VERSION ""

NS_ :

BS_:

BU_: VMCU TECU OBDScanT2 IC3 HPCU EMS ECUspare2 ECUspare1 DACU CIOM BBM

BO_ 826 VMCU_BB2_20P: 8 VMCU
 SG_ StartupProhibitStatus_ISig_4 : 8|2@1+ (1,0) [0|0] ""  BBM,IC3
 SG_ RampLevelStatus_ISig_4 : 32|4@1+ (1,0) [0|0] ""  IC3,CIOM
 SG_ KneelingInformation_ISig_4 : 42|4@1+ (1,0) [0|0] ""  BBM,IC3,CIOM
 SG_ FrontAxleInBumperRange_ISig_4 : 40|2@1+ (1,0) [0|0] ""  TECU
 SG_ FerryFunctionStatus_ISig_4 : 2|3@1+ (1,0) [0|0] ""  IC3,CIOM
 SG_ EngPtoConsumesTorque : 10|2@1+ (1,0) [0|0] ""  TECU
 SG_ LiftingControlModeRearAxle_ISig_ : 36|2@1+ (1,0) [0|0] ""  BBM
 SG_ KneelingStatusHMI_ISig_4 : 53|2@1+ (1,0) [0|0] ""  BBM,CIOM
 SG_ SWEngineStop_rqst_ISig_4 : 12|3@1+ (1,0) [0|0] ""  BBM
 SG_ FrontEndPositionStatus_ISig_4 : 18|3@1+ (1,0) [0|0] ""  CIOM
 SG_ LiftingControlModeFrontAxle_ISig : 30|2@1+ (1,0) [0|0] ""  BBM
 SG_ FrontAxleInBumperRange_UB_ISig_4 : 46|1@1+ (1,0) [0|0] ""  TECU,IC3
 SG_ UnevenLoadWarning_ISig_4 : 16|2@1+ (1,0) [0|0] ""  IC3
 SG_ RampHeightOutsideTargetRange_ISi : 27|3@1+ (1,0) [0|0] ""  IC3,CIOM
 SG_ DriveLevelPosUserInteraction_ISi : 48|3@1+ (1,0) [0|0] ""  IC3
 SG_ RearEndPositionStatus_ISig_4 : 24|3@1+ (1,0) [0|0] ""  TECU,CIOM
 SG_ ProhibitControlStatus_ISig_4 : 6|2@1+ (1,0) [0|0] ""  IC3,BBM
 SG_ ChangeKneelACK_ISig_4 : 51|2@1+ (1,0) [0|0] ""  CIOM
 SG_ ParkBrakeApplicationMode2 : 60|4@1+ (1,0) [0|0] ""  IC3
 SG_ RollEndPositionStatus_ISig_4 : 21|3@1+ (1,0) [0|0] ""  CIOM
 SG_ RearAxleInBumperRange_UB_ISig_4 : 47|1@1+ (1,0) [0|0] ""  TECU,IC3
 SG_ ParkBrakeReleaseMode2_ISig_4 : 56|4@1+ (1,0) [0|0] ""  IC3
 SG_ ECSStandbyAllowed_ISig_4 : 0|2@1+ (1,0) [0|0] ""  CIOM
 SG_ RearAxleInBumperRange_ISig_4 : 38|2@1+ (1,0) [0|0] ""  TECU

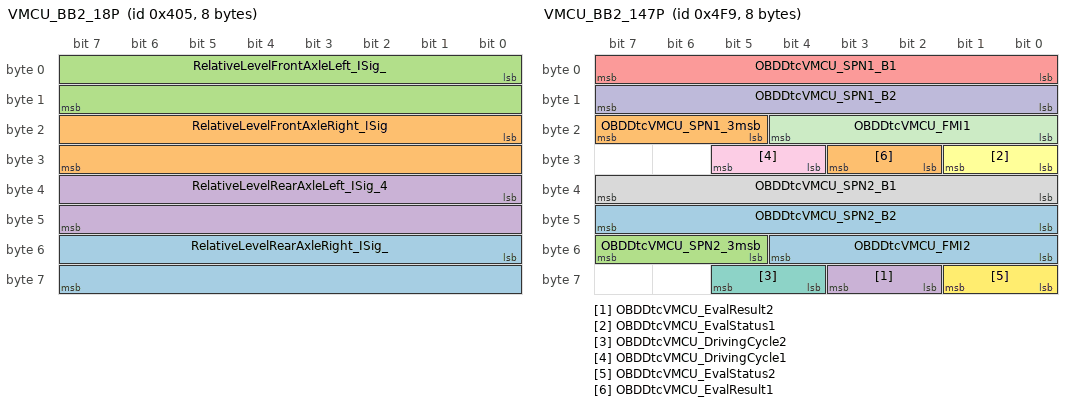
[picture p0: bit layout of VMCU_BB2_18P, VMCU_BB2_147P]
BO_ 1029 VMCU_BB2_18P: 8 VMCU
 SG_ RelativeLevelRearAxleRight_ISig_ : 48|16@1+ (0.1,-3200) [-3200|3353.5] "mm"  BBM
 SG_ RelativeLevelFrontAxleRight_ISig : 16|16@1+ (0.1,-3200) [-3200|3353.5] "mm"  BBM
 SG_ RelativeLevelFrontAxleLeft_ISig_ : 0|16@1+ (0.1,-3200) [-3200|3353.5] "mm"  BBM
 SG_ RelativeLevelRearAxleLeft_ISig_4 : 32|16@1+ (0.1,-3200) [-3200|3353.5] "mm"  BBM

BO_ 1207 VMCU_BB2_148P: 8 VMCU
 SG_ RelativeLevelFrontAxleLeftRaw_IS : 0|16@1+ (0.1,-3200) [-3200|3353.5] "mm"  DACU
 SG_ RelativeLevelFrontAxleRightRaw_I : 16|16@1+ (0.1,-3200) [-3200|3353.5] "mm"  DACU

BO_ 1273 VMCU_BB2_147P: 8 VMCU
 SG_ OBDDtcVMCU_SPN2_B2 : 40|8@1+ (1,0) [0|0] ""  EMS
 SG_ OBDDtcVMCU_SPN1_3msb : 21|3@1+ (1,0) [0|0] ""  EMS
 SG_ OBDDtcVMCU_SPN2_3msb : 53|3@1+ (1,0) [0|0] ""  EMS
 SG_ OBDDtcVMCU_EvalResult2 : 58|2@1+ (1,0) [0|0] ""  EMS
 SG_ OBDDtcVMCU_SPN1_B1 : 0|8@1+ (1,0) [0|0] ""  EMS
 SG_ OBDDtcVMCU_EvalStatus1 : 24|2@1+ (1,0) [0|0] ""  EMS
 SG_ OBDDtcVMCU_DrivingCycle2 : 60|2@1+ (1,0) [0|0] ""  EMS
 SG_ OBDDtcVMCU_SPN2_B1 : 32|8@1+ (1,0) [0|0] ""  EMS
 SG_ OBDDtcVMCU_DrivingCycle1 : 28|2@1+ (1,0) [0|0] ""  EMS
 SG_ OBDDtcVMCU_SPN1_B2 : 8|8@1+ (1,0) [0|0] ""  EMS
 SG_ OBDDtcVMCU_FMI1 : 16|5@1+ (1,0) [0|31] ""  EMS
 SG_ OBDDtcVMCU_EvalStatus2 : 56|2@1+ (1,0) [0|0] ""  EMS
 SG_ OBDDtcVMCU_FMI2 : 48|5@1+ (1,0) [0|31] ""  EMS
 SG_ OBDDtcVMCU_EvalResult1 : 26|2@1+ (1,0) [0|0] ""  EMS

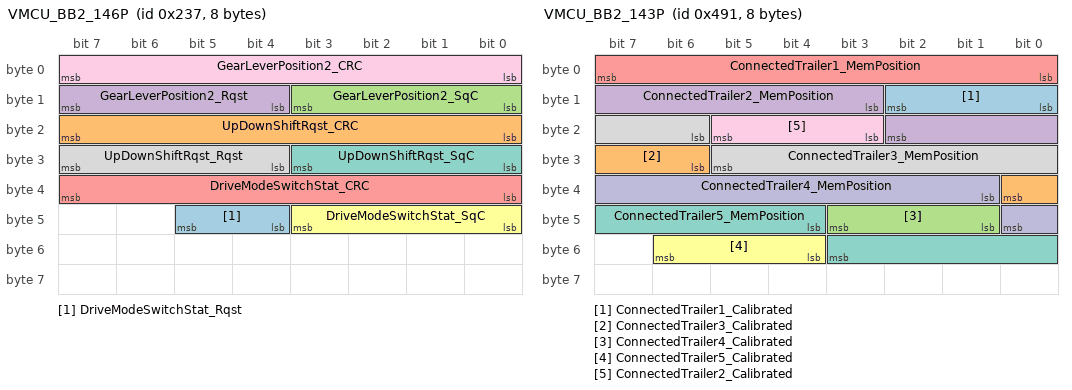
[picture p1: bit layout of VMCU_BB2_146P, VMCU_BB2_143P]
BO_ 567 VMCU_BB2_146P: 8 VMCU
 SG_ DriveModeSwitchStat_Rqst : 44|2@1+ (1,0) [0|0] ""  TECU
 SG_ UpDownShiftRqst_CRC : 16|8@1+ (1,0) [0|255] ""  TECU
 SG_ GearLeverPosition2_SqC : 8|4@1+ (1,0) [0|0] ""  TECU,IC3
 SG_ GearLeverPosition2_Rqst : 12|4@1+ (1,0) [0|0] ""  IC3,TECU
 SG_ DriveModeSwitchStat_CRC : 32|8@1+ (1,0) [0|255] ""  TECU
 SG_ DriveModeSwitchStat_SqC : 40|4@1+ (1,0) [0|0] ""  TECU
 SG_ UpDownShiftRqst_SqC : 24|4@1+ (1,0) [0|0] ""  TECU
 SG_ UpDownShiftRqst_Rqst : 28|4@1+ (1,0) [0|0] ""  TECU
 SG_ GearLeverPosition2_CRC : 0|8@1+ (1,0) [0|255] ""  TECU,IC3

BO_ 1483 VMCU_BB2_145S_FCM: 8 IC3
 SG_ VMCU_BB2_145S_FCS : 0|64@1+ (1,0) [0|0] ""  VMCU

BO_ 1482 VMCU_BB2_145S: 10 VMCU
 SG_ CalDataLoadTrlAxSumP2_YearUTC : 48|8@1+ (1,1985) [1985|2240] "Years"  IC3
 SG_ CalDataLoadTrlAxSumP2_ScaleLoad : 0|16@1+ (2,0) [0|131070] "kg"  IC3
 SG_ CalDataLoadTrlAxSumP2_DayUTC : 64|8@1+ (0.25,0) [0|63.75] "Days"  IC3
 SG_ CalDataLoadTrlAxSumP2_VehicleID : 72|3@1+ (1,0) [0|0] ""  IC3
 SG_ CalDataLoadTrlAxSumP2_QF : 32|16@1+ (1,0) [0|0] ""  IC3
 SG_ CalDataLoadTrlAxSumP2_MonthUTC : 56|8@1+ (1,0) [0|255] "Months"  IC3
 SG_ CalDataLoadTrlAxSumP2_UncalLoad : 16|16@1+ (2,0) [0|131070] "kg"  IC3

BO_ 1407 VMCU_BB2_144S_FCM: 8 IC3
 SG_ VMCU_BB2_144S_FCS : 0|64@1+ (1,0) [0|0] ""  VMCU

BO_ 1406 VMCU_BB2_144S: 10 VMCU
 SG_ CalDataLoadTrlAxSumP1_DayUTC : 64|8@1+ (0.25,0) [0|63.75] "Days"  IC3
 SG_ CalDataLoadTrlAxSumP1_YearUTC : 48|8@1+ (1,1985) [1985|2240] "Years"  IC3
 SG_ CalDataLoadTrlAxSumP1_VehicleID : 72|3@1+ (1,0) [0|0] ""  IC3
 SG_ CalDataLoadTrlAxSumP1_ScaleLoad : 0|16@1+ (2,0) [0|131070] "kg"  IC3
 SG_ CalDataLoadTrlAxSumP1_MonthUTC : 56|8@1+ (1,0) [0|255] "Months"  IC3
 SG_ CalDataLoadTrlAxSumP1_UncalLoad : 16|16@1+ (2,0) [0|131070] "kg"  IC3
 SG_ CalDataLoadTrlAxSumP1_QF : 32|16@1+ (1,0) [0|0] ""  IC3

BO_ 1169 VMCU_BB2_143P: 8 VMCU
 SG_ ConnectedTrailer1_Calibrated : 8|3@1+ (1,0) [0|0] ""  IC3
 SG_ ConnectedTrailer3_Calibrated : 30|3@1+ (1,0) [0|0] ""  IC3
 SG_ ConnectedTrailer4_Calibrated : 41|3@1+ (1,0) [0|0] ""  IC3
 SG_ ConnectedTrailer2_MemPosition : 11|8@1+ (1,0) [0|255] "NotApplicable"  IC3
 SG_ ConnectedTrailer1_MemPosition : 0|8@1+ (1,0) [0|255] "NotApplicable"  IC3
 SG_ ConnectedTrailer5_Calibrated : 52|3@1+ (1,0) [0|0] ""  IC3
 SG_ ConnectedTrailer5_MemPosition : 44|8@1+ (1,0) [0|255] "NotApplicable"  IC3
 SG_ ConnectedTrailer3_MemPosition : 22|8@1+ (1,0) [0|255] "NotApplicable"  IC3
 SG_ ConnectedTrailer2_Calibrated : 19|3@1+ (1,0) [0|0] ""  IC3
 SG_ ConnectedTrailer4_MemPosition : 33|8@1+ (1,0) [0|255] "NotApplicable"  IC3

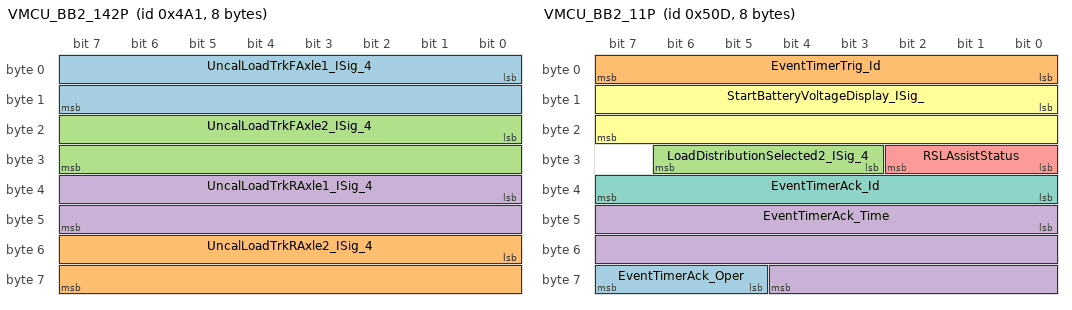
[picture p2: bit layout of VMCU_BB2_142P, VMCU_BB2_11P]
BO_ 1185 VMCU_BB2_142P: 8 VMCU
 SG_ UncalLoadTrkFAxle1_ISig_4 : 0|16@1+ (0.5,0) [0|32767.5] "kg"  IC3
 SG_ UncalLoadTrkRAxle2_ISig_4 : 48|16@1+ (0.5,0) [0|32767.5] "kg"  IC3
 SG_ UncalLoadTrkFAxle2_ISig_4 : 16|16@1+ (0.5,0) [0|32767.5] "kg"  IC3
 SG_ UncalLoadTrkRAxle1_ISig_4 : 32|16@1+ (0.5,0) [0|32767.5] "kg"  IC3

BO_ 1333 VMCU_BB2_141P: 8 VMCU
 SG_ SuspensionGCVW_ISig_4 : 32|16@1+ (10,0) [0|655350] "kg"  IC3
 SG_ SelectedLocalTimeOffset_stat_ISi : 0|32@1+ (1,-86400) [-86400|4294880895] "s"  IC3

BO_ 1597 VMCU_BB2_140P_FCM: 8 IC3
 SG_ VMCU_BB2_140P_FCS : 0|64@1+ (1,0) [0|0] ""  VMCU

BO_ 1596 VMCU_BB2_140P: 21 VMCU
 SG_ SavedUnit20_TrailerName : 0|160@1+ (1,0) [0|0] ""  IC3
 SG_ SavedUnit20_TrailerPosition : 160|3@1+ (1,0) [0|0] ""  IC3

BO_ 1595 VMCU_BB2_139P_FCM: 8 IC3
 SG_ VMCU_BB2_139P_FCS : 0|64@1+ (1,0) [0|0] ""  VMCU

BO_ 1594 VMCU_BB2_139P: 21 VMCU
 SG_ SavedUnit19_TrailerName : 0|160@1+ (1,0) [0|0] ""  IC3
 SG_ SavedUnit19_TrailerPosition : 160|3@1+ (1,0) [0|0] ""  IC3

BO_ 1593 VMCU_BB2_138P_FCM: 8 IC3
 SG_ VMCU_BB2_138P_FCS : 0|64@1+ (1,0) [0|0] ""  VMCU

BO_ 1592 VMCU_BB2_138P: 21 VMCU
 SG_ SavedUnit18_TrailerPosition : 160|3@1+ (1,0) [0|0] ""  IC3
 SG_ SavedUnit18_TrailerName : 0|160@1+ (1,0) [0|0] ""  IC3

BO_ 1591 VMCU_BB2_137P_FCM: 8 IC3
 SG_ VMCU_BB2_137P_FCS : 0|64@1+ (1,0) [0|0] ""  VMCU

BO_ 1590 VMCU_BB2_137P: 21 VMCU
 SG_ SavedUnit17_TrailerPosition : 160|3@1+ (1,0) [0|0] ""  IC3
 SG_ SavedUnit17_TrailerName : 0|160@1+ (1,0) [0|0] ""  IC3

BO_ 1589 VMCU_BB2_136P_FCM: 8 IC3
 SG_ VMCU_BB2_136P_FCS : 0|64@1+ (1,0) [0|0] ""  VMCU

BO_ 1588 VMCU_BB2_136P: 21 VMCU
 SG_ SavedUnit16_TrailerName : 0|160@1+ (1,0) [0|0] ""  IC3
 SG_ SavedUnit16_TrailerPosition : 160|3@1+ (1,0) [0|0] ""  IC3

BO_ 1587 VMCU_BB2_135P_FCM: 8 IC3
 SG_ VMCU_BB2_135P_FCS : 0|64@1+ (1,0) [0|0] ""  VMCU

BO_ 1586 VMCU_BB2_135P: 21 VMCU
 SG_ SavedUnit15_TrailerName : 0|160@1+ (1,0) [0|0] ""  IC3
 SG_ SavedUnit15_TrailerPosition : 160|3@1+ (1,0) [0|0] ""  IC3

BO_ 1585 VMCU_BB2_134P_FCM: 8 IC3
 SG_ VMCU_BB2_134P_FCS : 0|64@1+ (1,0) [0|0] ""  VMCU

BO_ 1584 VMCU_BB2_134P: 21 VMCU
 SG_ SavedUnit14_TrailerPosition : 160|3@1+ (1,0) [0|0] ""  IC3
 SG_ SavedUnit14_TrailerName : 0|160@1+ (1,0) [0|0] ""  IC3

BO_ 1577 VMCU_BB2_133P_FCM: 8 IC3
 SG_ VMCU_BB2_133P_FCS : 0|64@1+ (1,0) [0|0] ""  VMCU

BO_ 1576 VMCU_BB2_133P: 21 VMCU
 SG_ SavedUnit13_TrailerPosition : 160|3@1+ (1,0) [0|0] ""  IC3
 SG_ SavedUnit13_TrailerName : 0|160@1+ (1,0) [0|0] ""  IC3

BO_ 1575 VMCU_BB2_132P_FCM: 8 IC3
 SG_ VMCU_BB2_132P_FCS : 0|64@1+ (1,0) [0|0] ""  VMCU

BO_ 1574 VMCU_BB2_132P: 21 VMCU
 SG_ SavedUnit12_TrailerName : 0|160@1+ (1,0) [0|0] ""  IC3
 SG_ SavedUnit12_TrailerPosition : 160|3@1+ (1,0) [0|0] ""  IC3

BO_ 1573 VMCU_BB2_131P_FCM: 8 IC3
 SG_ VMCU_BB2_131P_FCS : 0|64@1+ (1,0) [0|0] ""  VMCU

BO_ 1572 VMCU_BB2_131P: 21 VMCU
 SG_ SavedUnit11_TrailerPosition : 160|3@1+ (1,0) [0|0] ""  IC3
 SG_ SavedUnit11_TrailerName : 0|160@1+ (1,0) [0|0] ""  IC3

BO_ 1571 VMCU_BB2_130P_FCM: 8 IC3
 SG_ VMCU_BB2_130P_FCS : 0|64@1+ (1,0) [0|0] ""  VMCU

BO_ 1570 VMCU_BB2_130P: 21 VMCU
 SG_ SavedUnit10_TrailerName : 0|160@1+ (1,0) [0|0] ""  IC3
 SG_ SavedUnit10_TrailerPosition : 160|3@1+ (1,0) [0|0] ""  IC3

BO_ 1569 VMCU_BB2_129P_FCM: 8 IC3
 SG_ VMCU_BB2_129P_FCS : 0|64@1+ (1,0) [0|0] ""  VMCU

BO_ 1568 VMCU_BB2_129P: 21 VMCU
 SG_ SavedUnit9_TrailerName : 0|160@1+ (1,0) [0|0] ""  IC3
 SG_ SavedUnit9_TrailerPosition : 160|3@1+ (1,0) [0|0] ""  IC3

BO_ 1567 VMCU_BB2_128P_FCM: 8 IC3
 SG_ VMCU_BB2_128P_FCS : 0|64@1+ (1,0) [0|0] ""  VMCU

BO_ 1566 VMCU_BB2_128P: 21 VMCU
 SG_ SavedUnit8_TrailerName : 0|160@1+ (1,0) [0|0] ""  IC3
 SG_ SavedUnit8_TrailerPosition : 160|3@1+ (1,0) [0|0] ""  IC3

BO_ 1565 VMCU_BB2_127P_FCM: 8 IC3
 SG_ VMCU_BB2_127P_FCS : 0|64@1+ (1,0) [0|0] ""  VMCU

BO_ 1564 VMCU_BB2_127P: 21 VMCU
 SG_ SavedUnit7_TrailerPosition : 160|3@1+ (1,0) [0|0] ""  IC3
 SG_ SavedUnit7_TrailerName : 0|160@1+ (1,0) [0|0] ""  IC3

BO_ 1563 VMCU_BB2_126P_FCM: 8 IC3
 SG_ VMCU_BB2_126P_FCS : 0|64@1+ (1,0) [0|0] ""  VMCU

BO_ 1562 VMCU_BB2_126P: 21 VMCU
 SG_ SavedUnit6_TrailerPosition : 160|3@1+ (1,0) [0|0] ""  IC3
 SG_ SavedUnit6_TrailerName : 0|160@1+ (1,0) [0|0] ""  IC3

BO_ 1561 VMCU_BB2_125P_FCM: 8 IC3
 SG_ VMCU_BB2_125P_FCS : 0|64@1+ (1,0) [0|0] ""  VMCU

BO_ 1560 VMCU_BB2_125P: 21 VMCU
 SG_ SavedUnit5_TrailerName : 0|160@1+ (1,0) [0|0] ""  IC3
 SG_ SavedUnit5_TrailerPosition : 160|3@1+ (1,0) [0|0] ""  IC3

BO_ 1559 VMCU_BB2_124P_FCM: 8 IC3
 SG_ VMCU_BB2_124P_FCS : 0|64@1+ (1,0) [0|0] ""  VMCU

BO_ 1558 VMCU_BB2_124P: 21 VMCU
 SG_ SavedUnit4_TrailerPosition : 160|3@1+ (1,0) [0|0] ""  IC3
 SG_ SavedUnit4_TrailerName : 0|160@1+ (1,0) [0|0] ""  IC3

BO_ 1557 VMCU_BB2_123P_FCM: 8 IC3
 SG_ VMCU_BB2_123P_FCS : 0|64@1+ (1,0) [0|0] ""  VMCU

BO_ 1556 VMCU_BB2_123P: 21 VMCU
 SG_ SavedUnit3_TrailerPosition : 160|3@1+ (1,0) [0|0] ""  IC3
 SG_ SavedUnit3_TrailerName : 0|160@1+ (1,0) [0|0] ""  IC3

BO_ 1555 VMCU_BB2_122P_FCM: 8 IC3
 SG_ VMCU_BB2_122P_FCS : 0|64@1+ (1,0) [0|0] ""  VMCU

BO_ 1554 VMCU_BB2_122P: 21 VMCU
 SG_ SavedUnit2_TrailerName : 0|160@1+ (1,0) [0|0] ""  IC3
 SG_ SavedUnit2_TrailerPosition : 160|3@1+ (1,0) [0|0] ""  IC3

BO_ 1553 VMCU_BB2_121P_FCM: 8 IC3
 SG_ VMCU_BB2_121P_FCS : 0|64@1+ (1,0) [0|0] ""  VMCU

BO_ 1552 VMCU_BB2_121P: 21 VMCU
 SG_ SavedUnit1_TrailerPosition : 160|3@1+ (1,0) [0|0] ""  IC3
 SG_ SavedUnit1_TrailerName : 0|160@1+ (1,0) [0|0] ""  IC3

BO_ 1293 VMCU_BB2_11P: 8 VMCU
 SG_ EventTimerAck_Oper : 61|3@1+ (1,0) [0|0] ""  IC3
 SG_ EventTimerTrig_Id : 0|8@1+ (1,0) [0|0] ""  IC3
 SG_ LoadDistributionSelected2_ISig_4 : 27|4@1+ (1,0) [0|0] ""  IC3
 SG_ EventTimerAck_Time : 40|21@1+ (1,0) [0|2097151] "s"  IC3
 SG_ RSLAssistStatus : 24|3@1+ (1,0) [0|0] ""  TECU
 SG_ StartBatteryVoltageDisplay_ISig_ : 8|16@1+ (0.05,0) [0|3276.75] "V"  IC3
 SG_ EventTimerAck_Id : 32|8@1+ (1,0) [0|0] ""  IC3

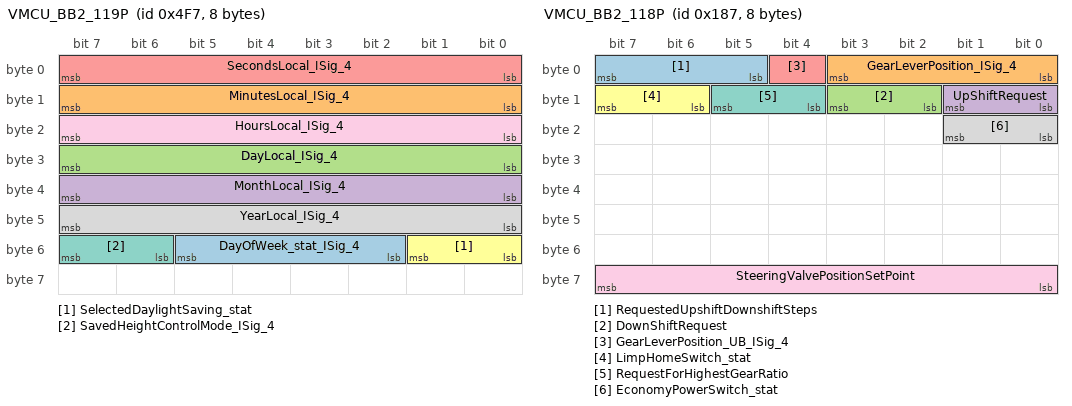
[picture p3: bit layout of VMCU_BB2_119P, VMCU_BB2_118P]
BO_ 1271 VMCU_BB2_119P: 8 VMCU
 SG_ DayOfWeek_stat_ISig_4 : 50|4@1+ (1,0) [0|0] ""  IC3,CIOM
 SG_ MinutesLocal_ISig_4 : 8|8@1+ (1,0) [0|255] "min"  IC3,CIOM
 SG_ DayLocal_ISig_4 : 24|8@1+ (0.25,0) [0|63.75] "Days"  IC3,CIOM
 SG_ MonthLocal_ISig_4 : 32|8@1+ (1,0) [0|255] "Months"  IC3,CIOM
 SG_ SecondsLocal_ISig_4 : 0|8@1+ (0.25,0) [0|63.75] "s"  IC3,CIOM
 SG_ SelectedDaylightSaving_stat : 48|2@1+ (1,0) [0|0] ""  IC3
 SG_ SavedHeightControlMode_ISig_4 : 54|2@1+ (1,0) [0|0] ""  TECU
 SG_ YearLocal_ISig_4 : 40|8@1+ (1,1985) [1985|2240] "Years"  CIOM,IC3
 SG_ HoursLocal_ISig_4 : 16|8@1+ (1,0) [0|255] "h"  IC3,CIOM

BO_ 391 VMCU_BB2_118P: 8 VMCU
 SG_ RequestedUpshiftDownshiftSteps : 5|3@1+ (1,0) [0|0] ""  TECU
 SG_ GearLeverPosition_ISig_4 : 0|4@1+ (1,0) [0|0] ""  TECU,BBM,DACU,IC3
 SG_ DownShiftRequest : 10|2@1+ (1,0) [0|0] ""  TECU
 SG_ UpShiftRequest : 8|2@1+ (1,0) [0|0] ""  TECU
 SG_ GearLeverPosition_UB_ISig_4 : 4|1@1+ (1,0) [0|0] ""  BBM,DACU,IC3,TECU
 SG_ LimpHomeSwitch_stat : 14|2@1+ (1,0) [0|0] ""  TECU
 SG_ RequestForHighestGearRatio : 12|2@1+ (1,0) [0|0] ""  TECU
 SG_ EconomyPowerSwitch_stat : 16|2@1+ (1,0) [0|0] ""  TECU
 SG_ SteeringValvePositionSetPoint : 56|8@1+ (1,0) [0|255] "Percent"  EMS

BO_ 1326 VMCU_BB2_116S_FCM: 8 IC3
 SG_ VMCU_BB2_116S_FCS : 0|64@1+ (1,0) [0|0] ""  VMCU

BO_ 1321 VMCU_BB2_116S: 12 VMCU
 SG_ CalDataLoadP5_ScaleLoad_ISig_4 : 63|16@1+ (0.5,0) [0|32767.5] "kg"  IC3
 SG_ CalDataLoadP5_UncalLoad_ISig_4 : 47|16@1+ (0.5,0) [0|32767.5] "kg"  IC3
 SG_ CalDataLoadP5_sg_UB_ISig_4 : 95|1@1+ (1,0) [0|0] ""  IC3
 SG_ CalDataLoadP5_YearUTC_ISig_4 : 23|8@1+ (1,1985) [1985|2240] "Years"  IC3
 SG_ CalDataLoadP5_VehicleID_ISig_4 : 4|3@1+ (1,0) [0|0] ""  IC3
 SG_ CalDataLoadP5_AxleID_ISig_4 : 0|4@1+ (1,0) [0|0] ""  IC3
 SG_ CalDataLoadP5_DayUTC_ISig_4 : 15|8@1+ (0.25,0) [0|63.75] "Days"  IC3
 SG_ CalDataLoadP5_HoursUTC_ISig_4 : 31|8@1+ (1,0) [0|255] "h"  IC3
 SG_ CalDataLoadP5_MinutesUTC_ISig_4 : 39|8@1+ (1,0) [0|255] "min"  IC3
 SG_ CalDataLoadP5_QF_ISig_4 : 79|16@1+ (1,0) [0|0] ""  IC3
 SG_ CalDataLoadP5_MonthUTC_ISig_4 : 7|8@1+ (1,0) [0|255] "Months"  IC3

BO_ 1325 VMCU_BB2_115S_FCM: 8 IC3
 SG_ VMCU_BB2_115S_FCS : 0|64@1+ (1,0) [0|0] ""  VMCU

BO_ 1320 VMCU_BB2_115S: 12 VMCU
 SG_ CalDataLoadP4_DayUTC_ISig_4 : 7|8@1+ (0.25,0) [0|63.75] "Days"  IC3
 SG_ CalDataLoadP4_ScaleLoad_ISig_4 : 47|16@1+ (0.5,0) [0|32767.5] "kg"  IC3
 SG_ CalDataLoadP4_sg_UB_ISig_4 : 95|1@1+ (1,0) [0|0] ""  IC3
 SG_ CalDataLoadP4_YearUTC_ISig_4 : 23|8@1+ (1,1985) [1985|2240] "Years"  IC3
 SG_ CalDataLoadP4_AxleID_ISig_4 : 0|4@1+ (1,0) [0|0] ""  IC3
 SG_ CalDataLoadP4_UncalLoad_ISig_4 : 63|16@1+ (0.5,0) [0|32767.5] "kg"  IC3
 SG_ CalDataLoadP4_VehicleID_ISig_4 : 4|3@1+ (1,0) [0|0] ""  IC3
 SG_ CalDataLoadP4_MinutesUTC_ISig_4 : 39|8@1+ (1,0) [0|255] "min"  IC3
 SG_ CalDataLoadP4_HoursUTC_ISig_4 : 15|8@1+ (1,0) [0|255] "h"  IC3
 SG_ CalDataLoadP4_MonthUTC_ISig_4 : 31|8@1+ (1,0) [0|255] "Months"  IC3
 SG_ CalDataLoadP4_QF_ISig_4 : 79|16@1+ (1,0) [0|0] ""  IC3

BO_ 1324 VMCU_BB2_114S_FCM: 8 IC3
 SG_ VMCU_BB2_114S_FCS : 0|64@1+ (1,0) [0|0] ""  VMCU

BO_ 1319 VMCU_BB2_114S: 12 VMCU
 SG_ CalDataLoadP3_HoursUTC_ISig_4 : 15|8@1+ (1,0) [0|255] "h"  IC3
 SG_ CalDataLoadP3_YearUTC_ISig_4 : 7|8@1+ (1,1985) [1985|2240] "Years"  IC3
 SG_ CalDataLoadP3_MonthUTC_ISig_4 : 39|8@1+ (1,0) [0|255] "Months"  IC3
 SG_ CalDataLoadP3_DayUTC_ISig_4 : 23|8@1+ (0.25,0) [0|63.75] "Days"  IC3
 SG_ CalDataLoadP3_sg_UB_ISig_4 : 95|1@1+ (1,0) [0|0] ""  IC3
 SG_ CalDataLoadP3_MinutesUTC_ISig_4 : 31|8@1+ (1,0) [0|255] "min"  IC3
 SG_ CalDataLoadP3_QF_ISig_4 : 79|16@1+ (1,0) [0|0] ""  IC3
 SG_ CalDataLoadP3_VehicleID_ISig_4 : 4|3@1+ (1,0) [0|0] ""  IC3
 SG_ CalDataLoadP3_UncalLoad_ISig_4 : 63|16@1+ (0.5,0) [0|32767.5] "kg"  IC3
 SG_ CalDataLoadP3_AxleID_ISig_4 : 0|4@1+ (1,0) [0|0] ""  IC3
 SG_ CalDataLoadP3_ScaleLoad_ISig_4 : 47|16@1+ (0.5,0) [0|32767.5] "kg"  IC3

BO_ 1323 VMCU_BB2_113S_FCM: 8 IC3
 SG_ VMCU_BB2_113S_FCS : 0|64@1+ (1,0) [0|0] ""  VMCU

BO_ 1318 VMCU_BB2_113S: 12 VMCU
 SG_ CalDataLoadP2_MinutesUTC_ISig_4 : 39|8@1+ (1,0) [0|255] "min"  IC3
 SG_ CalDataLoadP2_AxleID_ISig_4 : 0|4@1+ (1,0) [0|0] ""  IC3
 SG_ CalDataLoadP2_YearUTC_ISig_4 : 15|8@1+ (1,1985) [1985|2240] "Years"  IC3
 SG_ CalDataLoadP2_UncalLoad_ISig_4 : 63|16@1+ (0.5,0) [0|32767.5] "kg"  IC3
 SG_ CalDataLoadP2_DayUTC_ISig_4 : 23|8@1+ (0.25,0) [0|63.75] "Days"  IC3
 SG_ CalDataLoadP2_MonthUTC_ISig_4 : 7|8@1+ (1,0) [0|255] "Months"  IC3
 SG_ CalDataLoadP2_VehicleID_ISig_4 : 4|3@1+ (1,0) [0|0] ""  IC3
 SG_ CalDataLoadP2_QF_ISig_4 : 79|16@1+ (1,0) [0|0] ""  IC3
 SG_ CalDataLoadP2_HoursUTC_ISig_4 : 31|8@1+ (1,0) [0|255] "h"  IC3
 SG_ CalDataLoadP2_sg_UB_ISig_4 : 95|1@1+ (1,0) [0|0] ""  IC3
 SG_ CalDataLoadP2_ScaleLoad_ISig_4 : 47|16@1+ (0.5,0) [0|32767.5] "kg"  IC3

BO_ 1322 VMCU_BB2_112S_FCM: 8 IC3
 SG_ VMCU_BB2_112S_FCS : 0|64@1+ (1,0) [0|0] ""  VMCU

BO_ 1317 VMCU_BB2_112S: 12 VMCU
 SG_ CalDataLoadP1_ScaleLoad_ISig_4 : 47|16@1+ (0.5,0) [0|32767.5] "kg"  IC3
 SG_ CalDataLoadP1_YearUTC_ISig_4 : 31|8@1+ (1,1985) [1985|2240] "Years"  IC3
 SG_ CalDataLoadP1_AxleID_ISig_4 : 0|4@1+ (1,0) [0|0] ""  IC3
 SG_ CalDataLoadP1_MonthUTC_ISig_4 : 39|8@1+ (1,0) [0|255] "Months"  IC3
 SG_ CalDataLoadP1_HoursUTC_ISig_4 : 7|8@1+ (1,0) [0|255] "h"  IC3
 SG_ CalDataLoadP1_VehicleID_ISig_4 : 4|3@1+ (1,0) [0|0] ""  IC3
 SG_ CalDataLoadP1_UncalLoad_ISig_4 : 63|16@1+ (0.5,0) [0|32767.5] "kg"  IC3
 SG_ CalDataLoadP1_QF_ISig_4 : 79|16@1+ (1,0) [0|0] ""  IC3
 SG_ CalDataLoadP1_DayUTC_ISig_4 : 23|8@1+ (0.25,0) [0|63.75] "Days"  IC3
 SG_ CalDataLoadP1_sg_UB_ISig_4 : 95|1@1+ (1,0) [0|0] ""  IC3
 SG_ CalDataLoadP1_MinutesUTC_ISig_4 : 15|8@1+ (1,0) [0|255] "min"  IC3

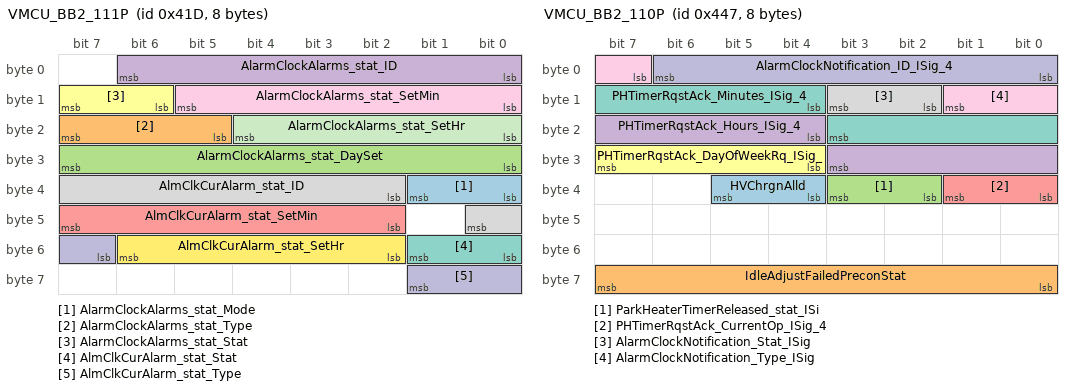
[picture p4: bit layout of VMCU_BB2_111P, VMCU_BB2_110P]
BO_ 1053 VMCU_BB2_111P: 8 VMCU
 SG_ AlarmClockAlarms_stat_Mode : 32|2@1+ (1,0) [0|0] ""  IC3
 SG_ AlarmClockAlarms_stat_Type : 21|3@1+ (1,0) [0|0] ""  IC3
 SG_ AlarmClockAlarms_stat_DaySet : 24|8@1+ (1,0) [0|255] ""  IC3
 SG_ AlarmClockAlarms_stat_ID : 0|7@1+ (1,0) [0|0] ""  IC3
 SG_ AlmClkCurAlarm_stat_SetMin : 42|6@1+ (1,0) [0|63] "min"  IC3,CIOM
 SG_ AlarmClockAlarms_stat_Stat : 14|2@1+ (1,0) [0|0] ""  IC3
 SG_ AlmClkCurAlarm_stat_Stat : 48|2@1+ (1,0) [0|0] ""  CIOM,IC3
 SG_ AlmClkCurAlarm_stat_ID : 34|7@1+ (1,0) [0|0] ""  IC3,CIOM
 SG_ AlarmClockAlarms_stat_SetMin : 8|6@1+ (1,0) [0|63] "min"  IC3
 SG_ AlmClkCurAlarm_stat_Type : 55|3@1+ (1,0) [0|0] ""  IC3,CIOM
 SG_ AlarmClockAlarms_stat_SetHr : 16|5@1+ (1,0) [0|31] "h"  IC3
 SG_ AlmClkCurAlarm_stat_SetHr : 50|5@1+ (1,0) [0|31] "h"  IC3,CIOM

BO_ 1095 VMCU_BB2_110P: 8 VMCU
 SG_ HVChrgnAlld : 36|2@1+ (1,0) [0|0] ""  HPCU
 SG_ IdleAdjustFailedPreconStat : 56|8@1+ (1,0) [0|0] ""  IC3
 SG_ ParkHeaterTimerReleased_stat_ISi : 34|2@1+ (1,0) [0|0] ""  CIOM
 SG_ PHTimerRqstAck_Hours_ISig_4 : 20|8@1+ (1,0) [0|255] "h"  CIOM
 SG_ PHTimerRqstAck_CurrentOp_ISig_4 : 32|2@1+ (1,0) [0|0] ""  CIOM
 SG_ PHTimerRqstAck_DayOfWeekRq_ISig_ : 28|4@1+ (1,0) [0|0] ""  CIOM
 SG_ PHTimerRqstAck_Minutes_ISig_4 : 12|8@1+ (1,0) [0|255] "min"  CIOM
 SG_ AlarmClockNotification_Stat_ISig : 10|2@1+ (1,0) [0|0] ""  CIOM,IC3
 SG_ AlarmClockNotification_Type_ISig : 7|3@1+ (1,0) [0|0] ""  IC3,CIOM
 SG_ AlarmClockNotification_ID_ISig_4 : 0|7@1+ (1,0) [0|0] ""  IC3,CIOM

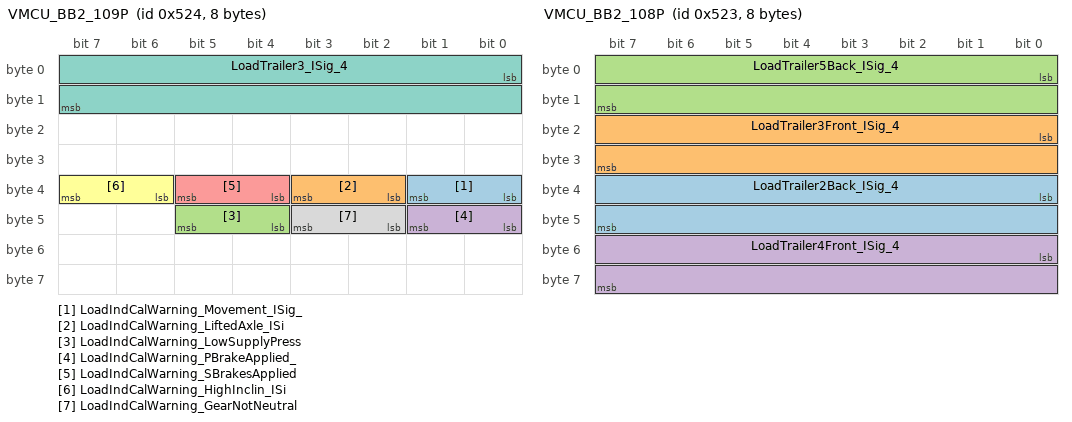
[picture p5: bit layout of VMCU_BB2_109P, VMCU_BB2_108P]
BO_ 1316 VMCU_BB2_109P: 8 VMCU
 SG_ LoadIndCalWarning_Movement_ISig_ : 32|2@1+ (1,0) [0|0] ""  IC3
 SG_ LoadIndCalWarning_LiftedAxle_ISi : 34|2@1+ (1,0) [0|0] ""  IC3
 SG_ LoadIndCalWarning_LowSupplyPress : 44|2@1+ (1,0) [0|0] ""  IC3
 SG_ LoadIndCalWarning_PBrakeApplied_ : 40|2@1+ (1,0) [0|0] ""  IC3
 SG_ LoadIndCalWarning_SBrakesApplied : 36|2@1+ (1,0) [0|0] ""  IC3
 SG_ LoadIndCalWarning_HighInclin_ISi : 38|2@1+ (1,0) [0|0] ""  IC3
 SG_ LoadTrailer3_ISig_4 : 0|16@1+ (2,0) [0|131070] "kg"  IC3,BBM,CIOM
 SG_ LoadIndCalWarning_GearNotNeutral : 42|2@1+ (1,0) [0|0] ""  IC3

BO_ 1315 VMCU_BB2_108P: 8 VMCU
 SG_ LoadTrailer2Back_ISig_4 : 32|16@1+ (2,0) [0|131070] "kg"  IC3
 SG_ LoadTrailer3Front_ISig_4 : 16|16@1+ (2,0) [0|131070] "kg"  IC3
 SG_ LoadTrailer5Back_ISig_4 : 0|16@1+ (2,0) [0|131070] "kg"  IC3
 SG_ LoadTrailer4Front_ISig_4 : 48|16@1+ (2,0) [0|131070] "kg"  IC3

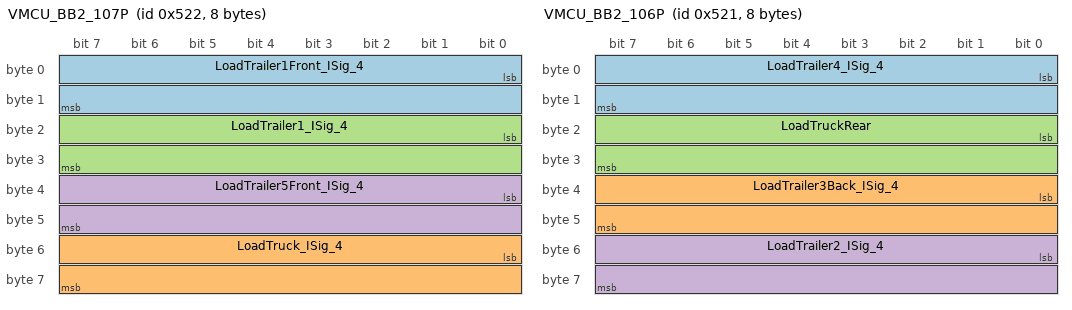
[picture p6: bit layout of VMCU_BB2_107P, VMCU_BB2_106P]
BO_ 1314 VMCU_BB2_107P: 8 VMCU
 SG_ LoadTrailer1Front_ISig_4 : 0|16@1+ (2,0) [0|131070] "kg"  IC3
 SG_ LoadTruck_ISig_4 : 48|16@1+ (2,0) [0|131070] "kg"  IC3,CIOM,DACU,BBM
 SG_ LoadTrailer1_ISig_4 : 16|16@1+ (2,0) [0|131070] "kg"  BBM,IC3,CIOM
 SG_ LoadTrailer5Front_ISig_4 : 32|16@1+ (2,0) [0|131070] "kg"  IC3

BO_ 1313 VMCU_BB2_106P: 8 VMCU
 SG_ LoadTrailer4_ISig_4 : 0|16@1+ (2,0) [0|131070] "kg"  IC3,BBM,CIOM
 SG_ LoadTrailer3Back_ISig_4 : 32|16@1+ (2,0) [0|131070] "kg"  IC3
 SG_ LoadTruckRear : 16|16@1+ (2,0) [0|131070] "kg"  IC3
 SG_ LoadTrailer2_ISig_4 : 48|16@1+ (2,0) [0|131070] "kg"  BBM,CIOM,IC3

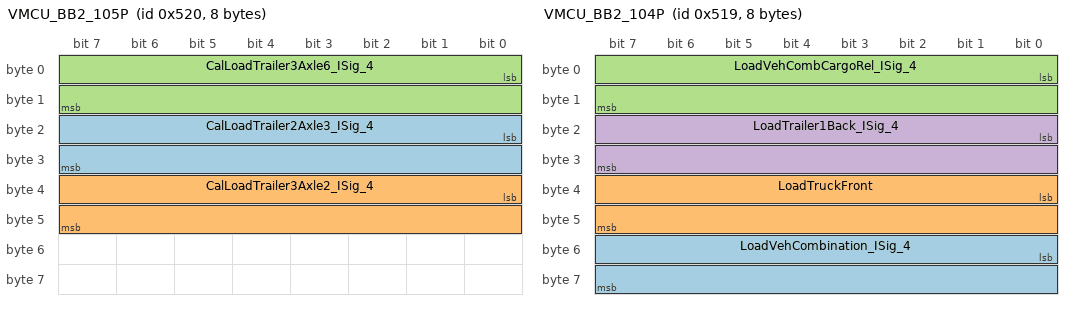
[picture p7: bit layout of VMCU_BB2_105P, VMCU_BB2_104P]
BO_ 1312 VMCU_BB2_105P: 8 VMCU
 SG_ CalLoadTrailer2Axle3_ISig_4 : 16|16@1+ (0.5,0) [0|32767.5] "kg"  IC3,CIOM,BBM
 SG_ CalLoadTrailer3Axle2_ISig_4 : 32|16@1+ (0.5,0) [0|32767.5] "kg"  IC3,CIOM
 SG_ CalLoadTrailer3Axle6_ISig_4 : 0|16@1+ (0.5,0) [0|32767.5] "kg"  IC3,CIOM

BO_ 1305 VMCU_BB2_104P: 8 VMCU
 SG_ LoadVehCombination_ISig_4 : 48|16@1+ (10,0) [0|655350] "kg"  BBM,IC3
 SG_ LoadTruckFront : 32|16@1+ (2,0) [0|131070] "kg"  IC3
 SG_ LoadVehCombCargoRel_ISig_4 : 0|16@1+ (10,-321270) [-321270|334080] "kg"  BBM,IC3
 SG_ LoadTrailer1Back_ISig_4 : 16|16@1+ (2,0) [0|131070] "kg"  IC3

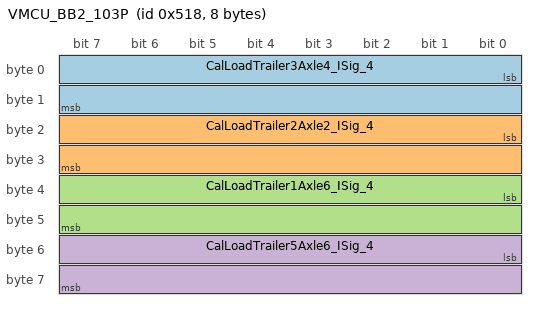
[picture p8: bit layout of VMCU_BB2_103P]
BO_ 1304 VMCU_BB2_103P: 8 VMCU
 SG_ CalLoadTrailer3Axle4_ISig_4 : 0|16@1+ (0.5,0) [0|32767.5] "kg"  CIOM,IC3
 SG_ CalLoadTrailer2Axle2_ISig_4 : 16|16@1+ (0.5,0) [0|32767.5] "kg"  CIOM,IC3,BBM
 SG_ CalLoadTrailer1Axle6_ISig_4 : 32|16@1+ (0.5,0) [0|32767.5] "kg"  CIOM,IC3
 SG_ CalLoadTrailer5Axle6_ISig_4 : 48|16@1+ (0.5,0) [0|32767.5] "kg"  CIOM,IC3

CM_ SG_ 1029 RelativeLevelRearAxleRight_ISig_ "65024 - 65279 Error ; 65280 - 65535 Not available";
CM_ SG_ 1029 RelativeLevelFrontAxleRight_ISig "65024 - 65279 Error ; 65280 - 65535 Not available";
CM_ SG_ 1029 RelativeLevelFrontAxleLeft_ISig_ "65024 - 65279 Error ; 65280 - 65535 Not available";
CM_ SG_ 1029 RelativeLevelRearAxleLeft_ISig_4 "65024 - 65279 Error ; 65280 - 65535 Not available";
CM_ SG_ 1333 SuspensionGCVW_ISig_4 "64256 - 65023 Calculating; 65024 - 65279 Error; 65280 - 65535 NotAvailable;";
CM_ SG_ 1271 MinutesLocal_ISig_4 "254 Error ; 255 Not available";
CM_ SG_ 1271 DayLocal_ISig_4 "254 Error ; 255 Not available";
CM_ SG_ 1271 MonthLocal_ISig_4 "254 Error ; 255 Not available";
CM_ SG_ 1271 SecondsLocal_ISig_4 "254 Error ; 255 Not available";
CM_ SG_ 1271 YearLocal_ISig_4 "254 Error ; 255 Not available";
CM_ SG_ 1271 HoursLocal_ISig_4 "254 Error ; 255 Not available";
CM_ SG_ 1053 AlmClkCurAlarm_stat_SetMin "62 Error ; 63 Not Available";
CM_ SG_ 1053 AlarmClockAlarms_stat_SetMin "62 Error ; 63 Not Available";
CM_ SG_ 1053 AlarmClockAlarms_stat_SetHr "30 Error ; 31 Not Available";
CM_ SG_ 1053 AlmClkCurAlarm_stat_SetHr "30 Error ; 31 Not Available";
CM_ SG_ 1316 LoadTrailer3_ISig_4 "65024 - 65279 Error ; 65280 - 65535 Not Available";
CM_ SG_ 1314 LoadTruck_ISig_4 "65024 - 65279 Error ; 65280 - 65535 Not Available";
CM_ SG_ 1314 LoadTrailer1_ISig_4 "65024 - 65279 Error ; 65280 - 65535 Not Available";
CM_ SG_ 1313 LoadTrailer4_ISig_4 "65024 - 65279 Error ; 65280 - 65535 Not Available";
CM_ SG_ 1313 LoadTrailer2_ISig_4 "65024 - 65279 Error ; 65280 - 65535 Not Available";
CM_ SG_ 1312 CalLoadTrailer2Axle3_ISig_4 "65024 - 65279 Error ; 65280 - 65535 Not available";
CM_ SG_ 1312 CalLoadTrailer3Axle2_ISig_4 "65024 - 65279 Error ; 65280 - 65535 Not available";
CM_ SG_ 1312 CalLoadTrailer3Axle6_ISig_4 "65024 - 65279 Error ; 65280 - 65535 Not available";
CM_ SG_ 1304 CalLoadTrailer3Axle4_ISig_4 "65024 - 65279 Error ; 65280 - 65535 Not available";
CM_ SG_ 1304 CalLoadTrailer2Axle2_ISig_4 "65024 - 65279 Error ; 65280 - 65535 Not available";
CM_ SG_ 1304 CalLoadTrailer1Axle6_ISig_4 "65024 - 65279 Error ; 65280 - 65535 Not available";
CM_ SG_ 1304 CalLoadTrailer5Axle6_ISig_4 "65024 - 65279 Error ; 65280 - 65535 Not available";
BA_DEF_ BO_  "GenMsgStartDelayTime" INT 0 0;
BA_DEF_ BO_  "GenMsgDelayTime" INT 0 0;
BA_DEF_ BO_  "GenMsgCycleTime" INT 0 0;
BA_DEF_ BO_  "GenMsgSendType" ENUM  "Cyclic","NotUsed","NotUsed","NotUsed","NotUsed","NotUsed","NotUsed","IfActive","NoMsgSendType","NotUsed";
BA_DEF_ SG_  "GenSigStartValue" INT 0 0;
BA_DEF_ SG_  "GenSigCycleTimeActive" INT 0 0;
BA_DEF_ SG_  "GenSigCycleTime" INT 0 0;
BA_DEF_ SG_  "GenSigSendType" ENUM  "Cyclic","OnWrite","OnWriteWithRepetition","OnChange","OnChangeWithRepetition","IfActive","IfActiveWithRepetition","NoSigSendType","NotUsed","NotUsed","NotUsed","NotUsed","NotUsed";
BA_DEF_ BO_  "VFrameFormat" ENUM  "StandardCAN","ExtendedCAN","reserved","J1939PG","reserved","reserved","reserved","reserved","reserved","reserved","reserved","reserved","reserved","reserved","StandardCAN_FD","ExtendedCAN_FD";
BA_DEF_ SG_  "SigType" ENUM  "Default","Range","RangeSigned","ASCII","Discrete","Control","ReferencePGN","DTC","StringDelimiter","StringLength","StringLengthControl";
BA_DEF_ SG_  "SeToolVersion_SIGNAL" STRING ;
BA_DEF_ SG_  "SeToolUniqueID_SIGNAL" STRING ;
BA_DEF_ SG_  "SeToolOwnerSigGroup_SIGNAL" STRING ;
BA_DEF_ SG_  "SeToolOwnerSigGroupID_SIGNAL" STRING ;
BA_DEF_ SG_  "SeToolName_SIGNAL" STRING ;
BA_DEF_ SG_  "SeToolItemID_SIGNAL" STRING ;
BA_DEF_ SG_  "SeToolAncestorID_SIGNAL" STRING ;
BA_DEF_ SG_  "Platform_VMCU1_Sig" ENUM  "No","Yes";
BA_DEF_ SG_  "Platform_FactoryIf_Sig" ENUM  "No","Yes";
BA_DEF_ BO_  "NmAsrMessage" ENUM  "No","Yes";
BA_DEF_ SG_  "NeedsUpdateBit" ENUM  "No","Yes";
BA_DEF_ SG_  "MmAnSignal" ENUM  "No","Yes";
BA_DEF_ SG_  "GenSigMaxLatency" INT 0 65535;
BA_DEF_ SG_  "GenSigILSupport" ENUM  "Yes","No";
BA_DEF_ BO_  "GenMsgILSupport" ENUM  "No","Yes";
BA_DEF_ BO_  "DiagUUDTResponse" ENUM  "No","Yes";
BA_DEF_ BO_  "DiagState" ENUM  "No","Yes";
BA_DEF_ BO_  "DiagResponse" ENUM  "No","Yes";
BA_DEF_ BO_  "DiagRequest" ENUM  "No","Yes";
BA_DEF_ BO_  "DiagConnection" HEX 0 65535;
BA_DEF_ BO_  "CanTpSTmin" INT 0 255;
BA_DEF_ BO_  "CanTpFcFrameId" HEX 0 2147483647;
BA_DEF_ BO_  "CanTpBs" INT 0 255;
BA_DEF_ SG_  "SystemSignalLongSymbol" STRING ;
BA_DEF_REL_ BU_SG_REL_  "GenSigTimeoutTime" INT 0 65535;
BA_DEF_REL_ BU_SG_REL_  "GenSigFirstTimeoutTime" INT 0 65535;
BA_DEF_DEF_  "GenMsgStartDelayTime" 0;
BA_DEF_DEF_  "GenMsgDelayTime" 0;
BA_DEF_DEF_  "GenMsgCycleTime" 0;
BA_DEF_DEF_  "GenMsgSendType" "Cyclic";
BA_DEF_DEF_  "GenSigStartValue" 0;
BA_DEF_DEF_  "GenSigCycleTimeActive" 0;
BA_DEF_DEF_  "GenSigCycleTime" 0;
BA_DEF_DEF_  "GenSigSendType" "Cyclic";
BA_DEF_DEF_  "VFrameFormat" "ExtendedCAN";
BA_DEF_DEF_  "SigType" "Default";
BA_DEF_DEF_  "SeToolVersion_SIGNAL" "";
BA_DEF_DEF_  "SeToolUniqueID_SIGNAL" "";
BA_DEF_DEF_  "SeToolOwnerSigGroup_SIGNAL" "";
BA_DEF_DEF_  "SeToolOwnerSigGroupID_SIGNAL" "";
BA_DEF_DEF_  "SeToolName_SIGNAL" "";
BA_DEF_DEF_  "SeToolItemID_SIGNAL" "";
BA_DEF_DEF_  "SeToolAncestorID_SIGNAL" "";
BA_DEF_DEF_  "Platform_VMCU1_Sig" "No";
BA_DEF_DEF_  "Platform_FactoryIf_Sig" "No";
BA_DEF_DEF_  "NmAsrMessage" "No";
BA_DEF_DEF_  "NeedsUpdateBit" "No";
BA_DEF_DEF_  "MmAnSignal" "No";
BA_DEF_DEF_  "GenSigMaxLatency" 0;
BA_DEF_DEF_  "GenSigILSupport" "Yes";
BA_DEF_DEF_  "GenMsgILSupport" "Yes";
BA_DEF_DEF_  "DiagUUDTResponse" "No";
BA_DEF_DEF_  "DiagState" "No";
BA_DEF_DEF_  "DiagResponse" "No";
BA_DEF_DEF_  "DiagRequest" "No";
BA_DEF_DEF_  "DiagConnection" 0;
BA_DEF_DEF_  "CanTpSTmin" 0;
BA_DEF_DEF_  "CanTpFcFrameId" 2147483647;
BA_DEF_DEF_  "CanTpBs" 255;
BA_DEF_DEF_REL_ "GenSigTimeoutTime" 0;
BA_DEF_DEF_REL_ "GenSigFirstTimeoutTime" 0;
BA_DEF_DEF_  "SystemSignalLongSymbol" "";
BA_ "VFrameFormat" BO_ 826 0;
BA_ "GenMsgCycleTime" BO_ 826 50;
BA_ "GenMsgStartDelayTime" BO_ 826 20;
BA_ "VFrameFormat" BO_ 1029 0;
BA_ "GenMsgCycleTime" BO_ 1029 100;
BA_ "GenMsgStartDelayTime" BO_ 1029 15;
BA_ "VFrameFormat" BO_ 1207 0;
BA_ "GenMsgCycleTime" BO_ 1207 100;
BA_ "VFrameFormat" BO_ 1273 0;
BA_ "GenMsgCycleTime" BO_ 1273 500;
BA_ "GenMsgStartDelayTime" BO_ 1273 125;
BA_ "VFrameFormat" BO_ 567 0;
BA_ "GenMsgCycleTime" BO_ 567 20;
BA_ "GenMsgStartDelayTime" BO_ 567 15;
BA_ "GenMsgILSupport" BO_ 1483 0;
BA_ "VFrameFormat" BO_ 1483 0;
BA_ "GenMsgSendType" BO_ 1483 8;
BA_ "CanTpFcFrameId" BO_ 1482 1483;
BA_ "VFrameFormat" BO_ 1482 0;
BA_ "GenMsgSendType" BO_ 1482 8;
BA_ "GenMsgDelayTime" BO_ 1482 20;
BA_ "GenMsgStartDelayTime" BO_ 1482 50;
BA_ "GenMsgILSupport" BO_ 1407 0;
BA_ "VFrameFormat" BO_ 1407 0;
BA_ "GenMsgSendType" BO_ 1407 8;
BA_ "CanTpFcFrameId" BO_ 1406 1407;
BA_ "VFrameFormat" BO_ 1406 0;
BA_ "GenMsgSendType" BO_ 1406 8;
BA_ "GenMsgDelayTime" BO_ 1406 20;
BA_ "GenMsgStartDelayTime" BO_ 1406 50;
BA_ "VFrameFormat" BO_ 1169 0;
BA_ "GenMsgCycleTime" BO_ 1169 500;
BA_ "GenMsgStartDelayTime" BO_ 1169 155;
BA_ "VFrameFormat" BO_ 1185 0;
BA_ "GenMsgCycleTime" BO_ 1185 500;
BA_ "GenMsgStartDelayTime" BO_ 1185 140;
BA_ "VFrameFormat" BO_ 1333 0;
BA_ "GenMsgCycleTime" BO_ 1333 1000;
BA_ "GenMsgILSupport" BO_ 1597 0;
BA_ "VFrameFormat" BO_ 1597 0;
BA_ "GenMsgSendType" BO_ 1597 8;
BA_ "CanTpFcFrameId" BO_ 1596 1597;
BA_ "VFrameFormat" BO_ 1596 0;
BA_ "GenMsgCycleTime" BO_ 1596 10000;
BA_ "GenMsgStartDelayTime" BO_ 1596 2250;
BA_ "GenMsgILSupport" BO_ 1595 0;
BA_ "VFrameFormat" BO_ 1595 0;
BA_ "GenMsgSendType" BO_ 1595 8;
BA_ "CanTpFcFrameId" BO_ 1594 1595;
BA_ "VFrameFormat" BO_ 1594 0;
BA_ "GenMsgCycleTime" BO_ 1594 10000;
BA_ "GenMsgStartDelayTime" BO_ 1594 2155;
BA_ "GenMsgILSupport" BO_ 1593 0;
BA_ "VFrameFormat" BO_ 1593 0;
BA_ "GenMsgSendType" BO_ 1593 8;
BA_ "CanTpFcFrameId" BO_ 1592 1593;
BA_ "VFrameFormat" BO_ 1592 0;
BA_ "GenMsgCycleTime" BO_ 1592 10000;
BA_ "GenMsgStartDelayTime" BO_ 1592 2050;
BA_ "GenMsgILSupport" BO_ 1591 0;
BA_ "VFrameFormat" BO_ 1591 0;
BA_ "GenMsgSendType" BO_ 1591 8;
BA_ "CanTpFcFrameId" BO_ 1590 1591;
BA_ "VFrameFormat" BO_ 1590 0;
BA_ "GenMsgCycleTime" BO_ 1590 10000;
BA_ "GenMsgStartDelayTime" BO_ 1590 1955;
BA_ "GenMsgILSupport" BO_ 1589 0;
BA_ "VFrameFormat" BO_ 1589 0;
BA_ "GenMsgSendType" BO_ 1589 8;
BA_ "CanTpFcFrameId" BO_ 1588 1589;
BA_ "VFrameFormat" BO_ 1588 0;
BA_ "GenMsgCycleTime" BO_ 1588 10000;
BA_ "GenMsgStartDelayTime" BO_ 1588 1850;
BA_ "GenMsgILSupport" BO_ 1587 0;
BA_ "VFrameFormat" BO_ 1587 0;
BA_ "GenMsgSendType" BO_ 1587 8;
BA_ "CanTpFcFrameId" BO_ 1586 1587;
BA_ "VFrameFormat" BO_ 1586 0;
BA_ "GenMsgCycleTime" BO_ 1586 10000;
BA_ "GenMsgStartDelayTime" BO_ 1586 1700;
BA_ "GenMsgILSupport" BO_ 1585 0;
BA_ "VFrameFormat" BO_ 1585 0;
BA_ "GenMsgSendType" BO_ 1585 8;
BA_ "CanTpFcFrameId" BO_ 1584 1585;
BA_ "VFrameFormat" BO_ 1584 0;
BA_ "GenMsgCycleTime" BO_ 1584 10000;
BA_ "GenMsgStartDelayTime" BO_ 1584 1605;
BA_ "GenMsgILSupport" BO_ 1577 0;
BA_ "VFrameFormat" BO_ 1577 0;
BA_ "GenMsgSendType" BO_ 1577 8;
BA_ "CanTpFcFrameId" BO_ 1576 1577;
BA_ "VFrameFormat" BO_ 1576 0;
BA_ "GenMsgCycleTime" BO_ 1576 10000;
BA_ "GenMsgStartDelayTime" BO_ 1576 1500;
BA_ "GenMsgILSupport" BO_ 1575 0;
BA_ "VFrameFormat" BO_ 1575 0;
BA_ "GenMsgSendType" BO_ 1575 8;
BA_ "CanTpFcFrameId" BO_ 1574 1575;
BA_ "VFrameFormat" BO_ 1574 0;
BA_ "GenMsgCycleTime" BO_ 1574 10000;
BA_ "GenMsgStartDelayTime" BO_ 1574 1350;
BA_ "GenMsgILSupport" BO_ 1573 0;
BA_ "VFrameFormat" BO_ 1573 0;
BA_ "GenMsgSendType" BO_ 1573 8;
BA_ "CanTpFcFrameId" BO_ 1572 1573;
BA_ "VFrameFormat" BO_ 1572 0;
BA_ "GenMsgCycleTime" BO_ 1572 10000;
BA_ "GenMsgStartDelayTime" BO_ 1572 1255;
BA_ "GenMsgILSupport" BO_ 1571 0;
BA_ "VFrameFormat" BO_ 1571 0;
BA_ "GenMsgSendType" BO_ 1571 8;
BA_ "CanTpFcFrameId" BO_ 1570 1571;
BA_ "VFrameFormat" BO_ 1570 0;
BA_ "GenMsgCycleTime" BO_ 1570 10000;
BA_ "GenMsgStartDelayTime" BO_ 1570 1150;
BA_ "GenMsgILSupport" BO_ 1569 0;
BA_ "VFrameFormat" BO_ 1569 0;
BA_ "GenMsgSendType" BO_ 1569 8;
BA_ "CanTpFcFrameId" BO_ 1568 1569;
BA_ "VFrameFormat" BO_ 1568 0;
BA_ "GenMsgCycleTime" BO_ 1568 10000;
BA_ "GenMsgStartDelayTime" BO_ 1568 1000;
BA_ "GenMsgILSupport" BO_ 1567 0;
BA_ "VFrameFormat" BO_ 1567 0;
BA_ "GenMsgSendType" BO_ 1567 8;
BA_ "CanTpFcFrameId" BO_ 1566 1567;
BA_ "VFrameFormat" BO_ 1566 0;
BA_ "GenMsgCycleTime" BO_ 1566 10000;
BA_ "GenMsgStartDelayTime" BO_ 1566 905;
BA_ "GenMsgILSupport" BO_ 1565 0;
BA_ "VFrameFormat" BO_ 1565 0;
BA_ "GenMsgSendType" BO_ 1565 8;
BA_ "CanTpFcFrameId" BO_ 1564 1565;
BA_ "VFrameFormat" BO_ 1564 0;
BA_ "GenMsgCycleTime" BO_ 1564 10000;
BA_ "GenMsgStartDelayTime" BO_ 1564 800;
BA_ "GenMsgILSupport" BO_ 1563 0;
BA_ "VFrameFormat" BO_ 1563 0;
BA_ "GenMsgSendType" BO_ 1563 8;
BA_ "CanTpFcFrameId" BO_ 1562 1563;
BA_ "VFrameFormat" BO_ 1562 0;
BA_ "GenMsgCycleTime" BO_ 1562 10000;
BA_ "GenMsgStartDelayTime" BO_ 1562 650;
BA_ "GenMsgILSupport" BO_ 1561 0;
BA_ "VFrameFormat" BO_ 1561 0;
BA_ "GenMsgSendType" BO_ 1561 8;
BA_ "CanTpFcFrameId" BO_ 1560 1561;
BA_ "VFrameFormat" BO_ 1560 0;
BA_ "GenMsgCycleTime" BO_ 1560 10000;
BA_ "GenMsgStartDelayTime" BO_ 1560 555;
BA_ "GenMsgILSupport" BO_ 1559 0;
BA_ "VFrameFormat" BO_ 1559 0;
BA_ "GenMsgSendType" BO_ 1559 8;
BA_ "CanTpFcFrameId" BO_ 1558 1559;
BA_ "VFrameFormat" BO_ 1558 0;
BA_ "GenMsgCycleTime" BO_ 1558 10000;
BA_ "GenMsgStartDelayTime" BO_ 1558 400;
BA_ "GenMsgILSupport" BO_ 1557 0;
BA_ "VFrameFormat" BO_ 1557 0;
BA_ "GenMsgSendType" BO_ 1557 8;
BA_ "CanTpFcFrameId" BO_ 1556 1557;
BA_ "VFrameFormat" BO_ 1556 0;
BA_ "GenMsgCycleTime" BO_ 1556 10000;
BA_ "GenMsgStartDelayTime" BO_ 1556 305;
BA_ "GenMsgILSupport" BO_ 1555 0;
BA_ "VFrameFormat" BO_ 1555 0;
BA_ "GenMsgSendType" BO_ 1555 8;
BA_ "CanTpFcFrameId" BO_ 1554 1555;
BA_ "VFrameFormat" BO_ 1554 0;
BA_ "GenMsgCycleTime" BO_ 1554 10000;
BA_ "GenMsgStartDelayTime" BO_ 1554 200;
BA_ "GenMsgILSupport" BO_ 1553 0;
BA_ "VFrameFormat" BO_ 1553 0;
BA_ "GenMsgSendType" BO_ 1553 8;
BA_ "CanTpFcFrameId" BO_ 1552 1553;
BA_ "VFrameFormat" BO_ 1552 0;
BA_ "GenMsgCycleTime" BO_ 1552 10000;
BA_ "GenMsgStartDelayTime" BO_ 1552 100;
BA_ "VFrameFormat" BO_ 1293 0;
BA_ "GenMsgCycleTime" BO_ 1293 250;
BA_ "GenMsgStartDelayTime" BO_ 1293 50;
BA_ "VFrameFormat" BO_ 1271 0;
BA_ "GenMsgCycleTime" BO_ 1271 200;
BA_ "GenMsgStartDelayTime" BO_ 1271 5;
BA_ "VFrameFormat" BO_ 391 0;
BA_ "GenMsgCycleTime" BO_ 391 20;
BA_ "GenMsgStartDelayTime" BO_ 391 5;
BA_ "GenMsgILSupport" BO_ 1326 0;
BA_ "VFrameFormat" BO_ 1326 0;
BA_ "GenMsgSendType" BO_ 1326 8;
BA_ "CanTpFcFrameId" BO_ 1321 1326;
BA_ "VFrameFormat" BO_ 1321 0;
BA_ "GenMsgSendType" BO_ 1321 8;
BA_ "GenMsgDelayTime" BO_ 1321 100;
BA_ "GenMsgILSupport" BO_ 1325 0;
BA_ "VFrameFormat" BO_ 1325 0;
BA_ "GenMsgSendType" BO_ 1325 8;
BA_ "CanTpFcFrameId" BO_ 1320 1325;
BA_ "VFrameFormat" BO_ 1320 0;
BA_ "GenMsgSendType" BO_ 1320 8;
BA_ "GenMsgDelayTime" BO_ 1320 100;
BA_ "GenMsgILSupport" BO_ 1324 0;
BA_ "VFrameFormat" BO_ 1324 0;
BA_ "GenMsgSendType" BO_ 1324 8;
BA_ "CanTpFcFrameId" BO_ 1319 1324;
BA_ "VFrameFormat" BO_ 1319 0;
BA_ "GenMsgSendType" BO_ 1319 8;
BA_ "GenMsgDelayTime" BO_ 1319 100;
BA_ "GenMsgILSupport" BO_ 1323 0;
BA_ "VFrameFormat" BO_ 1323 0;
BA_ "GenMsgSendType" BO_ 1323 8;
BA_ "CanTpFcFrameId" BO_ 1318 1323;
BA_ "VFrameFormat" BO_ 1318 0;
BA_ "GenMsgSendType" BO_ 1318 8;
BA_ "GenMsgDelayTime" BO_ 1318 100;
BA_ "GenMsgILSupport" BO_ 1322 0;
BA_ "VFrameFormat" BO_ 1322 0;
BA_ "GenMsgSendType" BO_ 1322 8;
BA_ "CanTpFcFrameId" BO_ 1317 1322;
BA_ "VFrameFormat" BO_ 1317 0;
BA_ "GenMsgSendType" BO_ 1317 8;
BA_ "GenMsgDelayTime" BO_ 1317 100;
BA_ "VFrameFormat" BO_ 1053 0;
BA_ "GenMsgCycleTime" BO_ 1053 150;
BA_ "GenMsgStartDelayTime" BO_ 1053 45;
BA_ "VFrameFormat" BO_ 1095 0;
BA_ "GenMsgCycleTime" BO_ 1095 100;
BA_ "GenMsgStartDelayTime" BO_ 1095 35;
BA_ "VFrameFormat" BO_ 1316 0;
BA_ "GenMsgCycleTime" BO_ 1316 1000;
BA_ "GenMsgStartDelayTime" BO_ 1316 210;
BA_ "VFrameFormat" BO_ 1315 0;
BA_ "GenMsgCycleTime" BO_ 1315 1000;
BA_ "GenMsgStartDelayTime" BO_ 1315 205;
BA_ "VFrameFormat" BO_ 1314 0;
BA_ "GenMsgCycleTime" BO_ 1314 1000;
BA_ "GenMsgStartDelayTime" BO_ 1314 190;
BA_ "VFrameFormat" BO_ 1313 0;
BA_ "GenMsgCycleTime" BO_ 1313 1000;
BA_ "GenMsgStartDelayTime" BO_ 1313 180;
BA_ "VFrameFormat" BO_ 1312 0;
BA_ "GenMsgCycleTime" BO_ 1312 1000;
BA_ "GenMsgStartDelayTime" BO_ 1312 165;
BA_ "VFrameFormat" BO_ 1305 0;
BA_ "GenMsgCycleTime" BO_ 1305 1000;
BA_ "GenMsgStartDelayTime" BO_ 1305 145;
BA_ "VFrameFormat" BO_ 1304 0;
BA_ "GenMsgCycleTime" BO_ 1304 1000;
BA_ "GenMsgStartDelayTime" BO_ 1304 130;
BA_ "GenSigCycleTime" SG_ 826 StartupProhibitStatus_ISig_4 100;
BA_ "GenSigCycleTimeActive" SG_ 826 StartupProhibitStatus_ISig_4 100;
BA_ "GenSigStartValue" SG_ 826 StartupProhibitStatus_ISig_4 3;
BA_ "GenSigMaxLatency" SG_ 826 StartupProhibitStatus_ISig_4 117;
BA_ "Platform_VMCU1_Sig" SG_ 826 StartupProhibitStatus_ISig_4 1;
BA_ "GenSigCycleTime" SG_ 826 RampLevelStatus_ISig_4 100;
BA_ "GenSigCycleTimeActive" SG_ 826 RampLevelStatus_ISig_4 100;
BA_ "GenSigStartValue" SG_ 826 RampLevelStatus_ISig_4 15;
BA_ "GenSigMaxLatency" SG_ 826 RampLevelStatus_ISig_4 117;
BA_ "Platform_VMCU1_Sig" SG_ 826 RampLevelStatus_ISig_4 1;
BA_ "GenSigCycleTime" SG_ 826 KneelingInformation_ISig_4 100;
BA_ "GenSigCycleTimeActive" SG_ 826 KneelingInformation_ISig_4 100;
BA_ "GenSigStartValue" SG_ 826 KneelingInformation_ISig_4 15;
BA_ "Platform_VMCU1_Sig" SG_ 826 KneelingInformation_ISig_4 1;
BA_ "GenSigCycleTime" SG_ 826 FrontAxleInBumperRange_ISig_4 100;
BA_ "GenSigCycleTimeActive" SG_ 826 FrontAxleInBumperRange_ISig_4 100;
BA_ "GenSigStartValue" SG_ 826 FrontAxleInBumperRange_ISig_4 3;
BA_ "NeedsUpdateBit" SG_ 826 FrontAxleInBumperRange_ISig_4 1;
BA_ "Platform_VMCU1_Sig" SG_ 826 FrontAxleInBumperRange_ISig_4 1;
BA_ "SeToolAncestorID_SIGNAL" SG_ 826 FrontAxleInBumperRange_ISig_4 "x0000001D04149915";
BA_ "SeToolItemID_SIGNAL" SG_ 826 FrontAxleInBumperRange_ISig_4 "x0000001D04149915";
BA_ "SeToolName_SIGNAL" SG_ 826 FrontAxleInBumperRange_ISig_4 "FrontAxleInBumperRange";
BA_ "SeToolVersion_SIGNAL" SG_ 826 FrontAxleInBumperRange_ISig_4 "1";
BA_ "GenSigCycleTime" SG_ 826 FerryFunctionStatus_ISig_4 100;
BA_ "GenSigCycleTimeActive" SG_ 826 FerryFunctionStatus_ISig_4 100;
BA_ "GenSigStartValue" SG_ 826 FerryFunctionStatus_ISig_4 7;
BA_ "GenSigMaxLatency" SG_ 826 FerryFunctionStatus_ISig_4 117;
BA_ "Platform_VMCU1_Sig" SG_ 826 FerryFunctionStatus_ISig_4 1;
BA_ "GenSigCycleTime" SG_ 826 EngPtoConsumesTorque 100;
BA_ "GenSigCycleTimeActive" SG_ 826 EngPtoConsumesTorque 100;
BA_ "GenSigStartValue" SG_ 826 EngPtoConsumesTorque 3;
BA_ "Platform_VMCU1_Sig" SG_ 826 EngPtoConsumesTorque 1;
BA_ "GenSigCycleTime" SG_ 826 LiftingControlModeRearAxle_ISig_ 100;
BA_ "GenSigCycleTimeActive" SG_ 826 LiftingControlModeRearAxle_ISig_ 100;
BA_ "GenSigStartValue" SG_ 826 LiftingControlModeRearAxle_ISig_ 3;
BA_ "Platform_VMCU1_Sig" SG_ 826 LiftingControlModeRearAxle_ISig_ 1;
BA_ "SeToolAncestorID_SIGNAL" SG_ 826 LiftingControlModeRearAxle_ISig_ "x0000001D04149A4E";
BA_ "SeToolItemID_SIGNAL" SG_ 826 LiftingControlModeRearAxle_ISig_ "x0000001D04149A4E";
BA_ "SeToolName_SIGNAL" SG_ 826 LiftingControlModeRearAxle_ISig_ "LiftingControlModeRearAxle";
BA_ "SeToolVersion_SIGNAL" SG_ 826 LiftingControlModeRearAxle_ISig_ "1";
BA_ "SystemSignalLongSymbol" SG_ 826 LiftingControlModeRearAxle_ISig_ "LiftingControlModeRearAxle_ISig_4";
BA_ "GenSigCycleTime" SG_ 826 KneelingStatusHMI_ISig_4 100;
BA_ "GenSigCycleTimeActive" SG_ 826 KneelingStatusHMI_ISig_4 100;
BA_ "GenSigStartValue" SG_ 826 KneelingStatusHMI_ISig_4 3;
BA_ "Platform_VMCU1_Sig" SG_ 826 KneelingStatusHMI_ISig_4 1;
BA_ "GenSigCycleTime" SG_ 826 SWEngineStop_rqst_ISig_4 100;
BA_ "GenSigCycleTimeActive" SG_ 826 SWEngineStop_rqst_ISig_4 100;
BA_ "GenSigStartValue" SG_ 826 SWEngineStop_rqst_ISig_4 7;
BA_ "Platform_VMCU1_Sig" SG_ 826 SWEngineStop_rqst_ISig_4 1;
BA_ "GenSigCycleTime" SG_ 826 FrontEndPositionStatus_ISig_4 100;
BA_ "GenSigCycleTimeActive" SG_ 826 FrontEndPositionStatus_ISig_4 100;
BA_ "GenSigStartValue" SG_ 826 FrontEndPositionStatus_ISig_4 7;
BA_ "GenSigMaxLatency" SG_ 826 FrontEndPositionStatus_ISig_4 117;
BA_ "Platform_VMCU1_Sig" SG_ 826 FrontEndPositionStatus_ISig_4 1;
BA_ "GenSigCycleTime" SG_ 826 LiftingControlModeFrontAxle_ISig 100;
BA_ "GenSigCycleTimeActive" SG_ 826 LiftingControlModeFrontAxle_ISig 100;
BA_ "GenSigStartValue" SG_ 826 LiftingControlModeFrontAxle_ISig 3;
BA_ "Platform_VMCU1_Sig" SG_ 826 LiftingControlModeFrontAxle_ISig 1;
BA_ "SeToolAncestorID_SIGNAL" SG_ 826 LiftingControlModeFrontAxle_ISig "x0000001D04149903";
BA_ "SeToolItemID_SIGNAL" SG_ 826 LiftingControlModeFrontAxle_ISig "x0000001D04149903";
BA_ "SeToolName_SIGNAL" SG_ 826 LiftingControlModeFrontAxle_ISig "LiftingControlModeFrontAxle";
BA_ "SeToolVersion_SIGNAL" SG_ 826 LiftingControlModeFrontAxle_ISig "1";
BA_ "SystemSignalLongSymbol" SG_ 826 LiftingControlModeFrontAxle_ISig "LiftingControlModeFrontAxle_ISig_4";
BA_ "GenSigSendType" SG_ 826 FrontAxleInBumperRange_UB_ISig_4 7;
BA_ "Platform_VMCU1_Sig" SG_ 826 FrontAxleInBumperRange_UB_ISig_4 1;
BA_ "GenSigCycleTime" SG_ 826 UnevenLoadWarning_ISig_4 100;
BA_ "GenSigCycleTimeActive" SG_ 826 UnevenLoadWarning_ISig_4 100;
BA_ "GenSigStartValue" SG_ 826 UnevenLoadWarning_ISig_4 3;
BA_ "GenSigMaxLatency" SG_ 826 UnevenLoadWarning_ISig_4 117;
BA_ "Platform_VMCU1_Sig" SG_ 826 UnevenLoadWarning_ISig_4 1;
BA_ "GenSigCycleTime" SG_ 826 RampHeightOutsideTargetRange_ISi 100;
BA_ "GenSigCycleTimeActive" SG_ 826 RampHeightOutsideTargetRange_ISi 100;
BA_ "GenSigStartValue" SG_ 826 RampHeightOutsideTargetRange_ISi 7;
BA_ "GenSigMaxLatency" SG_ 826 RampHeightOutsideTargetRange_ISi 117;
BA_ "Platform_VMCU1_Sig" SG_ 826 RampHeightOutsideTargetRange_ISi 1;
BA_ "SystemSignalLongSymbol" SG_ 826 RampHeightOutsideTargetRange_ISi "RampHeightOutsideTargetRange_ISig_4";
BA_ "GenSigCycleTime" SG_ 826 DriveLevelPosUserInteraction_ISi 100;
BA_ "GenSigCycleTimeActive" SG_ 826 DriveLevelPosUserInteraction_ISi 100;
BA_ "GenSigStartValue" SG_ 826 DriveLevelPosUserInteraction_ISi 7;
BA_ "Platform_VMCU1_Sig" SG_ 826 DriveLevelPosUserInteraction_ISi 1;
BA_ "SystemSignalLongSymbol" SG_ 826 DriveLevelPosUserInteraction_ISi "DriveLevelPosUserInteraction_ISig_4";
BA_ "GenSigCycleTime" SG_ 826 RearEndPositionStatus_ISig_4 100;
BA_ "GenSigCycleTimeActive" SG_ 826 RearEndPositionStatus_ISig_4 100;
BA_ "GenSigStartValue" SG_ 826 RearEndPositionStatus_ISig_4 7;
BA_ "GenSigMaxLatency" SG_ 826 RearEndPositionStatus_ISig_4 117;
BA_ "Platform_VMCU1_Sig" SG_ 826 RearEndPositionStatus_ISig_4 1;
BA_ "GenSigCycleTime" SG_ 826 ProhibitControlStatus_ISig_4 100;
BA_ "GenSigCycleTimeActive" SG_ 826 ProhibitControlStatus_ISig_4 100;
BA_ "GenSigStartValue" SG_ 826 ProhibitControlStatus_ISig_4 3;
BA_ "GenSigMaxLatency" SG_ 826 ProhibitControlStatus_ISig_4 117;
BA_ "Platform_VMCU1_Sig" SG_ 826 ProhibitControlStatus_ISig_4 1;
BA_ "GenSigCycleTime" SG_ 826 ChangeKneelACK_ISig_4 100;
BA_ "GenSigCycleTimeActive" SG_ 826 ChangeKneelACK_ISig_4 100;
BA_ "GenSigStartValue" SG_ 826 ChangeKneelACK_ISig_4 3;
BA_ "Platform_VMCU1_Sig" SG_ 826 ChangeKneelACK_ISig_4 1;
BA_ "GenSigCycleTime" SG_ 826 ParkBrakeApplicationMode2 100;
BA_ "GenSigCycleTimeActive" SG_ 826 ParkBrakeApplicationMode2 100;
BA_ "GenSigStartValue" SG_ 826 ParkBrakeApplicationMode2 15;
BA_ "GenSigCycleTime" SG_ 826 RollEndPositionStatus_ISig_4 100;
BA_ "GenSigCycleTimeActive" SG_ 826 RollEndPositionStatus_ISig_4 100;
BA_ "GenSigStartValue" SG_ 826 RollEndPositionStatus_ISig_4 7;
BA_ "GenSigMaxLatency" SG_ 826 RollEndPositionStatus_ISig_4 117;
BA_ "Platform_VMCU1_Sig" SG_ 826 RollEndPositionStatus_ISig_4 1;
BA_ "GenSigSendType" SG_ 826 RearAxleInBumperRange_UB_ISig_4 7;
BA_ "Platform_VMCU1_Sig" SG_ 826 RearAxleInBumperRange_UB_ISig_4 1;
BA_ "GenSigCycleTime" SG_ 826 ParkBrakeReleaseMode2_ISig_4 100;
BA_ "GenSigCycleTimeActive" SG_ 826 ParkBrakeReleaseMode2_ISig_4 100;
BA_ "GenSigStartValue" SG_ 826 ParkBrakeReleaseMode2_ISig_4 15;
BA_ "GenSigCycleTime" SG_ 826 ECSStandbyAllowed_ISig_4 100;
BA_ "GenSigCycleTimeActive" SG_ 826 ECSStandbyAllowed_ISig_4 100;
BA_ "GenSigStartValue" SG_ 826 ECSStandbyAllowed_ISig_4 3;
BA_ "Platform_VMCU1_Sig" SG_ 826 ECSStandbyAllowed_ISig_4 1;
BA_ "GenSigCycleTime" SG_ 826 RearAxleInBumperRange_ISig_4 100;
BA_ "GenSigCycleTimeActive" SG_ 826 RearAxleInBumperRange_ISig_4 100;
BA_ "GenSigStartValue" SG_ 826 RearAxleInBumperRange_ISig_4 3;
BA_ "NeedsUpdateBit" SG_ 826 RearAxleInBumperRange_ISig_4 1;
BA_ "Platform_VMCU1_Sig" SG_ 826 RearAxleInBumperRange_ISig_4 1;
BA_ "SeToolAncestorID_SIGNAL" SG_ 826 RearAxleInBumperRange_ISig_4 "x0000001D04149986";
BA_ "SeToolItemID_SIGNAL" SG_ 826 RearAxleInBumperRange_ISig_4 "x0000001D04149986";
BA_ "SeToolName_SIGNAL" SG_ 826 RearAxleInBumperRange_ISig_4 "RearAxleInBumperRange";
BA_ "SeToolVersion_SIGNAL" SG_ 826 RearAxleInBumperRange_ISig_4 "1";
BA_ "GenSigCycleTime" SG_ 1029 RelativeLevelRearAxleRight_ISig_ 100;
BA_ "GenSigCycleTimeActive" SG_ 1029 RelativeLevelRearAxleRight_ISig_ 100;
BA_ "GenSigStartValue" SG_ 1029 RelativeLevelRearAxleRight_ISig_ 65535;
BA_ "Platform_VMCU1_Sig" SG_ 1029 RelativeLevelRearAxleRight_ISig_ 1;
BA_ "SeToolAncestorID_SIGNAL" SG_ 1029 RelativeLevelRearAxleRight_ISig_ "x0000001D0412EE40";
BA_ "SeToolItemID_SIGNAL" SG_ 1029 RelativeLevelRearAxleRight_ISig_ "x0000001D04384E50";
BA_ "SeToolName_SIGNAL" SG_ 1029 RelativeLevelRearAxleRight_ISig_ "RelativeLevelRearAxleRight";
BA_ "SeToolVersion_SIGNAL" SG_ 1029 RelativeLevelRearAxleRight_ISig_ "2";
BA_ "SystemSignalLongSymbol" SG_ 1029 RelativeLevelRearAxleRight_ISig_ "RelativeLevelRearAxleRight_ISig_4";
BA_ "GenSigCycleTime" SG_ 1029 RelativeLevelFrontAxleRight_ISig 100;
BA_ "GenSigCycleTimeActive" SG_ 1029 RelativeLevelFrontAxleRight_ISig 100;
BA_ "GenSigStartValue" SG_ 1029 RelativeLevelFrontAxleRight_ISig 65535;
BA_ "Platform_VMCU1_Sig" SG_ 1029 RelativeLevelFrontAxleRight_ISig 1;
BA_ "SeToolAncestorID_SIGNAL" SG_ 1029 RelativeLevelFrontAxleRight_ISig "x0000001D0412EE3C";
BA_ "SeToolItemID_SIGNAL" SG_ 1029 RelativeLevelFrontAxleRight_ISig "x0000001D04384E33";
BA_ "SeToolName_SIGNAL" SG_ 1029 RelativeLevelFrontAxleRight_ISig "RelativeLevelFrontAxleRight";
BA_ "SeToolVersion_SIGNAL" SG_ 1029 RelativeLevelFrontAxleRight_ISig "2";
BA_ "SystemSignalLongSymbol" SG_ 1029 RelativeLevelFrontAxleRight_ISig "RelativeLevelFrontAxleRight_ISig_4";
BA_ "GenSigCycleTime" SG_ 1029 RelativeLevelFrontAxleLeft_ISig_ 100;
BA_ "GenSigCycleTimeActive" SG_ 1029 RelativeLevelFrontAxleLeft_ISig_ 100;
BA_ "GenSigStartValue" SG_ 1029 RelativeLevelFrontAxleLeft_ISig_ 65535;
BA_ "Platform_VMCU1_Sig" SG_ 1029 RelativeLevelFrontAxleLeft_ISig_ 1;
BA_ "SeToolAncestorID_SIGNAL" SG_ 1029 RelativeLevelFrontAxleLeft_ISig_ "x0000001D0412EE39";
BA_ "SeToolItemID_SIGNAL" SG_ 1029 RelativeLevelFrontAxleLeft_ISig_ "x0000001D04384DFD";
BA_ "SeToolName_SIGNAL" SG_ 1029 RelativeLevelFrontAxleLeft_ISig_ "RelativeLevelFrontAxleLeft";
BA_ "SeToolVersion_SIGNAL" SG_ 1029 RelativeLevelFrontAxleLeft_ISig_ "2";
BA_ "SystemSignalLongSymbol" SG_ 1029 RelativeLevelFrontAxleLeft_ISig_ "RelativeLevelFrontAxleLeft_ISig_4";
BA_ "GenSigCycleTime" SG_ 1029 RelativeLevelRearAxleLeft_ISig_4 100;
BA_ "GenSigCycleTimeActive" SG_ 1029 RelativeLevelRearAxleLeft_ISig_4 100;
BA_ "GenSigStartValue" SG_ 1029 RelativeLevelRearAxleLeft_ISig_4 65535;
BA_ "Platform_VMCU1_Sig" SG_ 1029 RelativeLevelRearAxleLeft_ISig_4 1;
BA_ "SeToolAncestorID_SIGNAL" SG_ 1029 RelativeLevelRearAxleLeft_ISig_4 "x0000001D0412EE3E";
BA_ "SeToolItemID_SIGNAL" SG_ 1029 RelativeLevelRearAxleLeft_ISig_4 "x0000001D04384E3D";
BA_ "SeToolName_SIGNAL" SG_ 1029 RelativeLevelRearAxleLeft_ISig_4 "RelativeLevelRearAxleLeft";
BA_ "SeToolVersion_SIGNAL" SG_ 1029 RelativeLevelRearAxleLeft_ISig_4 "2";
BA_ "GenSigCycleTime" SG_ 1207 RelativeLevelFrontAxleLeftRaw_IS 100;
BA_ "GenSigCycleTimeActive" SG_ 1207 RelativeLevelFrontAxleLeftRaw_IS 100;
BA_ "GenSigStartValue" SG_ 1207 RelativeLevelFrontAxleLeftRaw_IS 65535;
BA_ "SystemSignalLongSymbol" SG_ 1207 RelativeLevelFrontAxleLeftRaw_IS "RelativeLevelFrontAxleLeftRaw_ISig_4";
BA_ "GenSigCycleTime" SG_ 1207 RelativeLevelFrontAxleRightRaw_I 100;
BA_ "GenSigCycleTimeActive" SG_ 1207 RelativeLevelFrontAxleRightRaw_I 100;
BA_ "GenSigStartValue" SG_ 1207 RelativeLevelFrontAxleRightRaw_I 65535;
BA_ "SystemSignalLongSymbol" SG_ 1207 RelativeLevelFrontAxleRightRaw_I "RelativeLevelFrontAxleRightRaw_ISig_4";
BA_ "GenSigCycleTime" SG_ 1273 OBDDtcVMCU_SPN2_B2 100;
BA_ "GenSigCycleTimeActive" SG_ 1273 OBDDtcVMCU_SPN2_B2 100;
BA_ "GenSigStartValue" SG_ 1273 OBDDtcVMCU_SPN2_B2 255;
BA_ "GenSigCycleTime" SG_ 1273 OBDDtcVMCU_SPN1_3msb 100;
BA_ "GenSigCycleTimeActive" SG_ 1273 OBDDtcVMCU_SPN1_3msb 100;
BA_ "GenSigStartValue" SG_ 1273 OBDDtcVMCU_SPN1_3msb 7;
BA_ "GenSigCycleTime" SG_ 1273 OBDDtcVMCU_SPN2_3msb 100;
BA_ "GenSigCycleTimeActive" SG_ 1273 OBDDtcVMCU_SPN2_3msb 100;
BA_ "GenSigStartValue" SG_ 1273 OBDDtcVMCU_SPN2_3msb 7;
BA_ "GenSigCycleTime" SG_ 1273 OBDDtcVMCU_EvalResult2 100;
BA_ "GenSigCycleTimeActive" SG_ 1273 OBDDtcVMCU_EvalResult2 100;
BA_ "GenSigStartValue" SG_ 1273 OBDDtcVMCU_EvalResult2 3;
BA_ "GenSigCycleTime" SG_ 1273 OBDDtcVMCU_SPN1_B1 100;
BA_ "GenSigCycleTimeActive" SG_ 1273 OBDDtcVMCU_SPN1_B1 100;
BA_ "GenSigStartValue" SG_ 1273 OBDDtcVMCU_SPN1_B1 255;
BA_ "GenSigCycleTime" SG_ 1273 OBDDtcVMCU_EvalStatus1 100;
BA_ "GenSigCycleTimeActive" SG_ 1273 OBDDtcVMCU_EvalStatus1 100;
BA_ "GenSigStartValue" SG_ 1273 OBDDtcVMCU_EvalStatus1 3;
BA_ "GenSigCycleTime" SG_ 1273 OBDDtcVMCU_DrivingCycle2 100;
BA_ "GenSigCycleTimeActive" SG_ 1273 OBDDtcVMCU_DrivingCycle2 100;
BA_ "GenSigStartValue" SG_ 1273 OBDDtcVMCU_DrivingCycle2 3;
BA_ "GenSigCycleTime" SG_ 1273 OBDDtcVMCU_SPN2_B1 100;
BA_ "GenSigCycleTimeActive" SG_ 1273 OBDDtcVMCU_SPN2_B1 100;
BA_ "GenSigStartValue" SG_ 1273 OBDDtcVMCU_SPN2_B1 255;
BA_ "GenSigCycleTime" SG_ 1273 OBDDtcVMCU_DrivingCycle1 100;
BA_ "GenSigCycleTimeActive" SG_ 1273 OBDDtcVMCU_DrivingCycle1 100;
BA_ "GenSigStartValue" SG_ 1273 OBDDtcVMCU_DrivingCycle1 3;
BA_ "GenSigCycleTime" SG_ 1273 OBDDtcVMCU_SPN1_B2 100;
BA_ "GenSigCycleTimeActive" SG_ 1273 OBDDtcVMCU_SPN1_B2 100;
BA_ "GenSigStartValue" SG_ 1273 OBDDtcVMCU_SPN1_B2 255;
BA_ "GenSigCycleTime" SG_ 1273 OBDDtcVMCU_FMI1 100;
BA_ "GenSigCycleTimeActive" SG_ 1273 OBDDtcVMCU_FMI1 100;
BA_ "GenSigStartValue" SG_ 1273 OBDDtcVMCU_FMI1 31;
BA_ "GenSigCycleTime" SG_ 1273 OBDDtcVMCU_EvalStatus2 100;
BA_ "GenSigCycleTimeActive" SG_ 1273 OBDDtcVMCU_EvalStatus2 100;
BA_ "GenSigStartValue" SG_ 1273 OBDDtcVMCU_EvalStatus2 3;
BA_ "GenSigCycleTime" SG_ 1273 OBDDtcVMCU_FMI2 100;
BA_ "GenSigCycleTimeActive" SG_ 1273 OBDDtcVMCU_FMI2 100;
BA_ "GenSigStartValue" SG_ 1273 OBDDtcVMCU_FMI2 31;
BA_ "GenSigCycleTime" SG_ 1273 OBDDtcVMCU_EvalResult1 100;
BA_ "GenSigCycleTimeActive" SG_ 1273 OBDDtcVMCU_EvalResult1 100;
BA_ "GenSigStartValue" SG_ 1273 OBDDtcVMCU_EvalResult1 3;
BA_ "GenSigCycleTime" SG_ 567 DriveModeSwitchStat_Rqst 100;
BA_ "GenSigCycleTimeActive" SG_ 567 DriveModeSwitchStat_Rqst 100;
BA_ "GenSigStartValue" SG_ 567 DriveModeSwitchStat_Rqst 3;
BA_ "GenSigCycleTime" SG_ 567 UpDownShiftRqst_CRC 100;
BA_ "GenSigCycleTimeActive" SG_ 567 UpDownShiftRqst_CRC 100;
BA_ "GenSigCycleTime" SG_ 567 GearLeverPosition2_SqC 100;
BA_ "GenSigCycleTimeActive" SG_ 567 GearLeverPosition2_SqC 100;
BA_ "GenSigCycleTime" SG_ 567 GearLeverPosition2_Rqst 100;
BA_ "GenSigCycleTimeActive" SG_ 567 GearLeverPosition2_Rqst 100;
BA_ "GenSigStartValue" SG_ 567 GearLeverPosition2_Rqst 15;
BA_ "GenSigCycleTime" SG_ 567 DriveModeSwitchStat_CRC 100;
BA_ "GenSigCycleTimeActive" SG_ 567 DriveModeSwitchStat_CRC 100;
BA_ "GenSigCycleTime" SG_ 567 DriveModeSwitchStat_SqC 100;
BA_ "GenSigCycleTimeActive" SG_ 567 DriveModeSwitchStat_SqC 100;
BA_ "GenSigCycleTime" SG_ 567 UpDownShiftRqst_SqC 100;
BA_ "GenSigCycleTimeActive" SG_ 567 UpDownShiftRqst_SqC 100;
BA_ "GenSigCycleTime" SG_ 567 UpDownShiftRqst_Rqst 100;
BA_ "GenSigCycleTimeActive" SG_ 567 UpDownShiftRqst_Rqst 100;
BA_ "GenSigStartValue" SG_ 567 UpDownShiftRqst_Rqst 15;
BA_ "GenSigCycleTime" SG_ 567 GearLeverPosition2_CRC 100;
BA_ "GenSigCycleTimeActive" SG_ 567 GearLeverPosition2_CRC 100;
BA_ "GenSigSendType" SG_ 1483 VMCU_BB2_145S_FCS 7;
BA_ "GenSigSendType" SG_ 1482 CalDataLoadTrlAxSumP2_YearUTC 1;
BA_ "GenSigCycleTime" SG_ 1482 CalDataLoadTrlAxSumP2_YearUTC 100;
BA_ "GenSigCycleTimeActive" SG_ 1482 CalDataLoadTrlAxSumP2_YearUTC 100;
BA_ "GenSigStartValue" SG_ 1482 CalDataLoadTrlAxSumP2_YearUTC 255;
BA_ "GenSigSendType" SG_ 1482 CalDataLoadTrlAxSumP2_ScaleLoad 1;
BA_ "GenSigCycleTime" SG_ 1482 CalDataLoadTrlAxSumP2_ScaleLoad 100;
BA_ "GenSigCycleTimeActive" SG_ 1482 CalDataLoadTrlAxSumP2_ScaleLoad 100;
BA_ "GenSigStartValue" SG_ 1482 CalDataLoadTrlAxSumP2_ScaleLoad 65535;
BA_ "GenSigSendType" SG_ 1482 CalDataLoadTrlAxSumP2_DayUTC 1;
BA_ "GenSigCycleTime" SG_ 1482 CalDataLoadTrlAxSumP2_DayUTC 100;
BA_ "GenSigCycleTimeActive" SG_ 1482 CalDataLoadTrlAxSumP2_DayUTC 100;
BA_ "GenSigStartValue" SG_ 1482 CalDataLoadTrlAxSumP2_DayUTC 255;
BA_ "GenSigSendType" SG_ 1482 CalDataLoadTrlAxSumP2_VehicleID 1;
BA_ "GenSigCycleTime" SG_ 1482 CalDataLoadTrlAxSumP2_VehicleID 100;
BA_ "GenSigCycleTimeActive" SG_ 1482 CalDataLoadTrlAxSumP2_VehicleID 100;
BA_ "GenSigStartValue" SG_ 1482 CalDataLoadTrlAxSumP2_VehicleID 7;
BA_ "GenSigSendType" SG_ 1482 CalDataLoadTrlAxSumP2_QF 1;
BA_ "GenSigCycleTime" SG_ 1482 CalDataLoadTrlAxSumP2_QF 100;
BA_ "GenSigCycleTimeActive" SG_ 1482 CalDataLoadTrlAxSumP2_QF 100;
BA_ "GenSigStartValue" SG_ 1482 CalDataLoadTrlAxSumP2_QF 65535;
BA_ "GenSigSendType" SG_ 1482 CalDataLoadTrlAxSumP2_MonthUTC 1;
BA_ "GenSigCycleTime" SG_ 1482 CalDataLoadTrlAxSumP2_MonthUTC 100;
BA_ "GenSigCycleTimeActive" SG_ 1482 CalDataLoadTrlAxSumP2_MonthUTC 100;
BA_ "GenSigStartValue" SG_ 1482 CalDataLoadTrlAxSumP2_MonthUTC 255;
BA_ "GenSigSendType" SG_ 1482 CalDataLoadTrlAxSumP2_UncalLoad 1;
BA_ "GenSigCycleTime" SG_ 1482 CalDataLoadTrlAxSumP2_UncalLoad 100;
BA_ "GenSigCycleTimeActive" SG_ 1482 CalDataLoadTrlAxSumP2_UncalLoad 100;
BA_ "GenSigStartValue" SG_ 1482 CalDataLoadTrlAxSumP2_UncalLoad 65535;
BA_ "GenSigSendType" SG_ 1407 VMCU_BB2_144S_FCS 7;
BA_ "GenSigSendType" SG_ 1406 CalDataLoadTrlAxSumP1_DayUTC 1;
BA_ "GenSigCycleTime" SG_ 1406 CalDataLoadTrlAxSumP1_DayUTC 100;
BA_ "GenSigCycleTimeActive" SG_ 1406 CalDataLoadTrlAxSumP1_DayUTC 100;
BA_ "GenSigStartValue" SG_ 1406 CalDataLoadTrlAxSumP1_DayUTC 255;
BA_ "GenSigSendType" SG_ 1406 CalDataLoadTrlAxSumP1_YearUTC 1;
BA_ "GenSigCycleTime" SG_ 1406 CalDataLoadTrlAxSumP1_YearUTC 100;
BA_ "GenSigCycleTimeActive" SG_ 1406 CalDataLoadTrlAxSumP1_YearUTC 100;
BA_ "GenSigStartValue" SG_ 1406 CalDataLoadTrlAxSumP1_YearUTC 255;
BA_ "GenSigSendType" SG_ 1406 CalDataLoadTrlAxSumP1_VehicleID 1;
BA_ "GenSigCycleTime" SG_ 1406 CalDataLoadTrlAxSumP1_VehicleID 100;
BA_ "GenSigCycleTimeActive" SG_ 1406 CalDataLoadTrlAxSumP1_VehicleID 100;
BA_ "GenSigStartValue" SG_ 1406 CalDataLoadTrlAxSumP1_VehicleID 7;
BA_ "GenSigSendType" SG_ 1406 CalDataLoadTrlAxSumP1_ScaleLoad 1;
BA_ "GenSigCycleTime" SG_ 1406 CalDataLoadTrlAxSumP1_ScaleLoad 100;
BA_ "GenSigCycleTimeActive" SG_ 1406 CalDataLoadTrlAxSumP1_ScaleLoad 100;
BA_ "GenSigStartValue" SG_ 1406 CalDataLoadTrlAxSumP1_ScaleLoad 65535;
BA_ "GenSigSendType" SG_ 1406 CalDataLoadTrlAxSumP1_MonthUTC 1;
BA_ "GenSigCycleTime" SG_ 1406 CalDataLoadTrlAxSumP1_MonthUTC 100;
BA_ "GenSigCycleTimeActive" SG_ 1406 CalDataLoadTrlAxSumP1_MonthUTC 100;
BA_ "GenSigStartValue" SG_ 1406 CalDataLoadTrlAxSumP1_MonthUTC 255;
BA_ "GenSigSendType" SG_ 1406 CalDataLoadTrlAxSumP1_UncalLoad 1;
BA_ "GenSigCycleTime" SG_ 1406 CalDataLoadTrlAxSumP1_UncalLoad 100;
BA_ "GenSigCycleTimeActive" SG_ 1406 CalDataLoadTrlAxSumP1_UncalLoad 100;
BA_ "GenSigStartValue" SG_ 1406 CalDataLoadTrlAxSumP1_UncalLoad 65535;
BA_ "GenSigSendType" SG_ 1406 CalDataLoadTrlAxSumP1_QF 1;
BA_ "GenSigCycleTime" SG_ 1406 CalDataLoadTrlAxSumP1_QF 100;
BA_ "GenSigCycleTimeActive" SG_ 1406 CalDataLoadTrlAxSumP1_QF 100;
BA_ "GenSigStartValue" SG_ 1406 CalDataLoadTrlAxSumP1_QF 65535;
BA_ "GenSigCycleTime" SG_ 1169 ConnectedTrailer1_Calibrated 100;
BA_ "GenSigCycleTimeActive" SG_ 1169 ConnectedTrailer1_Calibrated 100;
BA_ "GenSigStartValue" SG_ 1169 ConnectedTrailer1_Calibrated 7;
BA_ "GenSigCycleTime" SG_ 1169 ConnectedTrailer3_Calibrated 100;
BA_ "GenSigCycleTimeActive" SG_ 1169 ConnectedTrailer3_Calibrated 100;
BA_ "GenSigStartValue" SG_ 1169 ConnectedTrailer3_Calibrated 7;
BA_ "GenSigCycleTime" SG_ 1169 ConnectedTrailer4_Calibrated 100;
BA_ "GenSigCycleTimeActive" SG_ 1169 ConnectedTrailer4_Calibrated 100;
BA_ "GenSigStartValue" SG_ 1169 ConnectedTrailer4_Calibrated 7;
BA_ "GenSigCycleTime" SG_ 1169 ConnectedTrailer2_MemPosition 100;
BA_ "GenSigCycleTimeActive" SG_ 1169 ConnectedTrailer2_MemPosition 100;
BA_ "GenSigStartValue" SG_ 1169 ConnectedTrailer2_MemPosition 255;
BA_ "GenSigCycleTime" SG_ 1169 ConnectedTrailer1_MemPosition 100;
BA_ "GenSigCycleTimeActive" SG_ 1169 ConnectedTrailer1_MemPosition 100;
BA_ "GenSigStartValue" SG_ 1169 ConnectedTrailer1_MemPosition 255;
BA_ "GenSigCycleTime" SG_ 1169 ConnectedTrailer5_Calibrated 100;
BA_ "GenSigCycleTimeActive" SG_ 1169 ConnectedTrailer5_Calibrated 100;
BA_ "GenSigStartValue" SG_ 1169 ConnectedTrailer5_Calibrated 7;
BA_ "GenSigCycleTime" SG_ 1169 ConnectedTrailer5_MemPosition 100;
BA_ "GenSigCycleTimeActive" SG_ 1169 ConnectedTrailer5_MemPosition 100;
BA_ "GenSigStartValue" SG_ 1169 ConnectedTrailer5_MemPosition 255;
BA_ "GenSigCycleTime" SG_ 1169 ConnectedTrailer3_MemPosition 100;
BA_ "GenSigCycleTimeActive" SG_ 1169 ConnectedTrailer3_MemPosition 100;
BA_ "GenSigStartValue" SG_ 1169 ConnectedTrailer3_MemPosition 255;
BA_ "GenSigCycleTime" SG_ 1169 ConnectedTrailer2_Calibrated 100;
BA_ "GenSigCycleTimeActive" SG_ 1169 ConnectedTrailer2_Calibrated 100;
BA_ "GenSigStartValue" SG_ 1169 ConnectedTrailer2_Calibrated 7;
BA_ "GenSigCycleTime" SG_ 1169 ConnectedTrailer4_MemPosition 100;
BA_ "GenSigCycleTimeActive" SG_ 1169 ConnectedTrailer4_MemPosition 100;
BA_ "GenSigStartValue" SG_ 1169 ConnectedTrailer4_MemPosition 255;
BA_ "GenSigCycleTime" SG_ 1185 UncalLoadTrkFAxle1_ISig_4 100;
BA_ "GenSigCycleTimeActive" SG_ 1185 UncalLoadTrkFAxle1_ISig_4 100;
BA_ "GenSigStartValue" SG_ 1185 UncalLoadTrkFAxle1_ISig_4 65535;
BA_ "GenSigCycleTime" SG_ 1185 UncalLoadTrkRAxle2_ISig_4 100;
BA_ "GenSigCycleTimeActive" SG_ 1185 UncalLoadTrkRAxle2_ISig_4 100;
BA_ "GenSigStartValue" SG_ 1185 UncalLoadTrkRAxle2_ISig_4 65535;
BA_ "GenSigCycleTime" SG_ 1185 UncalLoadTrkFAxle2_ISig_4 100;
BA_ "GenSigCycleTimeActive" SG_ 1185 UncalLoadTrkFAxle2_ISig_4 100;
BA_ "GenSigStartValue" SG_ 1185 UncalLoadTrkFAxle2_ISig_4 65535;
BA_ "GenSigCycleTime" SG_ 1185 UncalLoadTrkRAxle1_ISig_4 100;
BA_ "GenSigCycleTimeActive" SG_ 1185 UncalLoadTrkRAxle1_ISig_4 100;
BA_ "GenSigStartValue" SG_ 1185 UncalLoadTrkRAxle1_ISig_4 65535;
BA_ "GenSigCycleTime" SG_ 1333 SuspensionGCVW_ISig_4 100;
BA_ "GenSigCycleTimeActive" SG_ 1333 SuspensionGCVW_ISig_4 100;
BA_ "GenSigStartValue" SG_ 1333 SuspensionGCVW_ISig_4 65535;
BA_ "GenSigCycleTime" SG_ 1333 SelectedLocalTimeOffset_stat_ISi 100;
BA_ "GenSigCycleTimeActive" SG_ 1333 SelectedLocalTimeOffset_stat_ISi 100;
BA_ "GenSigStartValue" SG_ 1333 SelectedLocalTimeOffset_stat_ISi 4294967295;
BA_ "SystemSignalLongSymbol" SG_ 1333 SelectedLocalTimeOffset_stat_ISi "SelectedLocalTimeOffset_stat_ISig_4";
BA_ "GenSigSendType" SG_ 1597 VMCU_BB2_140P_FCS 7;
BA_ "GenSigCycleTime" SG_ 1596 SavedUnit20_TrailerName 100;
BA_ "GenSigCycleTimeActive" SG_ 1596 SavedUnit20_TrailerName 100;
BA_ "GenSigMaxLatency" SG_ 1596 SavedUnit20_TrailerName 10000;
BA_ "GenSigCycleTime" SG_ 1596 SavedUnit20_TrailerPosition 100;
BA_ "GenSigCycleTimeActive" SG_ 1596 SavedUnit20_TrailerPosition 100;
BA_ "GenSigStartValue" SG_ 1596 SavedUnit20_TrailerPosition 7;
BA_ "GenSigMaxLatency" SG_ 1596 SavedUnit20_TrailerPosition 10000;
BA_ "GenSigSendType" SG_ 1595 VMCU_BB2_139P_FCS 7;
BA_ "GenSigCycleTime" SG_ 1594 SavedUnit19_TrailerName 100;
BA_ "GenSigCycleTimeActive" SG_ 1594 SavedUnit19_TrailerName 100;
BA_ "GenSigMaxLatency" SG_ 1594 SavedUnit19_TrailerName 10000;
BA_ "GenSigCycleTime" SG_ 1594 SavedUnit19_TrailerPosition 100;
BA_ "GenSigCycleTimeActive" SG_ 1594 SavedUnit19_TrailerPosition 100;
BA_ "GenSigStartValue" SG_ 1594 SavedUnit19_TrailerPosition 7;
BA_ "GenSigMaxLatency" SG_ 1594 SavedUnit19_TrailerPosition 10000;
BA_ "GenSigSendType" SG_ 1593 VMCU_BB2_138P_FCS 7;
BA_ "GenSigCycleTime" SG_ 1592 SavedUnit18_TrailerPosition 100;
BA_ "GenSigCycleTimeActive" SG_ 1592 SavedUnit18_TrailerPosition 100;
BA_ "GenSigStartValue" SG_ 1592 SavedUnit18_TrailerPosition 7;
BA_ "GenSigMaxLatency" SG_ 1592 SavedUnit18_TrailerPosition 10000;
BA_ "GenSigCycleTime" SG_ 1592 SavedUnit18_TrailerName 100;
BA_ "GenSigCycleTimeActive" SG_ 1592 SavedUnit18_TrailerName 100;
BA_ "GenSigMaxLatency" SG_ 1592 SavedUnit18_TrailerName 10000;
BA_ "GenSigSendType" SG_ 1591 VMCU_BB2_137P_FCS 7;
BA_ "GenSigCycleTime" SG_ 1590 SavedUnit17_TrailerPosition 100;
BA_ "GenSigCycleTimeActive" SG_ 1590 SavedUnit17_TrailerPosition 100;
BA_ "GenSigStartValue" SG_ 1590 SavedUnit17_TrailerPosition 7;
BA_ "GenSigMaxLatency" SG_ 1590 SavedUnit17_TrailerPosition 10000;
BA_ "GenSigCycleTime" SG_ 1590 SavedUnit17_TrailerName 100;
BA_ "GenSigCycleTimeActive" SG_ 1590 SavedUnit17_TrailerName 100;
BA_ "GenSigMaxLatency" SG_ 1590 SavedUnit17_TrailerName 10000;
BA_ "GenSigSendType" SG_ 1589 VMCU_BB2_136P_FCS 7;
BA_ "GenSigCycleTime" SG_ 1588 SavedUnit16_TrailerName 100;
BA_ "GenSigCycleTimeActive" SG_ 1588 SavedUnit16_TrailerName 100;
BA_ "GenSigMaxLatency" SG_ 1588 SavedUnit16_TrailerName 10000;
BA_ "GenSigCycleTime" SG_ 1588 SavedUnit16_TrailerPosition 100;
BA_ "GenSigCycleTimeActive" SG_ 1588 SavedUnit16_TrailerPosition 100;
BA_ "GenSigStartValue" SG_ 1588 SavedUnit16_TrailerPosition 7;
BA_ "GenSigMaxLatency" SG_ 1588 SavedUnit16_TrailerPosition 10000;
BA_ "GenSigSendType" SG_ 1587 VMCU_BB2_135P_FCS 7;
BA_ "GenSigCycleTime" SG_ 1586 SavedUnit15_TrailerName 100;
BA_ "GenSigCycleTimeActive" SG_ 1586 SavedUnit15_TrailerName 100;
BA_ "GenSigMaxLatency" SG_ 1586 SavedUnit15_TrailerName 10000;
BA_ "GenSigCycleTime" SG_ 1586 SavedUnit15_TrailerPosition 100;
BA_ "GenSigCycleTimeActive" SG_ 1586 SavedUnit15_TrailerPosition 100;
BA_ "GenSigStartValue" SG_ 1586 SavedUnit15_TrailerPosition 7;
BA_ "GenSigMaxLatency" SG_ 1586 SavedUnit15_TrailerPosition 10000;
BA_ "GenSigSendType" SG_ 1585 VMCU_BB2_134P_FCS 7;
BA_ "GenSigCycleTime" SG_ 1584 SavedUnit14_TrailerPosition 100;
BA_ "GenSigCycleTimeActive" SG_ 1584 SavedUnit14_TrailerPosition 100;
BA_ "GenSigStartValue" SG_ 1584 SavedUnit14_TrailerPosition 7;
BA_ "GenSigMaxLatency" SG_ 1584 SavedUnit14_TrailerPosition 10000;
BA_ "GenSigCycleTime" SG_ 1584 SavedUnit14_TrailerName 100;
BA_ "GenSigCycleTimeActive" SG_ 1584 SavedUnit14_TrailerName 100;
BA_ "GenSigMaxLatency" SG_ 1584 SavedUnit14_TrailerName 10000;
BA_ "GenSigSendType" SG_ 1577 VMCU_BB2_133P_FCS 7;
BA_ "GenSigCycleTime" SG_ 1576 SavedUnit13_TrailerPosition 100;
BA_ "GenSigCycleTimeActive" SG_ 1576 SavedUnit13_TrailerPosition 100;
BA_ "GenSigStartValue" SG_ 1576 SavedUnit13_TrailerPosition 7;
BA_ "GenSigMaxLatency" SG_ 1576 SavedUnit13_TrailerPosition 10000;
BA_ "GenSigCycleTime" SG_ 1576 SavedUnit13_TrailerName 100;
BA_ "GenSigCycleTimeActive" SG_ 1576 SavedUnit13_TrailerName 100;
BA_ "GenSigMaxLatency" SG_ 1576 SavedUnit13_TrailerName 10000;
BA_ "GenSigSendType" SG_ 1575 VMCU_BB2_132P_FCS 7;
BA_ "GenSigCycleTime" SG_ 1574 SavedUnit12_TrailerName 100;
BA_ "GenSigCycleTimeActive" SG_ 1574 SavedUnit12_TrailerName 100;
BA_ "GenSigMaxLatency" SG_ 1574 SavedUnit12_TrailerName 10000;
BA_ "GenSigCycleTime" SG_ 1574 SavedUnit12_TrailerPosition 100;
BA_ "GenSigCycleTimeActive" SG_ 1574 SavedUnit12_TrailerPosition 100;
BA_ "GenSigStartValue" SG_ 1574 SavedUnit12_TrailerPosition 7;
BA_ "GenSigMaxLatency" SG_ 1574 SavedUnit12_TrailerPosition 10000;
BA_ "GenSigSendType" SG_ 1573 VMCU_BB2_131P_FCS 7;
BA_ "GenSigCycleTime" SG_ 1572 SavedUnit11_TrailerPosition 100;
BA_ "GenSigCycleTimeActive" SG_ 1572 SavedUnit11_TrailerPosition 100;
BA_ "GenSigStartValue" SG_ 1572 SavedUnit11_TrailerPosition 7;
BA_ "GenSigMaxLatency" SG_ 1572 SavedUnit11_TrailerPosition 10000;
BA_ "GenSigCycleTime" SG_ 1572 SavedUnit11_TrailerName 100;
BA_ "GenSigCycleTimeActive" SG_ 1572 SavedUnit11_TrailerName 100;
BA_ "GenSigMaxLatency" SG_ 1572 SavedUnit11_TrailerName 10000;
BA_ "GenSigSendType" SG_ 1571 VMCU_BB2_130P_FCS 7;
BA_ "GenSigCycleTime" SG_ 1570 SavedUnit10_TrailerName 100;
BA_ "GenSigCycleTimeActive" SG_ 1570 SavedUnit10_TrailerName 100;
BA_ "GenSigMaxLatency" SG_ 1570 SavedUnit10_TrailerName 10000;
BA_ "GenSigCycleTime" SG_ 1570 SavedUnit10_TrailerPosition 100;
BA_ "GenSigCycleTimeActive" SG_ 1570 SavedUnit10_TrailerPosition 100;
BA_ "GenSigStartValue" SG_ 1570 SavedUnit10_TrailerPosition 7;
BA_ "GenSigMaxLatency" SG_ 1570 SavedUnit10_TrailerPosition 10000;
BA_ "GenSigSendType" SG_ 1569 VMCU_BB2_129P_FCS 7;
BA_ "GenSigCycleTime" SG_ 1568 SavedUnit9_TrailerName 100;
BA_ "GenSigCycleTimeActive" SG_ 1568 SavedUnit9_TrailerName 100;
BA_ "GenSigMaxLatency" SG_ 1568 SavedUnit9_TrailerName 10000;
BA_ "GenSigCycleTime" SG_ 1568 SavedUnit9_TrailerPosition 100;
BA_ "GenSigCycleTimeActive" SG_ 1568 SavedUnit9_TrailerPosition 100;
BA_ "GenSigStartValue" SG_ 1568 SavedUnit9_TrailerPosition 7;
BA_ "GenSigMaxLatency" SG_ 1568 SavedUnit9_TrailerPosition 10000;
BA_ "GenSigSendType" SG_ 1567 VMCU_BB2_128P_FCS 7;
BA_ "GenSigCycleTime" SG_ 1566 SavedUnit8_TrailerName 100;
BA_ "GenSigCycleTimeActive" SG_ 1566 SavedUnit8_TrailerName 100;
BA_ "GenSigMaxLatency" SG_ 1566 SavedUnit8_TrailerName 10000;
BA_ "GenSigCycleTime" SG_ 1566 SavedUnit8_TrailerPosition 100;
BA_ "GenSigCycleTimeActive" SG_ 1566 SavedUnit8_TrailerPosition 100;
BA_ "GenSigStartValue" SG_ 1566 SavedUnit8_TrailerPosition 7;
BA_ "GenSigMaxLatency" SG_ 1566 SavedUnit8_TrailerPosition 10000;
BA_ "GenSigSendType" SG_ 1565 VMCU_BB2_127P_FCS 7;
BA_ "GenSigCycleTime" SG_ 1564 SavedUnit7_TrailerPosition 100;
BA_ "GenSigCycleTimeActive" SG_ 1564 SavedUnit7_TrailerPosition 100;
BA_ "GenSigStartValue" SG_ 1564 SavedUnit7_TrailerPosition 7;
BA_ "GenSigMaxLatency" SG_ 1564 SavedUnit7_TrailerPosition 10000;
BA_ "GenSigCycleTime" SG_ 1564 SavedUnit7_TrailerName 100;
BA_ "GenSigCycleTimeActive" SG_ 1564 SavedUnit7_TrailerName 100;
BA_ "GenSigMaxLatency" SG_ 1564 SavedUnit7_TrailerName 10000;
BA_ "GenSigSendType" SG_ 1563 VMCU_BB2_126P_FCS 7;
BA_ "GenSigCycleTime" SG_ 1562 SavedUnit6_TrailerPosition 100;
BA_ "GenSigCycleTimeActive" SG_ 1562 SavedUnit6_TrailerPosition 100;
BA_ "GenSigStartValue" SG_ 1562 SavedUnit6_TrailerPosition 7;
BA_ "GenSigMaxLatency" SG_ 1562 SavedUnit6_TrailerPosition 10000;
BA_ "GenSigCycleTime" SG_ 1562 SavedUnit6_TrailerName 100;
BA_ "GenSigCycleTimeActive" SG_ 1562 SavedUnit6_TrailerName 100;
BA_ "GenSigMaxLatency" SG_ 1562 SavedUnit6_TrailerName 10000;
BA_ "GenSigSendType" SG_ 1561 VMCU_BB2_125P_FCS 7;
BA_ "GenSigCycleTime" SG_ 1560 SavedUnit5_TrailerName 100;
BA_ "GenSigCycleTimeActive" SG_ 1560 SavedUnit5_TrailerName 100;
BA_ "GenSigMaxLatency" SG_ 1560 SavedUnit5_TrailerName 10000;
BA_ "GenSigCycleTime" SG_ 1560 SavedUnit5_TrailerPosition 100;
BA_ "GenSigCycleTimeActive" SG_ 1560 SavedUnit5_TrailerPosition 100;
BA_ "GenSigStartValue" SG_ 1560 SavedUnit5_TrailerPosition 7;
BA_ "GenSigMaxLatency" SG_ 1560 SavedUnit5_TrailerPosition 10000;
BA_ "GenSigSendType" SG_ 1559 VMCU_BB2_124P_FCS 7;
BA_ "GenSigCycleTime" SG_ 1558 SavedUnit4_TrailerPosition 100;
BA_ "GenSigCycleTimeActive" SG_ 1558 SavedUnit4_TrailerPosition 100;
BA_ "GenSigStartValue" SG_ 1558 SavedUnit4_TrailerPosition 7;
BA_ "GenSigMaxLatency" SG_ 1558 SavedUnit4_TrailerPosition 10000;
BA_ "GenSigCycleTime" SG_ 1558 SavedUnit4_TrailerName 100;
BA_ "GenSigCycleTimeActive" SG_ 1558 SavedUnit4_TrailerName 100;
BA_ "GenSigMaxLatency" SG_ 1558 SavedUnit4_TrailerName 10000;
BA_ "GenSigSendType" SG_ 1557 VMCU_BB2_123P_FCS 7;
BA_ "GenSigCycleTime" SG_ 1556 SavedUnit3_TrailerPosition 100;
BA_ "GenSigCycleTimeActive" SG_ 1556 SavedUnit3_TrailerPosition 100;
BA_ "GenSigStartValue" SG_ 1556 SavedUnit3_TrailerPosition 7;
BA_ "GenSigMaxLatency" SG_ 1556 SavedUnit3_TrailerPosition 10000;
BA_ "GenSigCycleTime" SG_ 1556 SavedUnit3_TrailerName 100;
BA_ "GenSigCycleTimeActive" SG_ 1556 SavedUnit3_TrailerName 100;
BA_ "GenSigMaxLatency" SG_ 1556 SavedUnit3_TrailerName 10000;
BA_ "GenSigSendType" SG_ 1555 VMCU_BB2_122P_FCS 7;
BA_ "GenSigCycleTime" SG_ 1554 SavedUnit2_TrailerName 100;
BA_ "GenSigCycleTimeActive" SG_ 1554 SavedUnit2_TrailerName 100;
BA_ "GenSigMaxLatency" SG_ 1554 SavedUnit2_TrailerName 10000;
BA_ "GenSigCycleTime" SG_ 1554 SavedUnit2_TrailerPosition 100;
BA_ "GenSigCycleTimeActive" SG_ 1554 SavedUnit2_TrailerPosition 100;
BA_ "GenSigStartValue" SG_ 1554 SavedUnit2_TrailerPosition 7;
BA_ "GenSigMaxLatency" SG_ 1554 SavedUnit2_TrailerPosition 10000;
BA_ "GenSigSendType" SG_ 1553 VMCU_BB2_121P_FCS 7;
BA_ "GenSigCycleTime" SG_ 1552 SavedUnit1_TrailerPosition 100;
BA_ "GenSigCycleTimeActive" SG_ 1552 SavedUnit1_TrailerPosition 100;
BA_ "GenSigStartValue" SG_ 1552 SavedUnit1_TrailerPosition 7;
BA_ "GenSigMaxLatency" SG_ 1552 SavedUnit1_TrailerPosition 10000;
BA_ "GenSigCycleTime" SG_ 1552 SavedUnit1_TrailerName 100;
BA_ "GenSigCycleTimeActive" SG_ 1552 SavedUnit1_TrailerName 100;
BA_ "GenSigMaxLatency" SG_ 1552 SavedUnit1_TrailerName 10000;
BA_ "GenSigCycleTime" SG_ 1293 EventTimerAck_Oper 100;
BA_ "GenSigCycleTimeActive" SG_ 1293 EventTimerAck_Oper 100;
BA_ "GenSigStartValue" SG_ 1293 EventTimerAck_Oper 7;
BA_ "GenSigCycleTime" SG_ 1293 EventTimerTrig_Id 100;
BA_ "GenSigCycleTimeActive" SG_ 1293 EventTimerTrig_Id 100;
BA_ "GenSigStartValue" SG_ 1293 EventTimerTrig_Id 255;
BA_ "GenSigCycleTime" SG_ 1293 LoadDistributionSelected2_ISig_4 100;
BA_ "GenSigCycleTimeActive" SG_ 1293 LoadDistributionSelected2_ISig_4 100;
BA_ "GenSigStartValue" SG_ 1293 LoadDistributionSelected2_ISig_4 15;
BA_ "GenSigCycleTime" SG_ 1293 EventTimerAck_Time 100;
BA_ "GenSigCycleTimeActive" SG_ 1293 EventTimerAck_Time 100;
BA_ "GenSigStartValue" SG_ 1293 EventTimerAck_Time 2097151;
BA_ "GenSigCycleTime" SG_ 1293 RSLAssistStatus 100;
BA_ "GenSigCycleTimeActive" SG_ 1293 RSLAssistStatus 100;
BA_ "GenSigStartValue" SG_ 1293 RSLAssistStatus 7;
BA_ "GenSigCycleTime" SG_ 1293 StartBatteryVoltageDisplay_ISig_ 100;
BA_ "GenSigCycleTimeActive" SG_ 1293 StartBatteryVoltageDisplay_ISig_ 100;
BA_ "GenSigStartValue" SG_ 1293 StartBatteryVoltageDisplay_ISig_ 65535;
BA_ "SystemSignalLongSymbol" SG_ 1293 StartBatteryVoltageDisplay_ISig_ "StartBatteryVoltageDisplay_ISig_4";
BA_ "GenSigCycleTime" SG_ 1293 EventTimerAck_Id 100;
BA_ "GenSigCycleTimeActive" SG_ 1293 EventTimerAck_Id 100;
BA_ "GenSigStartValue" SG_ 1293 EventTimerAck_Id 255;
BA_ "GenSigCycleTime" SG_ 1271 DayOfWeek_stat_ISig_4 100;
BA_ "GenSigCycleTimeActive" SG_ 1271 DayOfWeek_stat_ISig_4 100;
BA_ "GenSigStartValue" SG_ 1271 DayOfWeek_stat_ISig_4 15;
BA_ "GenSigMaxLatency" SG_ 1271 DayOfWeek_stat_ISig_4 71;
BA_ "Platform_VMCU1_Sig" SG_ 1271 DayOfWeek_stat_ISig_4 1;
BA_ "GenSigCycleTime" SG_ 1271 MinutesLocal_ISig_4 100;
BA_ "GenSigCycleTimeActive" SG_ 1271 MinutesLocal_ISig_4 100;
BA_ "GenSigStartValue" SG_ 1271 MinutesLocal_ISig_4 255;
BA_ "GenSigMaxLatency" SG_ 1271 MinutesLocal_ISig_4 121;
BA_ "Platform_VMCU1_Sig" SG_ 1271 MinutesLocal_ISig_4 1;
BA_ "GenSigCycleTime" SG_ 1271 DayLocal_ISig_4 100;
BA_ "GenSigCycleTimeActive" SG_ 1271 DayLocal_ISig_4 100;
BA_ "GenSigStartValue" SG_ 1271 DayLocal_ISig_4 255;
BA_ "GenSigMaxLatency" SG_ 1271 DayLocal_ISig_4 121;
BA_ "Platform_VMCU1_Sig" SG_ 1271 DayLocal_ISig_4 1;
BA_ "GenSigCycleTime" SG_ 1271 MonthLocal_ISig_4 100;
BA_ "GenSigCycleTimeActive" SG_ 1271 MonthLocal_ISig_4 100;
BA_ "GenSigStartValue" SG_ 1271 MonthLocal_ISig_4 255;
BA_ "GenSigMaxLatency" SG_ 1271 MonthLocal_ISig_4 121;
BA_ "Platform_VMCU1_Sig" SG_ 1271 MonthLocal_ISig_4 1;
BA_ "GenSigCycleTime" SG_ 1271 SecondsLocal_ISig_4 100;
BA_ "GenSigCycleTimeActive" SG_ 1271 SecondsLocal_ISig_4 100;
BA_ "GenSigStartValue" SG_ 1271 SecondsLocal_ISig_4 255;
BA_ "GenSigMaxLatency" SG_ 1271 SecondsLocal_ISig_4 121;
BA_ "Platform_VMCU1_Sig" SG_ 1271 SecondsLocal_ISig_4 1;
BA_ "GenSigCycleTime" SG_ 1271 SelectedDaylightSaving_stat 100;
BA_ "GenSigCycleTimeActive" SG_ 1271 SelectedDaylightSaving_stat 100;
BA_ "GenSigStartValue" SG_ 1271 SelectedDaylightSaving_stat 3;
BA_ "GenSigCycleTime" SG_ 1271 SavedHeightControlMode_ISig_4 100;
BA_ "GenSigCycleTimeActive" SG_ 1271 SavedHeightControlMode_ISig_4 100;
BA_ "GenSigStartValue" SG_ 1271 SavedHeightControlMode_ISig_4 3;
BA_ "GenSigCycleTime" SG_ 1271 YearLocal_ISig_4 100;
BA_ "GenSigCycleTimeActive" SG_ 1271 YearLocal_ISig_4 100;
BA_ "GenSigStartValue" SG_ 1271 YearLocal_ISig_4 255;
BA_ "GenSigMaxLatency" SG_ 1271 YearLocal_ISig_4 121;
BA_ "Platform_VMCU1_Sig" SG_ 1271 YearLocal_ISig_4 1;
BA_ "GenSigCycleTime" SG_ 1271 HoursLocal_ISig_4 100;
BA_ "GenSigCycleTimeActive" SG_ 1271 HoursLocal_ISig_4 100;
BA_ "GenSigStartValue" SG_ 1271 HoursLocal_ISig_4 255;
BA_ "GenSigMaxLatency" SG_ 1271 HoursLocal_ISig_4 121;
BA_ "Platform_VMCU1_Sig" SG_ 1271 HoursLocal_ISig_4 1;
BA_ "GenSigCycleTime" SG_ 391 RequestedUpshiftDownshiftSteps 100;
BA_ "GenSigCycleTimeActive" SG_ 391 RequestedUpshiftDownshiftSteps 100;
BA_ "GenSigStartValue" SG_ 391 RequestedUpshiftDownshiftSteps 7;
BA_ "GenSigMaxLatency" SG_ 391 RequestedUpshiftDownshiftSteps 26;
BA_ "Platform_VMCU1_Sig" SG_ 391 RequestedUpshiftDownshiftSteps 1;
BA_ "SeToolAncestorID_SIGNAL" SG_ 391 RequestedUpshiftDownshiftSteps "x0000001D041B21AC";
BA_ "SeToolItemID_SIGNAL" SG_ 391 RequestedUpshiftDownshiftSteps "x0000001D041B21AC";
BA_ "SeToolName_SIGNAL" SG_ 391 RequestedUpshiftDownshiftSteps "RequestedUpshiftDownshiftSteps";
BA_ "SeToolVersion_SIGNAL" SG_ 391 RequestedUpshiftDownshiftSteps "1";
BA_ "GenSigCycleTime" SG_ 391 GearLeverPosition_ISig_4 100;
BA_ "GenSigCycleTimeActive" SG_ 391 GearLeverPosition_ISig_4 100;
BA_ "GenSigStartValue" SG_ 391 GearLeverPosition_ISig_4 15;
BA_ "GenSigMaxLatency" SG_ 391 GearLeverPosition_ISig_4 26;
BA_ "NeedsUpdateBit" SG_ 391 GearLeverPosition_ISig_4 1;
BA_ "Platform_VMCU1_Sig" SG_ 391 GearLeverPosition_ISig_4 1;
BA_ "SeToolAncestorID_SIGNAL" SG_ 391 GearLeverPosition_ISig_4 "x0000001D0412B683";
BA_ "SeToolItemID_SIGNAL" SG_ 391 GearLeverPosition_ISig_4 "x0000001D0412B683";
BA_ "SeToolName_SIGNAL" SG_ 391 GearLeverPosition_ISig_4 "GearLeverPosition";
BA_ "SeToolVersion_SIGNAL" SG_ 391 GearLeverPosition_ISig_4 "1";
BA_ "GenSigCycleTime" SG_ 391 DownShiftRequest 100;
BA_ "GenSigCycleTimeActive" SG_ 391 DownShiftRequest 100;
BA_ "GenSigStartValue" SG_ 391 DownShiftRequest 3;
BA_ "GenSigMaxLatency" SG_ 391 DownShiftRequest 26;
BA_ "Platform_VMCU1_Sig" SG_ 391 DownShiftRequest 1;
BA_ "SeToolAncestorID_SIGNAL" SG_ 391 DownShiftRequest "x0000001D0416F343";
BA_ "SeToolItemID_SIGNAL" SG_ 391 DownShiftRequest "x0000001D0428EB01";
BA_ "SeToolName_SIGNAL" SG_ 391 DownShiftRequest "DownShiftRequest";
BA_ "SeToolVersion_SIGNAL" SG_ 391 DownShiftRequest "2";
BA_ "GenSigCycleTime" SG_ 391 UpShiftRequest 100;
BA_ "GenSigCycleTimeActive" SG_ 391 UpShiftRequest 100;
BA_ "GenSigStartValue" SG_ 391 UpShiftRequest 3;
BA_ "GenSigMaxLatency" SG_ 391 UpShiftRequest 26;
BA_ "Platform_VMCU1_Sig" SG_ 391 UpShiftRequest 1;
BA_ "SeToolAncestorID_SIGNAL" SG_ 391 UpShiftRequest "x0000001D0416F32D";
BA_ "SeToolItemID_SIGNAL" SG_ 391 UpShiftRequest "x0000001D0416F32D";
BA_ "SeToolName_SIGNAL" SG_ 391 UpShiftRequest "UpShiftRequest";
BA_ "SeToolVersion_SIGNAL" SG_ 391 UpShiftRequest "1";
BA_ "GenSigSendType" SG_ 391 GearLeverPosition_UB_ISig_4 7;
BA_ "Platform_VMCU1_Sig" SG_ 391 GearLeverPosition_UB_ISig_4 1;
BA_ "GenSigCycleTime" SG_ 391 LimpHomeSwitch_stat 100;
BA_ "GenSigCycleTimeActive" SG_ 391 LimpHomeSwitch_stat 100;
BA_ "GenSigStartValue" SG_ 391 LimpHomeSwitch_stat 3;
BA_ "GenSigMaxLatency" SG_ 391 LimpHomeSwitch_stat 26;
BA_ "Platform_VMCU1_Sig" SG_ 391 LimpHomeSwitch_stat 1;
BA_ "SeToolAncestorID_SIGNAL" SG_ 391 LimpHomeSwitch_stat "x0000001D0423C430";
BA_ "SeToolItemID_SIGNAL" SG_ 391 LimpHomeSwitch_stat "x0000001D0423C430";
BA_ "SeToolName_SIGNAL" SG_ 391 LimpHomeSwitch_stat "LimpHomeSwitch_stat";
BA_ "SeToolVersion_SIGNAL" SG_ 391 LimpHomeSwitch_stat "1";
BA_ "GenSigCycleTime" SG_ 391 RequestForHighestGearRatio 100;
BA_ "GenSigCycleTimeActive" SG_ 391 RequestForHighestGearRatio 100;
BA_ "GenSigStartValue" SG_ 391 RequestForHighestGearRatio 3;
BA_ "GenSigMaxLatency" SG_ 391 RequestForHighestGearRatio 26;
BA_ "Platform_VMCU1_Sig" SG_ 391 RequestForHighestGearRatio 1;
BA_ "SeToolAncestorID_SIGNAL" SG_ 391 RequestForHighestGearRatio "x0000001D0416F366";
BA_ "SeToolItemID_SIGNAL" SG_ 391 RequestForHighestGearRatio "x0000001D0416F366";
BA_ "SeToolName_SIGNAL" SG_ 391 RequestForHighestGearRatio "RequestForHighestGearRatio";
BA_ "SeToolVersion_SIGNAL" SG_ 391 RequestForHighestGearRatio "1";
BA_ "GenSigCycleTime" SG_ 391 EconomyPowerSwitch_stat 100;
BA_ "GenSigCycleTimeActive" SG_ 391 EconomyPowerSwitch_stat 100;
BA_ "GenSigStartValue" SG_ 391 EconomyPowerSwitch_stat 3;
BA_ "GenSigMaxLatency" SG_ 391 EconomyPowerSwitch_stat 26;
BA_ "Platform_VMCU1_Sig" SG_ 391 EconomyPowerSwitch_stat 1;
BA_ "SeToolAncestorID_SIGNAL" SG_ 391 EconomyPowerSwitch_stat "x0000001D0423C42E";
BA_ "SeToolItemID_SIGNAL" SG_ 391 EconomyPowerSwitch_stat "x0000001D0423C42E";
BA_ "SeToolName_SIGNAL" SG_ 391 EconomyPowerSwitch_stat "EconomyPowerSwitch_stat";
BA_ "SeToolVersion_SIGNAL" SG_ 391 EconomyPowerSwitch_stat "1";
BA_ "GenSigCycleTime" SG_ 391 SteeringValvePositionSetPoint 100;
BA_ "GenSigCycleTimeActive" SG_ 391 SteeringValvePositionSetPoint 100;
BA_ "GenSigStartValue" SG_ 391 SteeringValvePositionSetPoint 255;
BA_ "GenSigSendType" SG_ 1326 VMCU_BB2_116S_FCS 7;
BA_ "GenSigSendType" SG_ 1321 CalDataLoadP5_ScaleLoad_ISig_4 1;
BA_ "GenSigCycleTime" SG_ 1321 CalDataLoadP5_ScaleLoad_ISig_4 100;
BA_ "GenSigCycleTimeActive" SG_ 1321 CalDataLoadP5_ScaleLoad_ISig_4 100;
BA_ "GenSigStartValue" SG_ 1321 CalDataLoadP5_ScaleLoad_ISig_4 65535;
BA_ "GenSigMaxLatency" SG_ 1321 CalDataLoadP5_ScaleLoad_ISig_4 1000;
BA_ "NeedsUpdateBit" SG_ 1321 CalDataLoadP5_ScaleLoad_ISig_4 1;
BA_ "GenSigSendType" SG_ 1321 CalDataLoadP5_UncalLoad_ISig_4 1;
BA_ "GenSigCycleTime" SG_ 1321 CalDataLoadP5_UncalLoad_ISig_4 100;
BA_ "GenSigCycleTimeActive" SG_ 1321 CalDataLoadP5_UncalLoad_ISig_4 100;
BA_ "GenSigStartValue" SG_ 1321 CalDataLoadP5_UncalLoad_ISig_4 65535;
BA_ "GenSigMaxLatency" SG_ 1321 CalDataLoadP5_UncalLoad_ISig_4 1000;
BA_ "NeedsUpdateBit" SG_ 1321 CalDataLoadP5_UncalLoad_ISig_4 1;
BA_ "GenSigSendType" SG_ 1321 CalDataLoadP5_sg_UB_ISig_4 7;
BA_ "GenSigSendType" SG_ 1321 CalDataLoadP5_YearUTC_ISig_4 1;
BA_ "GenSigCycleTime" SG_ 1321 CalDataLoadP5_YearUTC_ISig_4 100;
BA_ "GenSigCycleTimeActive" SG_ 1321 CalDataLoadP5_YearUTC_ISig_4 100;
BA_ "GenSigStartValue" SG_ 1321 CalDataLoadP5_YearUTC_ISig_4 255;
BA_ "GenSigMaxLatency" SG_ 1321 CalDataLoadP5_YearUTC_ISig_4 1000;
BA_ "NeedsUpdateBit" SG_ 1321 CalDataLoadP5_YearUTC_ISig_4 1;
BA_ "GenSigSendType" SG_ 1321 CalDataLoadP5_VehicleID_ISig_4 1;
BA_ "GenSigCycleTime" SG_ 1321 CalDataLoadP5_VehicleID_ISig_4 100;
BA_ "GenSigCycleTimeActive" SG_ 1321 CalDataLoadP5_VehicleID_ISig_4 100;
BA_ "GenSigStartValue" SG_ 1321 CalDataLoadP5_VehicleID_ISig_4 7;
BA_ "GenSigMaxLatency" SG_ 1321 CalDataLoadP5_VehicleID_ISig_4 1000;
BA_ "NeedsUpdateBit" SG_ 1321 CalDataLoadP5_VehicleID_ISig_4 1;
BA_ "GenSigSendType" SG_ 1321 CalDataLoadP5_AxleID_ISig_4 1;
BA_ "GenSigCycleTime" SG_ 1321 CalDataLoadP5_AxleID_ISig_4 100;
BA_ "GenSigCycleTimeActive" SG_ 1321 CalDataLoadP5_AxleID_ISig_4 100;
BA_ "GenSigStartValue" SG_ 1321 CalDataLoadP5_AxleID_ISig_4 15;
BA_ "GenSigMaxLatency" SG_ 1321 CalDataLoadP5_AxleID_ISig_4 1000;
BA_ "NeedsUpdateBit" SG_ 1321 CalDataLoadP5_AxleID_ISig_4 1;
BA_ "GenSigSendType" SG_ 1321 CalDataLoadP5_DayUTC_ISig_4 1;
BA_ "GenSigCycleTime" SG_ 1321 CalDataLoadP5_DayUTC_ISig_4 100;
BA_ "GenSigCycleTimeActive" SG_ 1321 CalDataLoadP5_DayUTC_ISig_4 100;
BA_ "GenSigStartValue" SG_ 1321 CalDataLoadP5_DayUTC_ISig_4 255;
BA_ "GenSigMaxLatency" SG_ 1321 CalDataLoadP5_DayUTC_ISig_4 1000;
BA_ "NeedsUpdateBit" SG_ 1321 CalDataLoadP5_DayUTC_ISig_4 1;
BA_ "GenSigSendType" SG_ 1321 CalDataLoadP5_HoursUTC_ISig_4 1;
BA_ "GenSigCycleTime" SG_ 1321 CalDataLoadP5_HoursUTC_ISig_4 100;
BA_ "GenSigCycleTimeActive" SG_ 1321 CalDataLoadP5_HoursUTC_ISig_4 100;
BA_ "GenSigStartValue" SG_ 1321 CalDataLoadP5_HoursUTC_ISig_4 255;
BA_ "GenSigMaxLatency" SG_ 1321 CalDataLoadP5_HoursUTC_ISig_4 1000;
BA_ "NeedsUpdateBit" SG_ 1321 CalDataLoadP5_HoursUTC_ISig_4 1;
BA_ "GenSigSendType" SG_ 1321 CalDataLoadP5_MinutesUTC_ISig_4 1;
BA_ "GenSigCycleTime" SG_ 1321 CalDataLoadP5_MinutesUTC_ISig_4 100;
BA_ "GenSigCycleTimeActive" SG_ 1321 CalDataLoadP5_MinutesUTC_ISig_4 100;
BA_ "GenSigStartValue" SG_ 1321 CalDataLoadP5_MinutesUTC_ISig_4 255;
BA_ "GenSigMaxLatency" SG_ 1321 CalDataLoadP5_MinutesUTC_ISig_4 1000;
BA_ "NeedsUpdateBit" SG_ 1321 CalDataLoadP5_MinutesUTC_ISig_4 1;
BA_ "GenSigSendType" SG_ 1321 CalDataLoadP5_QF_ISig_4 1;
BA_ "GenSigCycleTime" SG_ 1321 CalDataLoadP5_QF_ISig_4 100;
BA_ "GenSigCycleTimeActive" SG_ 1321 CalDataLoadP5_QF_ISig_4 100;
BA_ "GenSigStartValue" SG_ 1321 CalDataLoadP5_QF_ISig_4 65535;
BA_ "GenSigMaxLatency" SG_ 1321 CalDataLoadP5_QF_ISig_4 1000;
BA_ "GenSigSendType" SG_ 1321 CalDataLoadP5_MonthUTC_ISig_4 1;
BA_ "GenSigCycleTime" SG_ 1321 CalDataLoadP5_MonthUTC_ISig_4 100;
BA_ "GenSigCycleTimeActive" SG_ 1321 CalDataLoadP5_MonthUTC_ISig_4 100;
BA_ "GenSigStartValue" SG_ 1321 CalDataLoadP5_MonthUTC_ISig_4 255;
BA_ "GenSigMaxLatency" SG_ 1321 CalDataLoadP5_MonthUTC_ISig_4 1000;
BA_ "NeedsUpdateBit" SG_ 1321 CalDataLoadP5_MonthUTC_ISig_4 1;
BA_ "GenSigSendType" SG_ 1325 VMCU_BB2_115S_FCS 7;
BA_ "GenSigSendType" SG_ 1320 CalDataLoadP4_DayUTC_ISig_4 1;
BA_ "GenSigCycleTime" SG_ 1320 CalDataLoadP4_DayUTC_ISig_4 100;
BA_ "GenSigCycleTimeActive" SG_ 1320 CalDataLoadP4_DayUTC_ISig_4 100;
BA_ "GenSigStartValue" SG_ 1320 CalDataLoadP4_DayUTC_ISig_4 255;
BA_ "GenSigMaxLatency" SG_ 1320 CalDataLoadP4_DayUTC_ISig_4 1000;
BA_ "NeedsUpdateBit" SG_ 1320 CalDataLoadP4_DayUTC_ISig_4 1;
BA_ "GenSigSendType" SG_ 1320 CalDataLoadP4_ScaleLoad_ISig_4 1;
BA_ "GenSigCycleTime" SG_ 1320 CalDataLoadP4_ScaleLoad_ISig_4 100;
BA_ "GenSigCycleTimeActive" SG_ 1320 CalDataLoadP4_ScaleLoad_ISig_4 100;
BA_ "GenSigStartValue" SG_ 1320 CalDataLoadP4_ScaleLoad_ISig_4 65535;
BA_ "GenSigMaxLatency" SG_ 1320 CalDataLoadP4_ScaleLoad_ISig_4 1000;
BA_ "NeedsUpdateBit" SG_ 1320 CalDataLoadP4_ScaleLoad_ISig_4 1;
BA_ "GenSigSendType" SG_ 1320 CalDataLoadP4_sg_UB_ISig_4 7;
BA_ "GenSigSendType" SG_ 1320 CalDataLoadP4_YearUTC_ISig_4 1;
BA_ "GenSigCycleTime" SG_ 1320 CalDataLoadP4_YearUTC_ISig_4 100;
BA_ "GenSigCycleTimeActive" SG_ 1320 CalDataLoadP4_YearUTC_ISig_4 100;
BA_ "GenSigStartValue" SG_ 1320 CalDataLoadP4_YearUTC_ISig_4 255;
BA_ "GenSigMaxLatency" SG_ 1320 CalDataLoadP4_YearUTC_ISig_4 1000;
BA_ "NeedsUpdateBit" SG_ 1320 CalDataLoadP4_YearUTC_ISig_4 1;
BA_ "GenSigSendType" SG_ 1320 CalDataLoadP4_AxleID_ISig_4 1;
BA_ "GenSigCycleTime" SG_ 1320 CalDataLoadP4_AxleID_ISig_4 100;
BA_ "GenSigCycleTimeActive" SG_ 1320 CalDataLoadP4_AxleID_ISig_4 100;
BA_ "GenSigStartValue" SG_ 1320 CalDataLoadP4_AxleID_ISig_4 15;
BA_ "GenSigMaxLatency" SG_ 1320 CalDataLoadP4_AxleID_ISig_4 1000;
BA_ "NeedsUpdateBit" SG_ 1320 CalDataLoadP4_AxleID_ISig_4 1;
BA_ "GenSigSendType" SG_ 1320 CalDataLoadP4_UncalLoad_ISig_4 1;
BA_ "GenSigCycleTime" SG_ 1320 CalDataLoadP4_UncalLoad_ISig_4 100;
BA_ "GenSigCycleTimeActive" SG_ 1320 CalDataLoadP4_UncalLoad_ISig_4 100;
BA_ "GenSigStartValue" SG_ 1320 CalDataLoadP4_UncalLoad_ISig_4 65535;
BA_ "GenSigMaxLatency" SG_ 1320 CalDataLoadP4_UncalLoad_ISig_4 1000;
BA_ "NeedsUpdateBit" SG_ 1320 CalDataLoadP4_UncalLoad_ISig_4 1;
BA_ "GenSigSendType" SG_ 1320 CalDataLoadP4_VehicleID_ISig_4 1;
BA_ "GenSigCycleTime" SG_ 1320 CalDataLoadP4_VehicleID_ISig_4 100;
BA_ "GenSigCycleTimeActive" SG_ 1320 CalDataLoadP4_VehicleID_ISig_4 100;
BA_ "GenSigStartValue" SG_ 1320 CalDataLoadP4_VehicleID_ISig_4 7;
BA_ "GenSigMaxLatency" SG_ 1320 CalDataLoadP4_VehicleID_ISig_4 1000;
BA_ "NeedsUpdateBit" SG_ 1320 CalDataLoadP4_VehicleID_ISig_4 1;
BA_ "GenSigSendType" SG_ 1320 CalDataLoadP4_MinutesUTC_ISig_4 1;
BA_ "GenSigCycleTime" SG_ 1320 CalDataLoadP4_MinutesUTC_ISig_4 100;
BA_ "GenSigCycleTimeActive" SG_ 1320 CalDataLoadP4_MinutesUTC_ISig_4 100;
BA_ "GenSigStartValue" SG_ 1320 CalDataLoadP4_MinutesUTC_ISig_4 255;
BA_ "GenSigMaxLatency" SG_ 1320 CalDataLoadP4_MinutesUTC_ISig_4 1000;
BA_ "NeedsUpdateBit" SG_ 1320 CalDataLoadP4_MinutesUTC_ISig_4 1;
BA_ "GenSigSendType" SG_ 1320 CalDataLoadP4_HoursUTC_ISig_4 1;
BA_ "GenSigCycleTime" SG_ 1320 CalDataLoadP4_HoursUTC_ISig_4 100;
BA_ "GenSigCycleTimeActive" SG_ 1320 CalDataLoadP4_HoursUTC_ISig_4 100;
BA_ "GenSigStartValue" SG_ 1320 CalDataLoadP4_HoursUTC_ISig_4 255;
BA_ "GenSigMaxLatency" SG_ 1320 CalDataLoadP4_HoursUTC_ISig_4 1000;
BA_ "NeedsUpdateBit" SG_ 1320 CalDataLoadP4_HoursUTC_ISig_4 1;
BA_ "GenSigSendType" SG_ 1320 CalDataLoadP4_MonthUTC_ISig_4 1;
BA_ "GenSigCycleTime" SG_ 1320 CalDataLoadP4_MonthUTC_ISig_4 100;
BA_ "GenSigCycleTimeActive" SG_ 1320 CalDataLoadP4_MonthUTC_ISig_4 100;
BA_ "GenSigStartValue" SG_ 1320 CalDataLoadP4_MonthUTC_ISig_4 255;
BA_ "GenSigMaxLatency" SG_ 1320 CalDataLoadP4_MonthUTC_ISig_4 1000;
BA_ "NeedsUpdateBit" SG_ 1320 CalDataLoadP4_MonthUTC_ISig_4 1;
BA_ "GenSigSendType" SG_ 1320 CalDataLoadP4_QF_ISig_4 1;
BA_ "GenSigCycleTime" SG_ 1320 CalDataLoadP4_QF_ISig_4 100;
BA_ "GenSigCycleTimeActive" SG_ 1320 CalDataLoadP4_QF_ISig_4 100;
BA_ "GenSigStartValue" SG_ 1320 CalDataLoadP4_QF_ISig_4 65535;
BA_ "GenSigMaxLatency" SG_ 1320 CalDataLoadP4_QF_ISig_4 1000;
BA_ "GenSigSendType" SG_ 1324 VMCU_BB2_114S_FCS 7;
BA_ "GenSigSendType" SG_ 1319 CalDataLoadP3_HoursUTC_ISig_4 1;
BA_ "GenSigCycleTime" SG_ 1319 CalDataLoadP3_HoursUTC_ISig_4 100;
BA_ "GenSigCycleTimeActive" SG_ 1319 CalDataLoadP3_HoursUTC_ISig_4 100;
BA_ "GenSigStartValue" SG_ 1319 CalDataLoadP3_HoursUTC_ISig_4 255;
BA_ "GenSigMaxLatency" SG_ 1319 CalDataLoadP3_HoursUTC_ISig_4 1000;
BA_ "NeedsUpdateBit" SG_ 1319 CalDataLoadP3_HoursUTC_ISig_4 1;
BA_ "GenSigSendType" SG_ 1319 CalDataLoadP3_YearUTC_ISig_4 1;
BA_ "GenSigCycleTime" SG_ 1319 CalDataLoadP3_YearUTC_ISig_4 100;
BA_ "GenSigCycleTimeActive" SG_ 1319 CalDataLoadP3_YearUTC_ISig_4 100;
BA_ "GenSigStartValue" SG_ 1319 CalDataLoadP3_YearUTC_ISig_4 255;
BA_ "GenSigMaxLatency" SG_ 1319 CalDataLoadP3_YearUTC_ISig_4 1000;
BA_ "NeedsUpdateBit" SG_ 1319 CalDataLoadP3_YearUTC_ISig_4 1;
BA_ "GenSigSendType" SG_ 1319 CalDataLoadP3_MonthUTC_ISig_4 1;
BA_ "GenSigCycleTime" SG_ 1319 CalDataLoadP3_MonthUTC_ISig_4 100;
BA_ "GenSigCycleTimeActive" SG_ 1319 CalDataLoadP3_MonthUTC_ISig_4 100;
BA_ "GenSigStartValue" SG_ 1319 CalDataLoadP3_MonthUTC_ISig_4 255;
BA_ "GenSigMaxLatency" SG_ 1319 CalDataLoadP3_MonthUTC_ISig_4 1000;
BA_ "NeedsUpdateBit" SG_ 1319 CalDataLoadP3_MonthUTC_ISig_4 1;
BA_ "GenSigSendType" SG_ 1319 CalDataLoadP3_DayUTC_ISig_4 1;
BA_ "GenSigCycleTime" SG_ 1319 CalDataLoadP3_DayUTC_ISig_4 100;
BA_ "GenSigCycleTimeActive" SG_ 1319 CalDataLoadP3_DayUTC_ISig_4 100;
BA_ "GenSigStartValue" SG_ 1319 CalDataLoadP3_DayUTC_ISig_4 255;
BA_ "GenSigMaxLatency" SG_ 1319 CalDataLoadP3_DayUTC_ISig_4 1000;
BA_ "NeedsUpdateBit" SG_ 1319 CalDataLoadP3_DayUTC_ISig_4 1;
BA_ "GenSigSendType" SG_ 1319 CalDataLoadP3_sg_UB_ISig_4 7;
BA_ "GenSigSendType" SG_ 1319 CalDataLoadP3_MinutesUTC_ISig_4 1;
BA_ "GenSigCycleTime" SG_ 1319 CalDataLoadP3_MinutesUTC_ISig_4 100;
BA_ "GenSigCycleTimeActive" SG_ 1319 CalDataLoadP3_MinutesUTC_ISig_4 100;
BA_ "GenSigStartValue" SG_ 1319 CalDataLoadP3_MinutesUTC_ISig_4 255;
BA_ "GenSigMaxLatency" SG_ 1319 CalDataLoadP3_MinutesUTC_ISig_4 1000;
BA_ "NeedsUpdateBit" SG_ 1319 CalDataLoadP3_MinutesUTC_ISig_4 1;
BA_ "GenSigSendType" SG_ 1319 CalDataLoadP3_QF_ISig_4 1;
BA_ "GenSigCycleTime" SG_ 1319 CalDataLoadP3_QF_ISig_4 100;
BA_ "GenSigCycleTimeActive" SG_ 1319 CalDataLoadP3_QF_ISig_4 100;
BA_ "GenSigStartValue" SG_ 1319 CalDataLoadP3_QF_ISig_4 65535;
BA_ "GenSigMaxLatency" SG_ 1319 CalDataLoadP3_QF_ISig_4 1000;
BA_ "GenSigSendType" SG_ 1319 CalDataLoadP3_VehicleID_ISig_4 1;
BA_ "GenSigCycleTime" SG_ 1319 CalDataLoadP3_VehicleID_ISig_4 100;
BA_ "GenSigCycleTimeActive" SG_ 1319 CalDataLoadP3_VehicleID_ISig_4 100;
BA_ "GenSigStartValue" SG_ 1319 CalDataLoadP3_VehicleID_ISig_4 7;
BA_ "GenSigMaxLatency" SG_ 1319 CalDataLoadP3_VehicleID_ISig_4 1000;
BA_ "NeedsUpdateBit" SG_ 1319 CalDataLoadP3_VehicleID_ISig_4 1;
BA_ "GenSigSendType" SG_ 1319 CalDataLoadP3_UncalLoad_ISig_4 1;
BA_ "GenSigCycleTime" SG_ 1319 CalDataLoadP3_UncalLoad_ISig_4 100;
BA_ "GenSigCycleTimeActive" SG_ 1319 CalDataLoadP3_UncalLoad_ISig_4 100;
BA_ "GenSigStartValue" SG_ 1319 CalDataLoadP3_UncalLoad_ISig_4 65535;
BA_ "GenSigMaxLatency" SG_ 1319 CalDataLoadP3_UncalLoad_ISig_4 1000;
BA_ "NeedsUpdateBit" SG_ 1319 CalDataLoadP3_UncalLoad_ISig_4 1;
BA_ "GenSigSendType" SG_ 1319 CalDataLoadP3_AxleID_ISig_4 1;
BA_ "GenSigCycleTime" SG_ 1319 CalDataLoadP3_AxleID_ISig_4 100;
BA_ "GenSigCycleTimeActive" SG_ 1319 CalDataLoadP3_AxleID_ISig_4 100;
BA_ "GenSigStartValue" SG_ 1319 CalDataLoadP3_AxleID_ISig_4 15;
BA_ "GenSigMaxLatency" SG_ 1319 CalDataLoadP3_AxleID_ISig_4 1000;
BA_ "NeedsUpdateBit" SG_ 1319 CalDataLoadP3_AxleID_ISig_4 1;
BA_ "GenSigSendType" SG_ 1319 CalDataLoadP3_ScaleLoad_ISig_4 1;
BA_ "GenSigCycleTime" SG_ 1319 CalDataLoadP3_ScaleLoad_ISig_4 100;
BA_ "GenSigCycleTimeActive" SG_ 1319 CalDataLoadP3_ScaleLoad_ISig_4 100;
BA_ "GenSigStartValue" SG_ 1319 CalDataLoadP3_ScaleLoad_ISig_4 65535;
BA_ "GenSigMaxLatency" SG_ 1319 CalDataLoadP3_ScaleLoad_ISig_4 1000;
BA_ "NeedsUpdateBit" SG_ 1319 CalDataLoadP3_ScaleLoad_ISig_4 1;
BA_ "GenSigSendType" SG_ 1323 VMCU_BB2_113S_FCS 7;
BA_ "GenSigSendType" SG_ 1318 CalDataLoadP2_MinutesUTC_ISig_4 1;
BA_ "GenSigCycleTime" SG_ 1318 CalDataLoadP2_MinutesUTC_ISig_4 100;
BA_ "GenSigCycleTimeActive" SG_ 1318 CalDataLoadP2_MinutesUTC_ISig_4 100;
BA_ "GenSigStartValue" SG_ 1318 CalDataLoadP2_MinutesUTC_ISig_4 255;
BA_ "GenSigMaxLatency" SG_ 1318 CalDataLoadP2_MinutesUTC_ISig_4 1000;
BA_ "NeedsUpdateBit" SG_ 1318 CalDataLoadP2_MinutesUTC_ISig_4 1;
BA_ "GenSigSendType" SG_ 1318 CalDataLoadP2_AxleID_ISig_4 1;
BA_ "GenSigCycleTime" SG_ 1318 CalDataLoadP2_AxleID_ISig_4 100;
BA_ "GenSigCycleTimeActive" SG_ 1318 CalDataLoadP2_AxleID_ISig_4 100;
BA_ "GenSigStartValue" SG_ 1318 CalDataLoadP2_AxleID_ISig_4 15;
BA_ "GenSigMaxLatency" SG_ 1318 CalDataLoadP2_AxleID_ISig_4 1000;
BA_ "NeedsUpdateBit" SG_ 1318 CalDataLoadP2_AxleID_ISig_4 1;
BA_ "GenSigSendType" SG_ 1318 CalDataLoadP2_YearUTC_ISig_4 1;
BA_ "GenSigCycleTime" SG_ 1318 CalDataLoadP2_YearUTC_ISig_4 100;
BA_ "GenSigCycleTimeActive" SG_ 1318 CalDataLoadP2_YearUTC_ISig_4 100;
BA_ "GenSigStartValue" SG_ 1318 CalDataLoadP2_YearUTC_ISig_4 255;
BA_ "GenSigMaxLatency" SG_ 1318 CalDataLoadP2_YearUTC_ISig_4 1000;
BA_ "NeedsUpdateBit" SG_ 1318 CalDataLoadP2_YearUTC_ISig_4 1;
BA_ "GenSigSendType" SG_ 1318 CalDataLoadP2_UncalLoad_ISig_4 1;
BA_ "GenSigCycleTime" SG_ 1318 CalDataLoadP2_UncalLoad_ISig_4 100;
BA_ "GenSigCycleTimeActive" SG_ 1318 CalDataLoadP2_UncalLoad_ISig_4 100;
BA_ "GenSigStartValue" SG_ 1318 CalDataLoadP2_UncalLoad_ISig_4 65535;
BA_ "GenSigMaxLatency" SG_ 1318 CalDataLoadP2_UncalLoad_ISig_4 1000;
BA_ "NeedsUpdateBit" SG_ 1318 CalDataLoadP2_UncalLoad_ISig_4 1;
BA_ "GenSigSendType" SG_ 1318 CalDataLoadP2_DayUTC_ISig_4 1;
BA_ "GenSigCycleTime" SG_ 1318 CalDataLoadP2_DayUTC_ISig_4 100;
BA_ "GenSigCycleTimeActive" SG_ 1318 CalDataLoadP2_DayUTC_ISig_4 100;
BA_ "GenSigStartValue" SG_ 1318 CalDataLoadP2_DayUTC_ISig_4 255;
BA_ "GenSigMaxLatency" SG_ 1318 CalDataLoadP2_DayUTC_ISig_4 1000;
BA_ "NeedsUpdateBit" SG_ 1318 CalDataLoadP2_DayUTC_ISig_4 1;
BA_ "GenSigSendType" SG_ 1318 CalDataLoadP2_MonthUTC_ISig_4 1;
BA_ "GenSigCycleTime" SG_ 1318 CalDataLoadP2_MonthUTC_ISig_4 100;
BA_ "GenSigCycleTimeActive" SG_ 1318 CalDataLoadP2_MonthUTC_ISig_4 100;
BA_ "GenSigStartValue" SG_ 1318 CalDataLoadP2_MonthUTC_ISig_4 255;
BA_ "GenSigMaxLatency" SG_ 1318 CalDataLoadP2_MonthUTC_ISig_4 1000;
BA_ "NeedsUpdateBit" SG_ 1318 CalDataLoadP2_MonthUTC_ISig_4 1;
BA_ "GenSigSendType" SG_ 1318 CalDataLoadP2_VehicleID_ISig_4 1;
BA_ "GenSigCycleTime" SG_ 1318 CalDataLoadP2_VehicleID_ISig_4 100;
BA_ "GenSigCycleTimeActive" SG_ 1318 CalDataLoadP2_VehicleID_ISig_4 100;
BA_ "GenSigStartValue" SG_ 1318 CalDataLoadP2_VehicleID_ISig_4 7;
BA_ "GenSigMaxLatency" SG_ 1318 CalDataLoadP2_VehicleID_ISig_4 1000;
BA_ "NeedsUpdateBit" SG_ 1318 CalDataLoadP2_VehicleID_ISig_4 1;
BA_ "GenSigSendType" SG_ 1318 CalDataLoadP2_QF_ISig_4 1;
BA_ "GenSigCycleTime" SG_ 1318 CalDataLoadP2_QF_ISig_4 100;
BA_ "GenSigCycleTimeActive" SG_ 1318 CalDataLoadP2_QF_ISig_4 100;
BA_ "GenSigStartValue" SG_ 1318 CalDataLoadP2_QF_ISig_4 65535;
BA_ "GenSigMaxLatency" SG_ 1318 CalDataLoadP2_QF_ISig_4 1000;
BA_ "GenSigSendType" SG_ 1318 CalDataLoadP2_HoursUTC_ISig_4 1;
BA_ "GenSigCycleTime" SG_ 1318 CalDataLoadP2_HoursUTC_ISig_4 100;
BA_ "GenSigCycleTimeActive" SG_ 1318 CalDataLoadP2_HoursUTC_ISig_4 100;
BA_ "GenSigStartValue" SG_ 1318 CalDataLoadP2_HoursUTC_ISig_4 255;
BA_ "GenSigMaxLatency" SG_ 1318 CalDataLoadP2_HoursUTC_ISig_4 1000;
BA_ "NeedsUpdateBit" SG_ 1318 CalDataLoadP2_HoursUTC_ISig_4 1;
BA_ "GenSigSendType" SG_ 1318 CalDataLoadP2_sg_UB_ISig_4 7;
BA_ "GenSigSendType" SG_ 1318 CalDataLoadP2_ScaleLoad_ISig_4 1;
BA_ "GenSigCycleTime" SG_ 1318 CalDataLoadP2_ScaleLoad_ISig_4 100;
BA_ "GenSigCycleTimeActive" SG_ 1318 CalDataLoadP2_ScaleLoad_ISig_4 100;
BA_ "GenSigStartValue" SG_ 1318 CalDataLoadP2_ScaleLoad_ISig_4 65535;
BA_ "GenSigMaxLatency" SG_ 1318 CalDataLoadP2_ScaleLoad_ISig_4 1000;
BA_ "NeedsUpdateBit" SG_ 1318 CalDataLoadP2_ScaleLoad_ISig_4 1;
BA_ "GenSigSendType" SG_ 1322 VMCU_BB2_112S_FCS 7;
BA_ "GenSigSendType" SG_ 1317 CalDataLoadP1_ScaleLoad_ISig_4 1;
BA_ "GenSigCycleTime" SG_ 1317 CalDataLoadP1_ScaleLoad_ISig_4 100;
BA_ "GenSigCycleTimeActive" SG_ 1317 CalDataLoadP1_ScaleLoad_ISig_4 100;
BA_ "GenSigStartValue" SG_ 1317 CalDataLoadP1_ScaleLoad_ISig_4 65535;
BA_ "GenSigMaxLatency" SG_ 1317 CalDataLoadP1_ScaleLoad_ISig_4 1000;
BA_ "NeedsUpdateBit" SG_ 1317 CalDataLoadP1_ScaleLoad_ISig_4 1;
BA_ "GenSigSendType" SG_ 1317 CalDataLoadP1_YearUTC_ISig_4 1;
BA_ "GenSigCycleTime" SG_ 1317 CalDataLoadP1_YearUTC_ISig_4 100;
BA_ "GenSigCycleTimeActive" SG_ 1317 CalDataLoadP1_YearUTC_ISig_4 100;
BA_ "GenSigStartValue" SG_ 1317 CalDataLoadP1_YearUTC_ISig_4 255;
BA_ "GenSigMaxLatency" SG_ 1317 CalDataLoadP1_YearUTC_ISig_4 1000;
BA_ "NeedsUpdateBit" SG_ 1317 CalDataLoadP1_YearUTC_ISig_4 1;
BA_ "GenSigSendType" SG_ 1317 CalDataLoadP1_AxleID_ISig_4 1;
BA_ "GenSigCycleTime" SG_ 1317 CalDataLoadP1_AxleID_ISig_4 100;
BA_ "GenSigCycleTimeActive" SG_ 1317 CalDataLoadP1_AxleID_ISig_4 100;
BA_ "GenSigStartValue" SG_ 1317 CalDataLoadP1_AxleID_ISig_4 15;
BA_ "GenSigMaxLatency" SG_ 1317 CalDataLoadP1_AxleID_ISig_4 1000;
BA_ "NeedsUpdateBit" SG_ 1317 CalDataLoadP1_AxleID_ISig_4 1;
BA_ "GenSigSendType" SG_ 1317 CalDataLoadP1_MonthUTC_ISig_4 1;
BA_ "GenSigCycleTime" SG_ 1317 CalDataLoadP1_MonthUTC_ISig_4 100;
BA_ "GenSigCycleTimeActive" SG_ 1317 CalDataLoadP1_MonthUTC_ISig_4 100;
BA_ "GenSigStartValue" SG_ 1317 CalDataLoadP1_MonthUTC_ISig_4 255;
BA_ "GenSigMaxLatency" SG_ 1317 CalDataLoadP1_MonthUTC_ISig_4 1000;
BA_ "NeedsUpdateBit" SG_ 1317 CalDataLoadP1_MonthUTC_ISig_4 1;
BA_ "GenSigSendType" SG_ 1317 CalDataLoadP1_HoursUTC_ISig_4 1;
BA_ "GenSigCycleTime" SG_ 1317 CalDataLoadP1_HoursUTC_ISig_4 100;
BA_ "GenSigCycleTimeActive" SG_ 1317 CalDataLoadP1_HoursUTC_ISig_4 100;
BA_ "GenSigStartValue" SG_ 1317 CalDataLoadP1_HoursUTC_ISig_4 255;
BA_ "GenSigMaxLatency" SG_ 1317 CalDataLoadP1_HoursUTC_ISig_4 1000;
BA_ "NeedsUpdateBit" SG_ 1317 CalDataLoadP1_HoursUTC_ISig_4 1;
BA_ "GenSigSendType" SG_ 1317 CalDataLoadP1_VehicleID_ISig_4 1;
BA_ "GenSigCycleTime" SG_ 1317 CalDataLoadP1_VehicleID_ISig_4 100;
BA_ "GenSigCycleTimeActive" SG_ 1317 CalDataLoadP1_VehicleID_ISig_4 100;
BA_ "GenSigStartValue" SG_ 1317 CalDataLoadP1_VehicleID_ISig_4 7;
BA_ "GenSigMaxLatency" SG_ 1317 CalDataLoadP1_VehicleID_ISig_4 1000;
BA_ "NeedsUpdateBit" SG_ 1317 CalDataLoadP1_VehicleID_ISig_4 1;
BA_ "GenSigSendType" SG_ 1317 CalDataLoadP1_UncalLoad_ISig_4 1;
BA_ "GenSigCycleTime" SG_ 1317 CalDataLoadP1_UncalLoad_ISig_4 100;
BA_ "GenSigCycleTimeActive" SG_ 1317 CalDataLoadP1_UncalLoad_ISig_4 100;
BA_ "GenSigStartValue" SG_ 1317 CalDataLoadP1_UncalLoad_ISig_4 65535;
BA_ "GenSigMaxLatency" SG_ 1317 CalDataLoadP1_UncalLoad_ISig_4 1000;
BA_ "NeedsUpdateBit" SG_ 1317 CalDataLoadP1_UncalLoad_ISig_4 1;
BA_ "GenSigSendType" SG_ 1317 CalDataLoadP1_QF_ISig_4 1;
BA_ "GenSigCycleTime" SG_ 1317 CalDataLoadP1_QF_ISig_4 100;
BA_ "GenSigCycleTimeActive" SG_ 1317 CalDataLoadP1_QF_ISig_4 100;
BA_ "GenSigStartValue" SG_ 1317 CalDataLoadP1_QF_ISig_4 65535;
BA_ "GenSigMaxLatency" SG_ 1317 CalDataLoadP1_QF_ISig_4 1000;
BA_ "GenSigSendType" SG_ 1317 CalDataLoadP1_DayUTC_ISig_4 1;
BA_ "GenSigCycleTime" SG_ 1317 CalDataLoadP1_DayUTC_ISig_4 100;
BA_ "GenSigCycleTimeActive" SG_ 1317 CalDataLoadP1_DayUTC_ISig_4 100;
BA_ "GenSigStartValue" SG_ 1317 CalDataLoadP1_DayUTC_ISig_4 255;
BA_ "GenSigMaxLatency" SG_ 1317 CalDataLoadP1_DayUTC_ISig_4 1000;
BA_ "NeedsUpdateBit" SG_ 1317 CalDataLoadP1_DayUTC_ISig_4 1;
BA_ "GenSigSendType" SG_ 1317 CalDataLoadP1_sg_UB_ISig_4 7;
BA_ "GenSigSendType" SG_ 1317 CalDataLoadP1_MinutesUTC_ISig_4 1;
BA_ "GenSigCycleTime" SG_ 1317 CalDataLoadP1_MinutesUTC_ISig_4 100;
BA_ "GenSigCycleTimeActive" SG_ 1317 CalDataLoadP1_MinutesUTC_ISig_4 100;
BA_ "GenSigStartValue" SG_ 1317 CalDataLoadP1_MinutesUTC_ISig_4 255;
BA_ "GenSigMaxLatency" SG_ 1317 CalDataLoadP1_MinutesUTC_ISig_4 1000;
BA_ "NeedsUpdateBit" SG_ 1317 CalDataLoadP1_MinutesUTC_ISig_4 1;
BA_ "GenSigCycleTime" SG_ 1053 AlarmClockAlarms_stat_Mode 100;
BA_ "GenSigCycleTimeActive" SG_ 1053 AlarmClockAlarms_stat_Mode 100;
BA_ "GenSigMaxLatency" SG_ 1053 AlarmClockAlarms_stat_Mode 169;
BA_ "Platform_VMCU1_Sig" SG_ 1053 AlarmClockAlarms_stat_Mode 1;
BA_ "GenSigCycleTime" SG_ 1053 AlarmClockAlarms_stat_Type 100;
BA_ "GenSigCycleTimeActive" SG_ 1053 AlarmClockAlarms_stat_Type 100;
BA_ "GenSigStartValue" SG_ 1053 AlarmClockAlarms_stat_Type 7;
BA_ "GenSigMaxLatency" SG_ 1053 AlarmClockAlarms_stat_Type 169;
BA_ "Platform_VMCU1_Sig" SG_ 1053 AlarmClockAlarms_stat_Type 1;
BA_ "GenSigCycleTime" SG_ 1053 AlarmClockAlarms_stat_DaySet 100;
BA_ "GenSigCycleTimeActive" SG_ 1053 AlarmClockAlarms_stat_DaySet 100;
BA_ "GenSigMaxLatency" SG_ 1053 AlarmClockAlarms_stat_DaySet 169;
BA_ "Platform_VMCU1_Sig" SG_ 1053 AlarmClockAlarms_stat_DaySet 1;
BA_ "GenSigCycleTime" SG_ 1053 AlarmClockAlarms_stat_ID 100;
BA_ "GenSigCycleTimeActive" SG_ 1053 AlarmClockAlarms_stat_ID 100;
BA_ "GenSigStartValue" SG_ 1053 AlarmClockAlarms_stat_ID 127;
BA_ "GenSigMaxLatency" SG_ 1053 AlarmClockAlarms_stat_ID 169;
BA_ "Platform_VMCU1_Sig" SG_ 1053 AlarmClockAlarms_stat_ID 1;
BA_ "GenSigCycleTime" SG_ 1053 AlmClkCurAlarm_stat_SetMin 100;
BA_ "GenSigCycleTimeActive" SG_ 1053 AlmClkCurAlarm_stat_SetMin 100;
BA_ "GenSigStartValue" SG_ 1053 AlmClkCurAlarm_stat_SetMin 63;
BA_ "GenSigMaxLatency" SG_ 1053 AlmClkCurAlarm_stat_SetMin 169;
BA_ "Platform_VMCU1_Sig" SG_ 1053 AlmClkCurAlarm_stat_SetMin 1;
BA_ "GenSigCycleTime" SG_ 1053 AlarmClockAlarms_stat_Stat 100;
BA_ "GenSigCycleTimeActive" SG_ 1053 AlarmClockAlarms_stat_Stat 100;
BA_ "GenSigMaxLatency" SG_ 1053 AlarmClockAlarms_stat_Stat 169;
BA_ "Platform_VMCU1_Sig" SG_ 1053 AlarmClockAlarms_stat_Stat 1;
BA_ "GenSigCycleTime" SG_ 1053 AlmClkCurAlarm_stat_Stat 100;
BA_ "GenSigCycleTimeActive" SG_ 1053 AlmClkCurAlarm_stat_Stat 100;
BA_ "GenSigMaxLatency" SG_ 1053 AlmClkCurAlarm_stat_Stat 169;
BA_ "Platform_VMCU1_Sig" SG_ 1053 AlmClkCurAlarm_stat_Stat 1;
BA_ "GenSigCycleTime" SG_ 1053 AlmClkCurAlarm_stat_ID 100;
BA_ "GenSigCycleTimeActive" SG_ 1053 AlmClkCurAlarm_stat_ID 100;
BA_ "GenSigStartValue" SG_ 1053 AlmClkCurAlarm_stat_ID 127;
BA_ "GenSigMaxLatency" SG_ 1053 AlmClkCurAlarm_stat_ID 169;
BA_ "Platform_VMCU1_Sig" SG_ 1053 AlmClkCurAlarm_stat_ID 1;
BA_ "GenSigCycleTime" SG_ 1053 AlarmClockAlarms_stat_SetMin 100;
BA_ "GenSigCycleTimeActive" SG_ 1053 AlarmClockAlarms_stat_SetMin 100;
BA_ "GenSigStartValue" SG_ 1053 AlarmClockAlarms_stat_SetMin 63;
BA_ "GenSigMaxLatency" SG_ 1053 AlarmClockAlarms_stat_SetMin 169;
BA_ "Platform_VMCU1_Sig" SG_ 1053 AlarmClockAlarms_stat_SetMin 1;
BA_ "GenSigCycleTime" SG_ 1053 AlmClkCurAlarm_stat_Type 100;
BA_ "GenSigCycleTimeActive" SG_ 1053 AlmClkCurAlarm_stat_Type 100;
BA_ "GenSigStartValue" SG_ 1053 AlmClkCurAlarm_stat_Type 7;
BA_ "GenSigMaxLatency" SG_ 1053 AlmClkCurAlarm_stat_Type 169;
BA_ "Platform_VMCU1_Sig" SG_ 1053 AlmClkCurAlarm_stat_Type 1;
BA_ "GenSigCycleTime" SG_ 1053 AlarmClockAlarms_stat_SetHr 100;
BA_ "GenSigCycleTimeActive" SG_ 1053 AlarmClockAlarms_stat_SetHr 100;
BA_ "GenSigStartValue" SG_ 1053 AlarmClockAlarms_stat_SetHr 31;
BA_ "GenSigMaxLatency" SG_ 1053 AlarmClockAlarms_stat_SetHr 169;
BA_ "Platform_VMCU1_Sig" SG_ 1053 AlarmClockAlarms_stat_SetHr 1;
BA_ "GenSigCycleTime" SG_ 1053 AlmClkCurAlarm_stat_SetHr 100;
BA_ "GenSigCycleTimeActive" SG_ 1053 AlmClkCurAlarm_stat_SetHr 100;
BA_ "GenSigStartValue" SG_ 1053 AlmClkCurAlarm_stat_SetHr 31;
BA_ "GenSigMaxLatency" SG_ 1053 AlmClkCurAlarm_stat_SetHr 169;
BA_ "Platform_VMCU1_Sig" SG_ 1053 AlmClkCurAlarm_stat_SetHr 1;
BA_ "GenSigCycleTime" SG_ 1095 HVChrgnAlld 100;
BA_ "GenSigCycleTimeActive" SG_ 1095 HVChrgnAlld 100;
BA_ "GenSigStartValue" SG_ 1095 HVChrgnAlld 3;
BA_ "GenSigCycleTime" SG_ 1095 IdleAdjustFailedPreconStat 100;
BA_ "GenSigCycleTimeActive" SG_ 1095 IdleAdjustFailedPreconStat 100;
BA_ "GenSigStartValue" SG_ 1095 IdleAdjustFailedPreconStat 255;
BA_ "GenSigCycleTime" SG_ 1095 ParkHeaterTimerReleased_stat_ISi 100;
BA_ "GenSigCycleTimeActive" SG_ 1095 ParkHeaterTimerReleased_stat_ISi 100;
BA_ "GenSigStartValue" SG_ 1095 ParkHeaterTimerReleased_stat_ISi 3;
BA_ "GenSigMaxLatency" SG_ 1095 ParkHeaterTimerReleased_stat_ISi 150;
BA_ "Platform_VMCU1_Sig" SG_ 1095 ParkHeaterTimerReleased_stat_ISi 1;
BA_ "SystemSignalLongSymbol" SG_ 1095 ParkHeaterTimerReleased_stat_ISi "ParkHeaterTimerReleased_stat_ISig_4";
BA_ "GenSigCycleTime" SG_ 1095 PHTimerRqstAck_Hours_ISig_4 100;
BA_ "GenSigCycleTimeActive" SG_ 1095 PHTimerRqstAck_Hours_ISig_4 100;
BA_ "GenSigStartValue" SG_ 1095 PHTimerRqstAck_Hours_ISig_4 255;
BA_ "GenSigMaxLatency" SG_ 1095 PHTimerRqstAck_Hours_ISig_4 150;
BA_ "Platform_VMCU1_Sig" SG_ 1095 PHTimerRqstAck_Hours_ISig_4 1;
BA_ "GenSigCycleTime" SG_ 1095 PHTimerRqstAck_CurrentOp_ISig_4 100;
BA_ "GenSigCycleTimeActive" SG_ 1095 PHTimerRqstAck_CurrentOp_ISig_4 100;
BA_ "GenSigStartValue" SG_ 1095 PHTimerRqstAck_CurrentOp_ISig_4 3;
BA_ "GenSigMaxLatency" SG_ 1095 PHTimerRqstAck_CurrentOp_ISig_4 150;
BA_ "Platform_VMCU1_Sig" SG_ 1095 PHTimerRqstAck_CurrentOp_ISig_4 1;
BA_ "GenSigCycleTime" SG_ 1095 PHTimerRqstAck_DayOfWeekRq_ISig_ 100;
BA_ "GenSigCycleTimeActive" SG_ 1095 PHTimerRqstAck_DayOfWeekRq_ISig_ 100;
BA_ "GenSigStartValue" SG_ 1095 PHTimerRqstAck_DayOfWeekRq_ISig_ 15;
BA_ "GenSigMaxLatency" SG_ 1095 PHTimerRqstAck_DayOfWeekRq_ISig_ 150;
BA_ "Platform_VMCU1_Sig" SG_ 1095 PHTimerRqstAck_DayOfWeekRq_ISig_ 1;
BA_ "SystemSignalLongSymbol" SG_ 1095 PHTimerRqstAck_DayOfWeekRq_ISig_ "PHTimerRqstAck_DayOfWeekRq_ISig_4";
BA_ "GenSigCycleTime" SG_ 1095 PHTimerRqstAck_Minutes_ISig_4 100;
BA_ "GenSigCycleTimeActive" SG_ 1095 PHTimerRqstAck_Minutes_ISig_4 100;
BA_ "GenSigStartValue" SG_ 1095 PHTimerRqstAck_Minutes_ISig_4 255;
BA_ "GenSigMaxLatency" SG_ 1095 PHTimerRqstAck_Minutes_ISig_4 150;
BA_ "Platform_VMCU1_Sig" SG_ 1095 PHTimerRqstAck_Minutes_ISig_4 1;
BA_ "GenSigCycleTime" SG_ 1095 AlarmClockNotification_Stat_ISig 100;
BA_ "GenSigCycleTimeActive" SG_ 1095 AlarmClockNotification_Stat_ISig 100;
BA_ "GenSigMaxLatency" SG_ 1095 AlarmClockNotification_Stat_ISig 150;
BA_ "Platform_VMCU1_Sig" SG_ 1095 AlarmClockNotification_Stat_ISig 1;
BA_ "SystemSignalLongSymbol" SG_ 1095 AlarmClockNotification_Stat_ISig "AlarmClockNotification_Stat_ISig_4";
BA_ "GenSigCycleTime" SG_ 1095 AlarmClockNotification_Type_ISig 100;
BA_ "GenSigCycleTimeActive" SG_ 1095 AlarmClockNotification_Type_ISig 100;
BA_ "GenSigStartValue" SG_ 1095 AlarmClockNotification_Type_ISig 7;
BA_ "GenSigMaxLatency" SG_ 1095 AlarmClockNotification_Type_ISig 150;
BA_ "Platform_VMCU1_Sig" SG_ 1095 AlarmClockNotification_Type_ISig 1;
BA_ "SystemSignalLongSymbol" SG_ 1095 AlarmClockNotification_Type_ISig "AlarmClockNotification_Type_ISig_4";
BA_ "GenSigCycleTime" SG_ 1095 AlarmClockNotification_ID_ISig_4 100;
BA_ "GenSigCycleTimeActive" SG_ 1095 AlarmClockNotification_ID_ISig_4 100;
BA_ "GenSigStartValue" SG_ 1095 AlarmClockNotification_ID_ISig_4 127;
BA_ "GenSigMaxLatency" SG_ 1095 AlarmClockNotification_ID_ISig_4 150;
BA_ "Platform_VMCU1_Sig" SG_ 1095 AlarmClockNotification_ID_ISig_4 1;
BA_ "GenSigCycleTime" SG_ 1316 LoadIndCalWarning_Movement_ISig_ 100;
BA_ "GenSigCycleTimeActive" SG_ 1316 LoadIndCalWarning_Movement_ISig_ 100;
BA_ "GenSigStartValue" SG_ 1316 LoadIndCalWarning_Movement_ISig_ 3;
BA_ "SystemSignalLongSymbol" SG_ 1316 LoadIndCalWarning_Movement_ISig_ "LoadIndCalWarning_Movement_ISig_4";
BA_ "GenSigCycleTime" SG_ 1316 LoadIndCalWarning_LiftedAxle_ISi 100;
BA_ "GenSigCycleTimeActive" SG_ 1316 LoadIndCalWarning_LiftedAxle_ISi 100;
BA_ "GenSigStartValue" SG_ 1316 LoadIndCalWarning_LiftedAxle_ISi 3;
BA_ "SystemSignalLongSymbol" SG_ 1316 LoadIndCalWarning_LiftedAxle_ISi "LoadIndCalWarning_LiftedAxle_ISig_4";
BA_ "GenSigCycleTime" SG_ 1316 LoadIndCalWarning_LowSupplyPress 100;
BA_ "GenSigCycleTimeActive" SG_ 1316 LoadIndCalWarning_LowSupplyPress 100;
BA_ "GenSigStartValue" SG_ 1316 LoadIndCalWarning_LowSupplyPress 3;
BA_ "SystemSignalLongSymbol" SG_ 1316 LoadIndCalWarning_LowSupplyPress "LoadIndCalWarning_LowSupplyPress_ISig_4";
BA_ "GenSigCycleTime" SG_ 1316 LoadIndCalWarning_PBrakeApplied_ 100;
BA_ "GenSigCycleTimeActive" SG_ 1316 LoadIndCalWarning_PBrakeApplied_ 100;
BA_ "GenSigStartValue" SG_ 1316 LoadIndCalWarning_PBrakeApplied_ 3;
BA_ "SystemSignalLongSymbol" SG_ 1316 LoadIndCalWarning_PBrakeApplied_ "LoadIndCalWarning_PBrakeApplied_ISig_4";
BA_ "GenSigCycleTime" SG_ 1316 LoadIndCalWarning_SBrakesApplied 100;
BA_ "GenSigCycleTimeActive" SG_ 1316 LoadIndCalWarning_SBrakesApplied 100;
BA_ "GenSigStartValue" SG_ 1316 LoadIndCalWarning_SBrakesApplied 3;
BA_ "SystemSignalLongSymbol" SG_ 1316 LoadIndCalWarning_SBrakesApplied "LoadIndCalWarning_SBrakesApplied_ISig_4";
BA_ "GenSigCycleTime" SG_ 1316 LoadIndCalWarning_HighInclin_ISi 100;
BA_ "GenSigCycleTimeActive" SG_ 1316 LoadIndCalWarning_HighInclin_ISi 100;
BA_ "GenSigStartValue" SG_ 1316 LoadIndCalWarning_HighInclin_ISi 3;
BA_ "SystemSignalLongSymbol" SG_ 1316 LoadIndCalWarning_HighInclin_ISi "LoadIndCalWarning_HighInclin_ISig_4";
BA_ "GenSigCycleTime" SG_ 1316 LoadTrailer3_ISig_4 100;
BA_ "GenSigCycleTimeActive" SG_ 1316 LoadTrailer3_ISig_4 100;
BA_ "GenSigStartValue" SG_ 1316 LoadTrailer3_ISig_4 65535;
BA_ "GenSigCycleTime" SG_ 1316 LoadIndCalWarning_GearNotNeutral 100;
BA_ "GenSigCycleTimeActive" SG_ 1316 LoadIndCalWarning_GearNotNeutral 100;
BA_ "GenSigStartValue" SG_ 1316 LoadIndCalWarning_GearNotNeutral 3;
BA_ "SystemSignalLongSymbol" SG_ 1316 LoadIndCalWarning_GearNotNeutral "LoadIndCalWarning_GearNotNeutral_ISig_4";
BA_ "GenSigCycleTime" SG_ 1315 LoadTrailer2Back_ISig_4 100;
BA_ "GenSigCycleTimeActive" SG_ 1315 LoadTrailer2Back_ISig_4 100;
BA_ "GenSigStartValue" SG_ 1315 LoadTrailer2Back_ISig_4 65535;
BA_ "GenSigCycleTime" SG_ 1315 LoadTrailer3Front_ISig_4 100;
BA_ "GenSigCycleTimeActive" SG_ 1315 LoadTrailer3Front_ISig_4 100;
BA_ "GenSigStartValue" SG_ 1315 LoadTrailer3Front_ISig_4 65535;
BA_ "GenSigCycleTime" SG_ 1315 LoadTrailer5Back_ISig_4 100;
BA_ "GenSigCycleTimeActive" SG_ 1315 LoadTrailer5Back_ISig_4 100;
BA_ "GenSigStartValue" SG_ 1315 LoadTrailer5Back_ISig_4 65535;
BA_ "GenSigCycleTime" SG_ 1315 LoadTrailer4Front_ISig_4 100;
BA_ "GenSigCycleTimeActive" SG_ 1315 LoadTrailer4Front_ISig_4 100;
BA_ "GenSigStartValue" SG_ 1315 LoadTrailer4Front_ISig_4 65535;
BA_ "GenSigCycleTime" SG_ 1314 LoadTrailer1Front_ISig_4 100;
BA_ "GenSigCycleTimeActive" SG_ 1314 LoadTrailer1Front_ISig_4 100;
BA_ "GenSigStartValue" SG_ 1314 LoadTrailer1Front_ISig_4 65535;
BA_ "GenSigCycleTime" SG_ 1314 LoadTruck_ISig_4 100;
BA_ "GenSigCycleTimeActive" SG_ 1314 LoadTruck_ISig_4 100;
BA_ "GenSigStartValue" SG_ 1314 LoadTruck_ISig_4 65535;
BA_ "GenSigCycleTime" SG_ 1314 LoadTrailer1_ISig_4 100;
BA_ "GenSigCycleTimeActive" SG_ 1314 LoadTrailer1_ISig_4 100;
BA_ "GenSigStartValue" SG_ 1314 LoadTrailer1_ISig_4 65535;
BA_ "GenSigCycleTime" SG_ 1314 LoadTrailer5Front_ISig_4 100;
BA_ "GenSigCycleTimeActive" SG_ 1314 LoadTrailer5Front_ISig_4 100;
BA_ "GenSigStartValue" SG_ 1314 LoadTrailer5Front_ISig_4 65535;
BA_ "GenSigCycleTime" SG_ 1313 LoadTrailer4_ISig_4 100;
BA_ "GenSigCycleTimeActive" SG_ 1313 LoadTrailer4_ISig_4 100;
BA_ "GenSigStartValue" SG_ 1313 LoadTrailer4_ISig_4 65535;
BA_ "GenSigCycleTime" SG_ 1313 LoadTrailer3Back_ISig_4 100;
BA_ "GenSigCycleTimeActive" SG_ 1313 LoadTrailer3Back_ISig_4 100;
BA_ "GenSigStartValue" SG_ 1313 LoadTrailer3Back_ISig_4 65535;
BA_ "GenSigCycleTime" SG_ 1313 LoadTruckRear 100;
BA_ "GenSigCycleTimeActive" SG_ 1313 LoadTruckRear 100;
BA_ "GenSigStartValue" SG_ 1313 LoadTruckRear 65535;
BA_ "GenSigCycleTime" SG_ 1313 LoadTrailer2_ISig_4 100;
BA_ "GenSigCycleTimeActive" SG_ 1313 LoadTrailer2_ISig_4 100;
BA_ "GenSigStartValue" SG_ 1313 LoadTrailer2_ISig_4 65535;
BA_ "GenSigCycleTime" SG_ 1312 CalLoadTrailer2Axle3_ISig_4 100;
BA_ "GenSigCycleTimeActive" SG_ 1312 CalLoadTrailer2Axle3_ISig_4 100;
BA_ "GenSigStartValue" SG_ 1312 CalLoadTrailer2Axle3_ISig_4 65535;
BA_ "GenSigCycleTime" SG_ 1312 CalLoadTrailer3Axle2_ISig_4 100;
BA_ "GenSigCycleTimeActive" SG_ 1312 CalLoadTrailer3Axle2_ISig_4 100;
BA_ "GenSigStartValue" SG_ 1312 CalLoadTrailer3Axle2_ISig_4 65535;
BA_ "GenSigCycleTime" SG_ 1312 CalLoadTrailer3Axle6_ISig_4 100;
BA_ "GenSigCycleTimeActive" SG_ 1312 CalLoadTrailer3Axle6_ISig_4 100;
BA_ "GenSigStartValue" SG_ 1312 CalLoadTrailer3Axle6_ISig_4 65535;
BA_ "GenSigCycleTime" SG_ 1305 LoadVehCombination_ISig_4 100;
BA_ "GenSigCycleTimeActive" SG_ 1305 LoadVehCombination_ISig_4 100;
BA_ "GenSigStartValue" SG_ 1305 LoadVehCombination_ISig_4 65535;
BA_ "GenSigCycleTime" SG_ 1305 LoadTruckFront 100;
BA_ "GenSigCycleTimeActive" SG_ 1305 LoadTruckFront 100;
BA_ "GenSigStartValue" SG_ 1305 LoadTruckFront 65535;
BA_ "GenSigCycleTime" SG_ 1305 LoadVehCombCargoRel_ISig_4 100;
BA_ "GenSigCycleTimeActive" SG_ 1305 LoadVehCombCargoRel_ISig_4 100;
BA_ "GenSigStartValue" SG_ 1305 LoadVehCombCargoRel_ISig_4 65535;
BA_ "GenSigCycleTime" SG_ 1305 LoadTrailer1Back_ISig_4 100;
BA_ "GenSigCycleTimeActive" SG_ 1305 LoadTrailer1Back_ISig_4 100;
BA_ "GenSigStartValue" SG_ 1305 LoadTrailer1Back_ISig_4 65535;
BA_ "GenSigCycleTime" SG_ 1304 CalLoadTrailer3Axle4_ISig_4 100;
BA_ "GenSigCycleTimeActive" SG_ 1304 CalLoadTrailer3Axle4_ISig_4 100;
BA_ "GenSigStartValue" SG_ 1304 CalLoadTrailer3Axle4_ISig_4 65535;
BA_ "GenSigCycleTime" SG_ 1304 CalLoadTrailer2Axle2_ISig_4 100;
BA_ "GenSigCycleTimeActive" SG_ 1304 CalLoadTrailer2Axle2_ISig_4 100;
BA_ "GenSigStartValue" SG_ 1304 CalLoadTrailer2Axle2_ISig_4 65535;
BA_ "GenSigCycleTime" SG_ 1304 CalLoadTrailer1Axle6_ISig_4 100;
BA_ "GenSigCycleTimeActive" SG_ 1304 CalLoadTrailer1Axle6_ISig_4 100;
BA_ "GenSigStartValue" SG_ 1304 CalLoadTrailer1Axle6_ISig_4 65535;
BA_ "GenSigCycleTime" SG_ 1304 CalLoadTrailer5Axle6_ISig_4 100;
BA_ "GenSigCycleTimeActive" SG_ 1304 CalLoadTrailer5Axle6_ISig_4 100;
BA_ "GenSigStartValue" SG_ 1304 CalLoadTrailer5Axle6_ISig_4 65535;
BA_REL_ "GenSigFirstTimeoutTime" BU_SG_REL_ BBM SG_ 826 StartupProhibitStatus_ISig_4 3000;
BA_REL_ "GenSigTimeoutTime" BU_SG_REL_ BBM SG_ 826 StartupProhibitStatus_ISig_4 300;
BA_REL_ "GenSigFirstTimeoutTime" BU_SG_REL_ IC3 SG_ 826 StartupProhibitStatus_ISig_4 3000;
BA_REL_ "GenSigTimeoutTime" BU_SG_REL_ IC3 SG_ 826 StartupProhibitStatus_ISig_4 300;
BA_REL_ "GenSigFirstTimeoutTime" BU_SG_REL_ IC3 SG_ 826 RampLevelStatus_ISig_4 3000;
BA_REL_ "GenSigTimeoutTime" BU_SG_REL_ IC3 SG_ 826 RampLevelStatus_ISig_4 300;
BA_REL_ "GenSigFirstTimeoutTime" BU_SG_REL_ CIOM SG_ 826 RampLevelStatus_ISig_4 3000;
BA_REL_ "GenSigTimeoutTime" BU_SG_REL_ CIOM SG_ 826 RampLevelStatus_ISig_4 300;
BA_REL_ "GenSigFirstTimeoutTime" BU_SG_REL_ BBM SG_ 826 KneelingInformation_ISig_4 3000;
BA_REL_ "GenSigTimeoutTime" BU_SG_REL_ BBM SG_ 826 KneelingInformation_ISig_4 300;
BA_REL_ "GenSigFirstTimeoutTime" BU_SG_REL_ IC3 SG_ 826 KneelingInformation_ISig_4 3000;
BA_REL_ "GenSigTimeoutTime" BU_SG_REL_ IC3 SG_ 826 KneelingInformation_ISig_4 300;
BA_REL_ "GenSigFirstTimeoutTime" BU_SG_REL_ CIOM SG_ 826 KneelingInformation_ISig_4 3000;
BA_REL_ "GenSigTimeoutTime" BU_SG_REL_ CIOM SG_ 826 KneelingInformation_ISig_4 300;
BA_REL_ "GenSigFirstTimeoutTime" BU_SG_REL_ TECU SG_ 826 FrontAxleInBumperRange_ISig_4 3000;
BA_REL_ "GenSigTimeoutTime" BU_SG_REL_ TECU SG_ 826 FrontAxleInBumperRange_ISig_4 500;
BA_REL_ "GenSigFirstTimeoutTime" BU_SG_REL_ IC3 SG_ 826 FerryFunctionStatus_ISig_4 3000;
BA_REL_ "GenSigTimeoutTime" BU_SG_REL_ IC3 SG_ 826 FerryFunctionStatus_ISig_4 300;
BA_REL_ "GenSigFirstTimeoutTime" BU_SG_REL_ CIOM SG_ 826 FerryFunctionStatus_ISig_4 3000;
BA_REL_ "GenSigTimeoutTime" BU_SG_REL_ CIOM SG_ 826 FerryFunctionStatus_ISig_4 300;
BA_REL_ "GenSigFirstTimeoutTime" BU_SG_REL_ TECU SG_ 826 EngPtoConsumesTorque 3000;
BA_REL_ "GenSigTimeoutTime" BU_SG_REL_ TECU SG_ 826 EngPtoConsumesTorque 500;
BA_REL_ "GenSigFirstTimeoutTime" BU_SG_REL_ BBM SG_ 826 LiftingControlModeRearAxle_ISig_ 3000;
BA_REL_ "GenSigTimeoutTime" BU_SG_REL_ BBM SG_ 826 LiftingControlModeRearAxle_ISig_ 300;
BA_REL_ "GenSigFirstTimeoutTime" BU_SG_REL_ BBM SG_ 826 KneelingStatusHMI_ISig_4 3000;
BA_REL_ "GenSigTimeoutTime" BU_SG_REL_ BBM SG_ 826 KneelingStatusHMI_ISig_4 300;
BA_REL_ "GenSigFirstTimeoutTime" BU_SG_REL_ CIOM SG_ 826 KneelingStatusHMI_ISig_4 3000;
BA_REL_ "GenSigTimeoutTime" BU_SG_REL_ CIOM SG_ 826 KneelingStatusHMI_ISig_4 300;
BA_REL_ "GenSigFirstTimeoutTime" BU_SG_REL_ BBM SG_ 826 SWEngineStop_rqst_ISig_4 3000;
BA_REL_ "GenSigTimeoutTime" BU_SG_REL_ BBM SG_ 826 SWEngineStop_rqst_ISig_4 300;
BA_REL_ "GenSigFirstTimeoutTime" BU_SG_REL_ CIOM SG_ 826 FrontEndPositionStatus_ISig_4 3000;
BA_REL_ "GenSigTimeoutTime" BU_SG_REL_ CIOM SG_ 826 FrontEndPositionStatus_ISig_4 300;
BA_REL_ "GenSigFirstTimeoutTime" BU_SG_REL_ BBM SG_ 826 LiftingControlModeFrontAxle_ISig 3000;
BA_REL_ "GenSigTimeoutTime" BU_SG_REL_ BBM SG_ 826 LiftingControlModeFrontAxle_ISig 300;
BA_REL_ "GenSigFirstTimeoutTime" BU_SG_REL_ IC3 SG_ 826 UnevenLoadWarning_ISig_4 3000;
BA_REL_ "GenSigTimeoutTime" BU_SG_REL_ IC3 SG_ 826 UnevenLoadWarning_ISig_4 300;
BA_REL_ "GenSigFirstTimeoutTime" BU_SG_REL_ IC3 SG_ 826 RampHeightOutsideTargetRange_ISi 3000;
BA_REL_ "GenSigTimeoutTime" BU_SG_REL_ IC3 SG_ 826 RampHeightOutsideTargetRange_ISi 300;
BA_REL_ "GenSigFirstTimeoutTime" BU_SG_REL_ CIOM SG_ 826 RampHeightOutsideTargetRange_ISi 3000;
BA_REL_ "GenSigTimeoutTime" BU_SG_REL_ CIOM SG_ 826 RampHeightOutsideTargetRange_ISi 300;
BA_REL_ "GenSigFirstTimeoutTime" BU_SG_REL_ IC3 SG_ 826 DriveLevelPosUserInteraction_ISi 3000;
BA_REL_ "GenSigTimeoutTime" BU_SG_REL_ IC3 SG_ 826 DriveLevelPosUserInteraction_ISi 300;
BA_REL_ "GenSigFirstTimeoutTime" BU_SG_REL_ TECU SG_ 826 RearEndPositionStatus_ISig_4 3000;
BA_REL_ "GenSigTimeoutTime" BU_SG_REL_ TECU SG_ 826 RearEndPositionStatus_ISig_4 500;
BA_REL_ "GenSigFirstTimeoutTime" BU_SG_REL_ CIOM SG_ 826 RearEndPositionStatus_ISig_4 3000;
BA_REL_ "GenSigTimeoutTime" BU_SG_REL_ CIOM SG_ 826 RearEndPositionStatus_ISig_4 300;
BA_REL_ "GenSigFirstTimeoutTime" BU_SG_REL_ IC3 SG_ 826 ProhibitControlStatus_ISig_4 3000;
BA_REL_ "GenSigTimeoutTime" BU_SG_REL_ IC3 SG_ 826 ProhibitControlStatus_ISig_4 300;
BA_REL_ "GenSigFirstTimeoutTime" BU_SG_REL_ BBM SG_ 826 ProhibitControlStatus_ISig_4 3000;
BA_REL_ "GenSigTimeoutTime" BU_SG_REL_ BBM SG_ 826 ProhibitControlStatus_ISig_4 300;
BA_REL_ "GenSigFirstTimeoutTime" BU_SG_REL_ CIOM SG_ 826 ChangeKneelACK_ISig_4 3000;
BA_REL_ "GenSigTimeoutTime" BU_SG_REL_ CIOM SG_ 826 ChangeKneelACK_ISig_4 300;
BA_REL_ "GenSigFirstTimeoutTime" BU_SG_REL_ IC3 SG_ 826 ParkBrakeApplicationMode2 3000;
BA_REL_ "GenSigTimeoutTime" BU_SG_REL_ IC3 SG_ 826 ParkBrakeApplicationMode2 300;
BA_REL_ "GenSigFirstTimeoutTime" BU_SG_REL_ CIOM SG_ 826 RollEndPositionStatus_ISig_4 3000;
BA_REL_ "GenSigTimeoutTime" BU_SG_REL_ CIOM SG_ 826 RollEndPositionStatus_ISig_4 300;
BA_REL_ "GenSigFirstTimeoutTime" BU_SG_REL_ IC3 SG_ 826 ParkBrakeReleaseMode2_ISig_4 3000;
BA_REL_ "GenSigTimeoutTime" BU_SG_REL_ IC3 SG_ 826 ParkBrakeReleaseMode2_ISig_4 300;
BA_REL_ "GenSigFirstTimeoutTime" BU_SG_REL_ CIOM SG_ 826 ECSStandbyAllowed_ISig_4 3000;
BA_REL_ "GenSigTimeoutTime" BU_SG_REL_ CIOM SG_ 826 ECSStandbyAllowed_ISig_4 300;
BA_REL_ "GenSigFirstTimeoutTime" BU_SG_REL_ TECU SG_ 826 RearAxleInBumperRange_ISig_4 3000;
BA_REL_ "GenSigTimeoutTime" BU_SG_REL_ TECU SG_ 826 RearAxleInBumperRange_ISig_4 500;
BA_REL_ "GenSigFirstTimeoutTime" BU_SG_REL_ BBM SG_ 1029 RelativeLevelRearAxleRight_ISig_ 3000;
BA_REL_ "GenSigTimeoutTime" BU_SG_REL_ BBM SG_ 1029 RelativeLevelRearAxleRight_ISig_ 600;
BA_REL_ "GenSigFirstTimeoutTime" BU_SG_REL_ BBM SG_ 1029 RelativeLevelFrontAxleRight_ISig 3000;
BA_REL_ "GenSigTimeoutTime" BU_SG_REL_ BBM SG_ 1029 RelativeLevelFrontAxleRight_ISig 600;
BA_REL_ "GenSigFirstTimeoutTime" BU_SG_REL_ BBM SG_ 1029 RelativeLevelFrontAxleLeft_ISig_ 3000;
BA_REL_ "GenSigTimeoutTime" BU_SG_REL_ BBM SG_ 1029 RelativeLevelFrontAxleLeft_ISig_ 600;
BA_REL_ "GenSigFirstTimeoutTime" BU_SG_REL_ BBM SG_ 1029 RelativeLevelRearAxleLeft_ISig_4 3000;
BA_REL_ "GenSigTimeoutTime" BU_SG_REL_ BBM SG_ 1029 RelativeLevelRearAxleLeft_ISig_4 600;
BA_REL_ "GenSigFirstTimeoutTime" BU_SG_REL_ DACU SG_ 1207 RelativeLevelFrontAxleLeftRaw_IS 3000;
BA_REL_ "GenSigTimeoutTime" BU_SG_REL_ DACU SG_ 1207 RelativeLevelFrontAxleLeftRaw_IS 600;
BA_REL_ "GenSigFirstTimeoutTime" BU_SG_REL_ DACU SG_ 1207 RelativeLevelFrontAxleRightRaw_I 3000;
BA_REL_ "GenSigTimeoutTime" BU_SG_REL_ DACU SG_ 1207 RelativeLevelFrontAxleRightRaw_I 600;
BA_REL_ "GenSigFirstTimeoutTime" BU_SG_REL_ EMS SG_ 1273 OBDDtcVMCU_SPN2_B2 12000;
BA_REL_ "GenSigTimeoutTime" BU_SG_REL_ EMS SG_ 1273 OBDDtcVMCU_SPN2_B2 3000;
BA_REL_ "GenSigFirstTimeoutTime" BU_SG_REL_ EMS SG_ 1273 OBDDtcVMCU_SPN1_3msb 12000;
BA_REL_ "GenSigTimeoutTime" BU_SG_REL_ EMS SG_ 1273 OBDDtcVMCU_SPN1_3msb 3000;
BA_REL_ "GenSigFirstTimeoutTime" BU_SG_REL_ EMS SG_ 1273 OBDDtcVMCU_SPN2_3msb 12000;
BA_REL_ "GenSigTimeoutTime" BU_SG_REL_ EMS SG_ 1273 OBDDtcVMCU_SPN2_3msb 3000;
BA_REL_ "GenSigFirstTimeoutTime" BU_SG_REL_ EMS SG_ 1273 OBDDtcVMCU_EvalResult2 12000;
BA_REL_ "GenSigTimeoutTime" BU_SG_REL_ EMS SG_ 1273 OBDDtcVMCU_EvalResult2 3000;
BA_REL_ "GenSigFirstTimeoutTime" BU_SG_REL_ EMS SG_ 1273 OBDDtcVMCU_SPN1_B1 12000;
BA_REL_ "GenSigTimeoutTime" BU_SG_REL_ EMS SG_ 1273 OBDDtcVMCU_SPN1_B1 3000;
BA_REL_ "GenSigFirstTimeoutTime" BU_SG_REL_ EMS SG_ 1273 OBDDtcVMCU_EvalStatus1 12000;
BA_REL_ "GenSigTimeoutTime" BU_SG_REL_ EMS SG_ 1273 OBDDtcVMCU_EvalStatus1 3000;
BA_REL_ "GenSigFirstTimeoutTime" BU_SG_REL_ EMS SG_ 1273 OBDDtcVMCU_DrivingCycle2 12000;
BA_REL_ "GenSigTimeoutTime" BU_SG_REL_ EMS SG_ 1273 OBDDtcVMCU_DrivingCycle2 3000;
BA_REL_ "GenSigFirstTimeoutTime" BU_SG_REL_ EMS SG_ 1273 OBDDtcVMCU_SPN2_B1 12000;
BA_REL_ "GenSigTimeoutTime" BU_SG_REL_ EMS SG_ 1273 OBDDtcVMCU_SPN2_B1 3000;
BA_REL_ "GenSigFirstTimeoutTime" BU_SG_REL_ EMS SG_ 1273 OBDDtcVMCU_DrivingCycle1 12000;
BA_REL_ "GenSigTimeoutTime" BU_SG_REL_ EMS SG_ 1273 OBDDtcVMCU_DrivingCycle1 3000;
BA_REL_ "GenSigFirstTimeoutTime" BU_SG_REL_ EMS SG_ 1273 OBDDtcVMCU_SPN1_B2 12000;
BA_REL_ "GenSigTimeoutTime" BU_SG_REL_ EMS SG_ 1273 OBDDtcVMCU_SPN1_B2 3000;
BA_REL_ "GenSigFirstTimeoutTime" BU_SG_REL_ EMS SG_ 1273 OBDDtcVMCU_FMI1 12000;
BA_REL_ "GenSigTimeoutTime" BU_SG_REL_ EMS SG_ 1273 OBDDtcVMCU_FMI1 3000;
BA_REL_ "GenSigFirstTimeoutTime" BU_SG_REL_ EMS SG_ 1273 OBDDtcVMCU_EvalStatus2 12000;
BA_REL_ "GenSigTimeoutTime" BU_SG_REL_ EMS SG_ 1273 OBDDtcVMCU_EvalStatus2 3000;
BA_REL_ "GenSigFirstTimeoutTime" BU_SG_REL_ EMS SG_ 1273 OBDDtcVMCU_FMI2 12000;
BA_REL_ "GenSigTimeoutTime" BU_SG_REL_ EMS SG_ 1273 OBDDtcVMCU_FMI2 3000;
BA_REL_ "GenSigFirstTimeoutTime" BU_SG_REL_ EMS SG_ 1273 OBDDtcVMCU_EvalResult1 12000;
BA_REL_ "GenSigTimeoutTime" BU_SG_REL_ EMS SG_ 1273 OBDDtcVMCU_EvalResult1 3000;
BA_REL_ "GenSigFirstTimeoutTime" BU_SG_REL_ TECU SG_ 567 DriveModeSwitchStat_Rqst 3000;
BA_REL_ "GenSigTimeoutTime" BU_SG_REL_ TECU SG_ 567 DriveModeSwitchStat_Rqst 120;
BA_REL_ "GenSigFirstTimeoutTime" BU_SG_REL_ TECU SG_ 567 UpDownShiftRqst_CRC 3000;
BA_REL_ "GenSigTimeoutTime" BU_SG_REL_ TECU SG_ 567 UpDownShiftRqst_CRC 120;
BA_REL_ "GenSigFirstTimeoutTime" BU_SG_REL_ TECU SG_ 567 GearLeverPosition2_SqC 3000;
BA_REL_ "GenSigTimeoutTime" BU_SG_REL_ TECU SG_ 567 GearLeverPosition2_SqC 120;
BA_REL_ "GenSigFirstTimeoutTime" BU_SG_REL_ IC3 SG_ 567 GearLeverPosition2_SqC 3000;
BA_REL_ "GenSigTimeoutTime" BU_SG_REL_ IC3 SG_ 567 GearLeverPosition2_SqC 120;
BA_REL_ "GenSigFirstTimeoutTime" BU_SG_REL_ IC3 SG_ 567 GearLeverPosition2_Rqst 3000;
BA_REL_ "GenSigTimeoutTime" BU_SG_REL_ IC3 SG_ 567 GearLeverPosition2_Rqst 120;
BA_REL_ "GenSigFirstTimeoutTime" BU_SG_REL_ TECU SG_ 567 GearLeverPosition2_Rqst 3000;
BA_REL_ "GenSigTimeoutTime" BU_SG_REL_ TECU SG_ 567 GearLeverPosition2_Rqst 120;
BA_REL_ "GenSigFirstTimeoutTime" BU_SG_REL_ TECU SG_ 567 DriveModeSwitchStat_CRC 3000;
BA_REL_ "GenSigTimeoutTime" BU_SG_REL_ TECU SG_ 567 DriveModeSwitchStat_CRC 120;
BA_REL_ "GenSigFirstTimeoutTime" BU_SG_REL_ TECU SG_ 567 DriveModeSwitchStat_SqC 3000;
BA_REL_ "GenSigTimeoutTime" BU_SG_REL_ TECU SG_ 567 DriveModeSwitchStat_SqC 120;
BA_REL_ "GenSigFirstTimeoutTime" BU_SG_REL_ TECU SG_ 567 UpDownShiftRqst_SqC 3000;
BA_REL_ "GenSigTimeoutTime" BU_SG_REL_ TECU SG_ 567 UpDownShiftRqst_SqC 120;
BA_REL_ "GenSigFirstTimeoutTime" BU_SG_REL_ TECU SG_ 567 UpDownShiftRqst_Rqst 3000;
BA_REL_ "GenSigTimeoutTime" BU_SG_REL_ TECU SG_ 567 UpDownShiftRqst_Rqst 120;
BA_REL_ "GenSigFirstTimeoutTime" BU_SG_REL_ TECU SG_ 567 GearLeverPosition2_CRC 3000;
BA_REL_ "GenSigTimeoutTime" BU_SG_REL_ TECU SG_ 567 GearLeverPosition2_CRC 120;
BA_REL_ "GenSigFirstTimeoutTime" BU_SG_REL_ IC3 SG_ 567 GearLeverPosition2_CRC 3000;
BA_REL_ "GenSigTimeoutTime" BU_SG_REL_ IC3 SG_ 567 GearLeverPosition2_CRC 120;
BA_REL_ "GenSigFirstTimeoutTime" BU_SG_REL_ IC3 SG_ 1169 ConnectedTrailer1_Calibrated 12000;
BA_REL_ "GenSigTimeoutTime" BU_SG_REL_ IC3 SG_ 1169 ConnectedTrailer1_Calibrated 3000;
BA_REL_ "GenSigFirstTimeoutTime" BU_SG_REL_ IC3 SG_ 1169 ConnectedTrailer3_Calibrated 12000;
BA_REL_ "GenSigTimeoutTime" BU_SG_REL_ IC3 SG_ 1169 ConnectedTrailer3_Calibrated 3000;
BA_REL_ "GenSigFirstTimeoutTime" BU_SG_REL_ IC3 SG_ 1169 ConnectedTrailer4_Calibrated 12000;
BA_REL_ "GenSigTimeoutTime" BU_SG_REL_ IC3 SG_ 1169 ConnectedTrailer4_Calibrated 3000;
BA_REL_ "GenSigFirstTimeoutTime" BU_SG_REL_ IC3 SG_ 1169 ConnectedTrailer2_MemPosition 12000;
BA_REL_ "GenSigTimeoutTime" BU_SG_REL_ IC3 SG_ 1169 ConnectedTrailer2_MemPosition 3000;
BA_REL_ "GenSigFirstTimeoutTime" BU_SG_REL_ IC3 SG_ 1169 ConnectedTrailer1_MemPosition 12000;
BA_REL_ "GenSigTimeoutTime" BU_SG_REL_ IC3 SG_ 1169 ConnectedTrailer1_MemPosition 3000;
BA_REL_ "GenSigFirstTimeoutTime" BU_SG_REL_ IC3 SG_ 1169 ConnectedTrailer5_Calibrated 12000;
BA_REL_ "GenSigTimeoutTime" BU_SG_REL_ IC3 SG_ 1169 ConnectedTrailer5_Calibrated 3000;
BA_REL_ "GenSigFirstTimeoutTime" BU_SG_REL_ IC3 SG_ 1169 ConnectedTrailer5_MemPosition 12000;
BA_REL_ "GenSigTimeoutTime" BU_SG_REL_ IC3 SG_ 1169 ConnectedTrailer5_MemPosition 3000;
BA_REL_ "GenSigFirstTimeoutTime" BU_SG_REL_ IC3 SG_ 1169 ConnectedTrailer3_MemPosition 12000;
BA_REL_ "GenSigTimeoutTime" BU_SG_REL_ IC3 SG_ 1169 ConnectedTrailer3_MemPosition 3000;
BA_REL_ "GenSigFirstTimeoutTime" BU_SG_REL_ IC3 SG_ 1169 ConnectedTrailer2_Calibrated 12000;
BA_REL_ "GenSigTimeoutTime" BU_SG_REL_ IC3 SG_ 1169 ConnectedTrailer2_Calibrated 3000;
BA_REL_ "GenSigFirstTimeoutTime" BU_SG_REL_ IC3 SG_ 1169 ConnectedTrailer4_MemPosition 12000;
BA_REL_ "GenSigTimeoutTime" BU_SG_REL_ IC3 SG_ 1169 ConnectedTrailer4_MemPosition 3000;
BA_REL_ "GenSigFirstTimeoutTime" BU_SG_REL_ IC3 SG_ 1185 UncalLoadTrkFAxle1_ISig_4 12000;
BA_REL_ "GenSigTimeoutTime" BU_SG_REL_ IC3 SG_ 1185 UncalLoadTrkFAxle1_ISig_4 3000;
BA_REL_ "GenSigFirstTimeoutTime" BU_SG_REL_ IC3 SG_ 1185 UncalLoadTrkRAxle2_ISig_4 12000;
BA_REL_ "GenSigTimeoutTime" BU_SG_REL_ IC3 SG_ 1185 UncalLoadTrkRAxle2_ISig_4 3000;
BA_REL_ "GenSigFirstTimeoutTime" BU_SG_REL_ IC3 SG_ 1185 UncalLoadTrkFAxle2_ISig_4 12000;
BA_REL_ "GenSigTimeoutTime" BU_SG_REL_ IC3 SG_ 1185 UncalLoadTrkFAxle2_ISig_4 3000;
BA_REL_ "GenSigFirstTimeoutTime" BU_SG_REL_ IC3 SG_ 1185 UncalLoadTrkRAxle1_ISig_4 12000;
BA_REL_ "GenSigTimeoutTime" BU_SG_REL_ IC3 SG_ 1185 UncalLoadTrkRAxle1_ISig_4 3000;
BA_REL_ "GenSigFirstTimeoutTime" BU_SG_REL_ IC3 SG_ 1333 SuspensionGCVW_ISig_4 24000;
BA_REL_ "GenSigTimeoutTime" BU_SG_REL_ IC3 SG_ 1333 SuspensionGCVW_ISig_4 6000;
BA_REL_ "GenSigFirstTimeoutTime" BU_SG_REL_ IC3 SG_ 1333 SelectedLocalTimeOffset_stat_ISi 24000;
BA_REL_ "GenSigTimeoutTime" BU_SG_REL_ IC3 SG_ 1333 SelectedLocalTimeOffset_stat_ISi 6000;
BA_REL_ "GenSigFirstTimeoutTime" BU_SG_REL_ IC3 SG_ 1596 SavedUnit20_TrailerName 60000;
BA_REL_ "GenSigTimeoutTime" BU_SG_REL_ IC3 SG_ 1596 SavedUnit20_TrailerName 60000;
BA_REL_ "GenSigFirstTimeoutTime" BU_SG_REL_ IC3 SG_ 1596 SavedUnit20_TrailerPosition 60000;
BA_REL_ "GenSigTimeoutTime" BU_SG_REL_ IC3 SG_ 1596 SavedUnit20_TrailerPosition 60000;
BA_REL_ "GenSigFirstTimeoutTime" BU_SG_REL_ IC3 SG_ 1594 SavedUnit19_TrailerName 60000;
BA_REL_ "GenSigTimeoutTime" BU_SG_REL_ IC3 SG_ 1594 SavedUnit19_TrailerName 60000;
BA_REL_ "GenSigFirstTimeoutTime" BU_SG_REL_ IC3 SG_ 1594 SavedUnit19_TrailerPosition 60000;
BA_REL_ "GenSigTimeoutTime" BU_SG_REL_ IC3 SG_ 1594 SavedUnit19_TrailerPosition 60000;
BA_REL_ "GenSigFirstTimeoutTime" BU_SG_REL_ IC3 SG_ 1592 SavedUnit18_TrailerPosition 60000;
BA_REL_ "GenSigTimeoutTime" BU_SG_REL_ IC3 SG_ 1592 SavedUnit18_TrailerPosition 60000;
BA_REL_ "GenSigFirstTimeoutTime" BU_SG_REL_ IC3 SG_ 1592 SavedUnit18_TrailerName 60000;
BA_REL_ "GenSigTimeoutTime" BU_SG_REL_ IC3 SG_ 1592 SavedUnit18_TrailerName 60000;
BA_REL_ "GenSigFirstTimeoutTime" BU_SG_REL_ IC3 SG_ 1590 SavedUnit17_TrailerPosition 60000;
BA_REL_ "GenSigTimeoutTime" BU_SG_REL_ IC3 SG_ 1590 SavedUnit17_TrailerPosition 60000;
BA_REL_ "GenSigFirstTimeoutTime" BU_SG_REL_ IC3 SG_ 1590 SavedUnit17_TrailerName 60000;
BA_REL_ "GenSigTimeoutTime" BU_SG_REL_ IC3 SG_ 1590 SavedUnit17_TrailerName 60000;
BA_REL_ "GenSigFirstTimeoutTime" BU_SG_REL_ IC3 SG_ 1588 SavedUnit16_TrailerName 60000;
BA_REL_ "GenSigTimeoutTime" BU_SG_REL_ IC3 SG_ 1588 SavedUnit16_TrailerName 60000;
BA_REL_ "GenSigFirstTimeoutTime" BU_SG_REL_ IC3 SG_ 1588 SavedUnit16_TrailerPosition 60000;
BA_REL_ "GenSigTimeoutTime" BU_SG_REL_ IC3 SG_ 1588 SavedUnit16_TrailerPosition 60000;
BA_REL_ "GenSigFirstTimeoutTime" BU_SG_REL_ IC3 SG_ 1586 SavedUnit15_TrailerName 60000;
BA_REL_ "GenSigTimeoutTime" BU_SG_REL_ IC3 SG_ 1586 SavedUnit15_TrailerName 60000;
BA_REL_ "GenSigFirstTimeoutTime" BU_SG_REL_ IC3 SG_ 1586 SavedUnit15_TrailerPosition 60000;
BA_REL_ "GenSigTimeoutTime" BU_SG_REL_ IC3 SG_ 1586 SavedUnit15_TrailerPosition 60000;
BA_REL_ "GenSigFirstTimeoutTime" BU_SG_REL_ IC3 SG_ 1584 SavedUnit14_TrailerPosition 60000;
BA_REL_ "GenSigTimeoutTime" BU_SG_REL_ IC3 SG_ 1584 SavedUnit14_TrailerPosition 60000;
BA_REL_ "GenSigFirstTimeoutTime" BU_SG_REL_ IC3 SG_ 1584 SavedUnit14_TrailerName 60000;
BA_REL_ "GenSigTimeoutTime" BU_SG_REL_ IC3 SG_ 1584 SavedUnit14_TrailerName 60000;
BA_REL_ "GenSigFirstTimeoutTime" BU_SG_REL_ IC3 SG_ 1576 SavedUnit13_TrailerPosition 60000;
BA_REL_ "GenSigTimeoutTime" BU_SG_REL_ IC3 SG_ 1576 SavedUnit13_TrailerPosition 60000;
BA_REL_ "GenSigFirstTimeoutTime" BU_SG_REL_ IC3 SG_ 1576 SavedUnit13_TrailerName 60000;
BA_REL_ "GenSigTimeoutTime" BU_SG_REL_ IC3 SG_ 1576 SavedUnit13_TrailerName 60000;
BA_REL_ "GenSigFirstTimeoutTime" BU_SG_REL_ IC3 SG_ 1574 SavedUnit12_TrailerName 60000;
BA_REL_ "GenSigTimeoutTime" BU_SG_REL_ IC3 SG_ 1574 SavedUnit12_TrailerName 60000;
BA_REL_ "GenSigFirstTimeoutTime" BU_SG_REL_ IC3 SG_ 1574 SavedUnit12_TrailerPosition 60000;
BA_REL_ "GenSigTimeoutTime" BU_SG_REL_ IC3 SG_ 1574 SavedUnit12_TrailerPosition 60000;
BA_REL_ "GenSigFirstTimeoutTime" BU_SG_REL_ IC3 SG_ 1572 SavedUnit11_TrailerPosition 60000;
BA_REL_ "GenSigTimeoutTime" BU_SG_REL_ IC3 SG_ 1572 SavedUnit11_TrailerPosition 60000;
BA_REL_ "GenSigFirstTimeoutTime" BU_SG_REL_ IC3 SG_ 1572 SavedUnit11_TrailerName 60000;
BA_REL_ "GenSigTimeoutTime" BU_SG_REL_ IC3 SG_ 1572 SavedUnit11_TrailerName 60000;
BA_REL_ "GenSigFirstTimeoutTime" BU_SG_REL_ IC3 SG_ 1570 SavedUnit10_TrailerName 60000;
BA_REL_ "GenSigTimeoutTime" BU_SG_REL_ IC3 SG_ 1570 SavedUnit10_TrailerName 60000;
BA_REL_ "GenSigFirstTimeoutTime" BU_SG_REL_ IC3 SG_ 1570 SavedUnit10_TrailerPosition 60000;
BA_REL_ "GenSigTimeoutTime" BU_SG_REL_ IC3 SG_ 1570 SavedUnit10_TrailerPosition 60000;
BA_REL_ "GenSigFirstTimeoutTime" BU_SG_REL_ IC3 SG_ 1568 SavedUnit9_TrailerName 60000;
BA_REL_ "GenSigTimeoutTime" BU_SG_REL_ IC3 SG_ 1568 SavedUnit9_TrailerName 60000;
BA_REL_ "GenSigFirstTimeoutTime" BU_SG_REL_ IC3 SG_ 1568 SavedUnit9_TrailerPosition 60000;
BA_REL_ "GenSigTimeoutTime" BU_SG_REL_ IC3 SG_ 1568 SavedUnit9_TrailerPosition 60000;
BA_REL_ "GenSigFirstTimeoutTime" BU_SG_REL_ IC3 SG_ 1566 SavedUnit8_TrailerName 60000;
BA_REL_ "GenSigTimeoutTime" BU_SG_REL_ IC3 SG_ 1566 SavedUnit8_TrailerName 60000;
BA_REL_ "GenSigFirstTimeoutTime" BU_SG_REL_ IC3 SG_ 1566 SavedUnit8_TrailerPosition 60000;
BA_REL_ "GenSigTimeoutTime" BU_SG_REL_ IC3 SG_ 1566 SavedUnit8_TrailerPosition 60000;
BA_REL_ "GenSigFirstTimeoutTime" BU_SG_REL_ IC3 SG_ 1564 SavedUnit7_TrailerPosition 60000;
BA_REL_ "GenSigTimeoutTime" BU_SG_REL_ IC3 SG_ 1564 SavedUnit7_TrailerPosition 60000;
BA_REL_ "GenSigFirstTimeoutTime" BU_SG_REL_ IC3 SG_ 1564 SavedUnit7_TrailerName 60000;
BA_REL_ "GenSigTimeoutTime" BU_SG_REL_ IC3 SG_ 1564 SavedUnit7_TrailerName 60000;
BA_REL_ "GenSigFirstTimeoutTime" BU_SG_REL_ IC3 SG_ 1562 SavedUnit6_TrailerPosition 60000;
BA_REL_ "GenSigTimeoutTime" BU_SG_REL_ IC3 SG_ 1562 SavedUnit6_TrailerPosition 60000;
BA_REL_ "GenSigFirstTimeoutTime" BU_SG_REL_ IC3 SG_ 1562 SavedUnit6_TrailerName 60000;
BA_REL_ "GenSigTimeoutTime" BU_SG_REL_ IC3 SG_ 1562 SavedUnit6_TrailerName 60000;
BA_REL_ "GenSigFirstTimeoutTime" BU_SG_REL_ IC3 SG_ 1560 SavedUnit5_TrailerName 60000;
BA_REL_ "GenSigTimeoutTime" BU_SG_REL_ IC3 SG_ 1560 SavedUnit5_TrailerName 60000;
BA_REL_ "GenSigFirstTimeoutTime" BU_SG_REL_ IC3 SG_ 1560 SavedUnit5_TrailerPosition 60000;
BA_REL_ "GenSigTimeoutTime" BU_SG_REL_ IC3 SG_ 1560 SavedUnit5_TrailerPosition 60000;
BA_REL_ "GenSigFirstTimeoutTime" BU_SG_REL_ IC3 SG_ 1558 SavedUnit4_TrailerPosition 60000;
BA_REL_ "GenSigTimeoutTime" BU_SG_REL_ IC3 SG_ 1558 SavedUnit4_TrailerPosition 60000;
BA_REL_ "GenSigFirstTimeoutTime" BU_SG_REL_ IC3 SG_ 1558 SavedUnit4_TrailerName 60000;
BA_REL_ "GenSigTimeoutTime" BU_SG_REL_ IC3 SG_ 1558 SavedUnit4_TrailerName 60000;
BA_REL_ "GenSigFirstTimeoutTime" BU_SG_REL_ IC3 SG_ 1556 SavedUnit3_TrailerPosition 60000;
BA_REL_ "GenSigTimeoutTime" BU_SG_REL_ IC3 SG_ 1556 SavedUnit3_TrailerPosition 60000;
BA_REL_ "GenSigFirstTimeoutTime" BU_SG_REL_ IC3 SG_ 1556 SavedUnit3_TrailerName 60000;
BA_REL_ "GenSigTimeoutTime" BU_SG_REL_ IC3 SG_ 1556 SavedUnit3_TrailerName 60000;
BA_REL_ "GenSigFirstTimeoutTime" BU_SG_REL_ IC3 SG_ 1554 SavedUnit2_TrailerName 60000;
BA_REL_ "GenSigTimeoutTime" BU_SG_REL_ IC3 SG_ 1554 SavedUnit2_TrailerName 60000;
BA_REL_ "GenSigFirstTimeoutTime" BU_SG_REL_ IC3 SG_ 1554 SavedUnit2_TrailerPosition 60000;
BA_REL_ "GenSigTimeoutTime" BU_SG_REL_ IC3 SG_ 1554 SavedUnit2_TrailerPosition 60000;
BA_REL_ "GenSigFirstTimeoutTime" BU_SG_REL_ IC3 SG_ 1552 SavedUnit1_TrailerPosition 60000;
BA_REL_ "GenSigTimeoutTime" BU_SG_REL_ IC3 SG_ 1552 SavedUnit1_TrailerPosition 60000;
BA_REL_ "GenSigFirstTimeoutTime" BU_SG_REL_ IC3 SG_ 1552 SavedUnit1_TrailerName 60000;
BA_REL_ "GenSigTimeoutTime" BU_SG_REL_ IC3 SG_ 1552 SavedUnit1_TrailerName 60000;
BA_REL_ "GenSigFirstTimeoutTime" BU_SG_REL_ IC3 SG_ 1293 EventTimerAck_Oper 6000;
BA_REL_ "GenSigTimeoutTime" BU_SG_REL_ IC3 SG_ 1293 EventTimerAck_Oper 1500;
BA_REL_ "GenSigFirstTimeoutTime" BU_SG_REL_ IC3 SG_ 1293 EventTimerTrig_Id 6000;
BA_REL_ "GenSigTimeoutTime" BU_SG_REL_ IC3 SG_ 1293 EventTimerTrig_Id 1500;
BA_REL_ "GenSigFirstTimeoutTime" BU_SG_REL_ IC3 SG_ 1293 LoadDistributionSelected2_ISig_4 6000;
BA_REL_ "GenSigTimeoutTime" BU_SG_REL_ IC3 SG_ 1293 LoadDistributionSelected2_ISig_4 1500;
BA_REL_ "GenSigFirstTimeoutTime" BU_SG_REL_ IC3 SG_ 1293 EventTimerAck_Time 6000;
BA_REL_ "GenSigTimeoutTime" BU_SG_REL_ IC3 SG_ 1293 EventTimerAck_Time 1500;
BA_REL_ "GenSigFirstTimeoutTime" BU_SG_REL_ TECU SG_ 1293 RSLAssistStatus 6000;
BA_REL_ "GenSigTimeoutTime" BU_SG_REL_ TECU SG_ 1293 RSLAssistStatus 1500;
BA_REL_ "GenSigFirstTimeoutTime" BU_SG_REL_ IC3 SG_ 1293 StartBatteryVoltageDisplay_ISig_ 6000;
BA_REL_ "GenSigTimeoutTime" BU_SG_REL_ IC3 SG_ 1293 StartBatteryVoltageDisplay_ISig_ 1500;
BA_REL_ "GenSigFirstTimeoutTime" BU_SG_REL_ IC3 SG_ 1293 EventTimerAck_Id 6000;
BA_REL_ "GenSigTimeoutTime" BU_SG_REL_ IC3 SG_ 1293 EventTimerAck_Id 1500;
BA_REL_ "GenSigFirstTimeoutTime" BU_SG_REL_ IC3 SG_ 1271 DayOfWeek_stat_ISig_4 4800;
BA_REL_ "GenSigTimeoutTime" BU_SG_REL_ IC3 SG_ 1271 DayOfWeek_stat_ISig_4 1200;
BA_REL_ "GenSigFirstTimeoutTime" BU_SG_REL_ CIOM SG_ 1271 DayOfWeek_stat_ISig_4 4800;
BA_REL_ "GenSigTimeoutTime" BU_SG_REL_ CIOM SG_ 1271 DayOfWeek_stat_ISig_4 1200;
BA_REL_ "GenSigFirstTimeoutTime" BU_SG_REL_ IC3 SG_ 1271 MinutesLocal_ISig_4 4800;
BA_REL_ "GenSigTimeoutTime" BU_SG_REL_ IC3 SG_ 1271 MinutesLocal_ISig_4 1200;
BA_REL_ "GenSigFirstTimeoutTime" BU_SG_REL_ CIOM SG_ 1271 MinutesLocal_ISig_4 4800;
BA_REL_ "GenSigTimeoutTime" BU_SG_REL_ CIOM SG_ 1271 MinutesLocal_ISig_4 1200;
BA_REL_ "GenSigFirstTimeoutTime" BU_SG_REL_ IC3 SG_ 1271 DayLocal_ISig_4 4800;
BA_REL_ "GenSigTimeoutTime" BU_SG_REL_ IC3 SG_ 1271 DayLocal_ISig_4 1200;
BA_REL_ "GenSigFirstTimeoutTime" BU_SG_REL_ CIOM SG_ 1271 DayLocal_ISig_4 4800;
BA_REL_ "GenSigTimeoutTime" BU_SG_REL_ CIOM SG_ 1271 DayLocal_ISig_4 1200;
BA_REL_ "GenSigFirstTimeoutTime" BU_SG_REL_ IC3 SG_ 1271 MonthLocal_ISig_4 4800;
BA_REL_ "GenSigTimeoutTime" BU_SG_REL_ IC3 SG_ 1271 MonthLocal_ISig_4 1200;
BA_REL_ "GenSigFirstTimeoutTime" BU_SG_REL_ CIOM SG_ 1271 MonthLocal_ISig_4 4800;
BA_REL_ "GenSigTimeoutTime" BU_SG_REL_ CIOM SG_ 1271 MonthLocal_ISig_4 1200;
BA_REL_ "GenSigFirstTimeoutTime" BU_SG_REL_ IC3 SG_ 1271 SecondsLocal_ISig_4 4800;
BA_REL_ "GenSigTimeoutTime" BU_SG_REL_ IC3 SG_ 1271 SecondsLocal_ISig_4 1200;
BA_REL_ "GenSigFirstTimeoutTime" BU_SG_REL_ CIOM SG_ 1271 SecondsLocal_ISig_4 4800;
BA_REL_ "GenSigTimeoutTime" BU_SG_REL_ CIOM SG_ 1271 SecondsLocal_ISig_4 1200;
BA_REL_ "GenSigFirstTimeoutTime" BU_SG_REL_ IC3 SG_ 1271 SelectedDaylightSaving_stat 4800;
BA_REL_ "GenSigTimeoutTime" BU_SG_REL_ IC3 SG_ 1271 SelectedDaylightSaving_stat 1200;
BA_REL_ "GenSigFirstTimeoutTime" BU_SG_REL_ TECU SG_ 1271 SavedHeightControlMode_ISig_4 4800;
BA_REL_ "GenSigTimeoutTime" BU_SG_REL_ TECU SG_ 1271 SavedHeightControlMode_ISig_4 1200;
BA_REL_ "GenSigFirstTimeoutTime" BU_SG_REL_ CIOM SG_ 1271 YearLocal_ISig_4 4800;
BA_REL_ "GenSigTimeoutTime" BU_SG_REL_ CIOM SG_ 1271 YearLocal_ISig_4 1200;
BA_REL_ "GenSigFirstTimeoutTime" BU_SG_REL_ IC3 SG_ 1271 YearLocal_ISig_4 4800;
BA_REL_ "GenSigTimeoutTime" BU_SG_REL_ IC3 SG_ 1271 YearLocal_ISig_4 1200;
BA_REL_ "GenSigFirstTimeoutTime" BU_SG_REL_ IC3 SG_ 1271 HoursLocal_ISig_4 4800;
BA_REL_ "GenSigTimeoutTime" BU_SG_REL_ IC3 SG_ 1271 HoursLocal_ISig_4 1200;
BA_REL_ "GenSigFirstTimeoutTime" BU_SG_REL_ CIOM SG_ 1271 HoursLocal_ISig_4 4800;
BA_REL_ "GenSigTimeoutTime" BU_SG_REL_ CIOM SG_ 1271 HoursLocal_ISig_4 1200;
BA_REL_ "GenSigFirstTimeoutTime" BU_SG_REL_ TECU SG_ 391 RequestedUpshiftDownshiftSteps 3000;
BA_REL_ "GenSigTimeoutTime" BU_SG_REL_ TECU SG_ 391 RequestedUpshiftDownshiftSteps 120;
BA_REL_ "GenSigFirstTimeoutTime" BU_SG_REL_ TECU SG_ 391 GearLeverPosition_ISig_4 3000;
BA_REL_ "GenSigTimeoutTime" BU_SG_REL_ TECU SG_ 391 GearLeverPosition_ISig_4 500;
BA_REL_ "GenSigFirstTimeoutTime" BU_SG_REL_ BBM SG_ 391 GearLeverPosition_ISig_4 3000;
BA_REL_ "GenSigTimeoutTime" BU_SG_REL_ BBM SG_ 391 GearLeverPosition_ISig_4 500;
BA_REL_ "GenSigFirstTimeoutTime" BU_SG_REL_ DACU SG_ 391 GearLeverPosition_ISig_4 3000;
BA_REL_ "GenSigTimeoutTime" BU_SG_REL_ DACU SG_ 391 GearLeverPosition_ISig_4 500;
BA_REL_ "GenSigFirstTimeoutTime" BU_SG_REL_ IC3 SG_ 391 GearLeverPosition_ISig_4 3000;
BA_REL_ "GenSigTimeoutTime" BU_SG_REL_ IC3 SG_ 391 GearLeverPosition_ISig_4 500;
BA_REL_ "GenSigFirstTimeoutTime" BU_SG_REL_ TECU SG_ 391 DownShiftRequest 3000;
BA_REL_ "GenSigTimeoutTime" BU_SG_REL_ TECU SG_ 391 DownShiftRequest 120;
BA_REL_ "GenSigFirstTimeoutTime" BU_SG_REL_ TECU SG_ 391 UpShiftRequest 3000;
BA_REL_ "GenSigTimeoutTime" BU_SG_REL_ TECU SG_ 391 UpShiftRequest 120;
BA_REL_ "GenSigFirstTimeoutTime" BU_SG_REL_ TECU SG_ 391 LimpHomeSwitch_stat 3000;
BA_REL_ "GenSigTimeoutTime" BU_SG_REL_ TECU SG_ 391 LimpHomeSwitch_stat 120;
BA_REL_ "GenSigFirstTimeoutTime" BU_SG_REL_ TECU SG_ 391 RequestForHighestGearRatio 3000;
BA_REL_ "GenSigTimeoutTime" BU_SG_REL_ TECU SG_ 391 RequestForHighestGearRatio 120;
BA_REL_ "GenSigFirstTimeoutTime" BU_SG_REL_ TECU SG_ 391 EconomyPowerSwitch_stat 3000;
BA_REL_ "GenSigTimeoutTime" BU_SG_REL_ TECU SG_ 391 EconomyPowerSwitch_stat 120;
BA_REL_ "GenSigFirstTimeoutTime" BU_SG_REL_ EMS SG_ 391 SteeringValvePositionSetPoint 3000;
BA_REL_ "GenSigTimeoutTime" BU_SG_REL_ EMS SG_ 391 SteeringValvePositionSetPoint 120;
BA_REL_ "GenSigFirstTimeoutTime" BU_SG_REL_ IC3 SG_ 1053 AlarmClockAlarms_stat_Mode 3600;
BA_REL_ "GenSigTimeoutTime" BU_SG_REL_ IC3 SG_ 1053 AlarmClockAlarms_stat_Mode 900;
BA_REL_ "GenSigFirstTimeoutTime" BU_SG_REL_ IC3 SG_ 1053 AlarmClockAlarms_stat_Type 3600;
BA_REL_ "GenSigTimeoutTime" BU_SG_REL_ IC3 SG_ 1053 AlarmClockAlarms_stat_Type 900;
BA_REL_ "GenSigFirstTimeoutTime" BU_SG_REL_ IC3 SG_ 1053 AlarmClockAlarms_stat_DaySet 3600;
BA_REL_ "GenSigTimeoutTime" BU_SG_REL_ IC3 SG_ 1053 AlarmClockAlarms_stat_DaySet 900;
BA_REL_ "GenSigFirstTimeoutTime" BU_SG_REL_ IC3 SG_ 1053 AlarmClockAlarms_stat_ID 3600;
BA_REL_ "GenSigTimeoutTime" BU_SG_REL_ IC3 SG_ 1053 AlarmClockAlarms_stat_ID 900;
BA_REL_ "GenSigFirstTimeoutTime" BU_SG_REL_ IC3 SG_ 1053 AlmClkCurAlarm_stat_SetMin 3600;
BA_REL_ "GenSigTimeoutTime" BU_SG_REL_ IC3 SG_ 1053 AlmClkCurAlarm_stat_SetMin 900;
BA_REL_ "GenSigFirstTimeoutTime" BU_SG_REL_ CIOM SG_ 1053 AlmClkCurAlarm_stat_SetMin 3600;
BA_REL_ "GenSigTimeoutTime" BU_SG_REL_ CIOM SG_ 1053 AlmClkCurAlarm_stat_SetMin 900;
BA_REL_ "GenSigFirstTimeoutTime" BU_SG_REL_ IC3 SG_ 1053 AlarmClockAlarms_stat_Stat 3600;
BA_REL_ "GenSigTimeoutTime" BU_SG_REL_ IC3 SG_ 1053 AlarmClockAlarms_stat_Stat 900;
BA_REL_ "GenSigFirstTimeoutTime" BU_SG_REL_ CIOM SG_ 1053 AlmClkCurAlarm_stat_Stat 3600;
BA_REL_ "GenSigTimeoutTime" BU_SG_REL_ CIOM SG_ 1053 AlmClkCurAlarm_stat_Stat 900;
BA_REL_ "GenSigFirstTimeoutTime" BU_SG_REL_ IC3 SG_ 1053 AlmClkCurAlarm_stat_Stat 3600;
BA_REL_ "GenSigTimeoutTime" BU_SG_REL_ IC3 SG_ 1053 AlmClkCurAlarm_stat_Stat 900;
BA_REL_ "GenSigFirstTimeoutTime" BU_SG_REL_ IC3 SG_ 1053 AlmClkCurAlarm_stat_ID 3600;
BA_REL_ "GenSigTimeoutTime" BU_SG_REL_ IC3 SG_ 1053 AlmClkCurAlarm_stat_ID 900;
BA_REL_ "GenSigFirstTimeoutTime" BU_SG_REL_ CIOM SG_ 1053 AlmClkCurAlarm_stat_ID 3600;
BA_REL_ "GenSigTimeoutTime" BU_SG_REL_ CIOM SG_ 1053 AlmClkCurAlarm_stat_ID 900;
BA_REL_ "GenSigFirstTimeoutTime" BU_SG_REL_ IC3 SG_ 1053 AlarmClockAlarms_stat_SetMin 3600;
BA_REL_ "GenSigTimeoutTime" BU_SG_REL_ IC3 SG_ 1053 AlarmClockAlarms_stat_SetMin 900;
BA_REL_ "GenSigFirstTimeoutTime" BU_SG_REL_ IC3 SG_ 1053 AlmClkCurAlarm_stat_Type 3600;
BA_REL_ "GenSigTimeoutTime" BU_SG_REL_ IC3 SG_ 1053 AlmClkCurAlarm_stat_Type 900;
BA_REL_ "GenSigFirstTimeoutTime" BU_SG_REL_ CIOM SG_ 1053 AlmClkCurAlarm_stat_Type 3600;
BA_REL_ "GenSigTimeoutTime" BU_SG_REL_ CIOM SG_ 1053 AlmClkCurAlarm_stat_Type 900;
BA_REL_ "GenSigFirstTimeoutTime" BU_SG_REL_ IC3 SG_ 1053 AlarmClockAlarms_stat_SetHr 3600;
BA_REL_ "GenSigTimeoutTime" BU_SG_REL_ IC3 SG_ 1053 AlarmClockAlarms_stat_SetHr 900;
BA_REL_ "GenSigFirstTimeoutTime" BU_SG_REL_ IC3 SG_ 1053 AlmClkCurAlarm_stat_SetHr 3600;
BA_REL_ "GenSigTimeoutTime" BU_SG_REL_ IC3 SG_ 1053 AlmClkCurAlarm_stat_SetHr 900;
BA_REL_ "GenSigFirstTimeoutTime" BU_SG_REL_ CIOM SG_ 1053 AlmClkCurAlarm_stat_SetHr 3600;
BA_REL_ "GenSigTimeoutTime" BU_SG_REL_ CIOM SG_ 1053 AlmClkCurAlarm_stat_SetHr 900;
BA_REL_ "GenSigFirstTimeoutTime" BU_SG_REL_ HPCU SG_ 1095 HVChrgnAlld 3000;
BA_REL_ "GenSigTimeoutTime" BU_SG_REL_ HPCU SG_ 1095 HVChrgnAlld 600;
BA_REL_ "GenSigFirstTimeoutTime" BU_SG_REL_ IC3 SG_ 1095 IdleAdjustFailedPreconStat 3000;
BA_REL_ "GenSigTimeoutTime" BU_SG_REL_ IC3 SG_ 1095 IdleAdjustFailedPreconStat 600;
BA_REL_ "GenSigFirstTimeoutTime" BU_SG_REL_ CIOM SG_ 1095 ParkHeaterTimerReleased_stat_ISi 3000;
BA_REL_ "GenSigTimeoutTime" BU_SG_REL_ CIOM SG_ 1095 ParkHeaterTimerReleased_stat_ISi 600;
BA_REL_ "GenSigFirstTimeoutTime" BU_SG_REL_ CIOM SG_ 1095 PHTimerRqstAck_Hours_ISig_4 3000;
BA_REL_ "GenSigTimeoutTime" BU_SG_REL_ CIOM SG_ 1095 PHTimerRqstAck_Hours_ISig_4 600;
BA_REL_ "GenSigFirstTimeoutTime" BU_SG_REL_ CIOM SG_ 1095 PHTimerRqstAck_CurrentOp_ISig_4 3000;
BA_REL_ "GenSigTimeoutTime" BU_SG_REL_ CIOM SG_ 1095 PHTimerRqstAck_CurrentOp_ISig_4 600;
BA_REL_ "GenSigFirstTimeoutTime" BU_SG_REL_ CIOM SG_ 1095 PHTimerRqstAck_DayOfWeekRq_ISig_ 3000;
BA_REL_ "GenSigTimeoutTime" BU_SG_REL_ CIOM SG_ 1095 PHTimerRqstAck_DayOfWeekRq_ISig_ 600;
BA_REL_ "GenSigFirstTimeoutTime" BU_SG_REL_ CIOM SG_ 1095 PHTimerRqstAck_Minutes_ISig_4 3000;
BA_REL_ "GenSigTimeoutTime" BU_SG_REL_ CIOM SG_ 1095 PHTimerRqstAck_Minutes_ISig_4 600;
BA_REL_ "GenSigFirstTimeoutTime" BU_SG_REL_ CIOM SG_ 1095 AlarmClockNotification_Stat_ISig 3000;
BA_REL_ "GenSigTimeoutTime" BU_SG_REL_ CIOM SG_ 1095 AlarmClockNotification_Stat_ISig 600;
BA_REL_ "GenSigFirstTimeoutTime" BU_SG_REL_ IC3 SG_ 1095 AlarmClockNotification_Stat_ISig 3000;
BA_REL_ "GenSigTimeoutTime" BU_SG_REL_ IC3 SG_ 1095 AlarmClockNotification_Stat_ISig 600;
BA_REL_ "GenSigFirstTimeoutTime" BU_SG_REL_ IC3 SG_ 1095 AlarmClockNotification_Type_ISig 3000;
BA_REL_ "GenSigTimeoutTime" BU_SG_REL_ IC3 SG_ 1095 AlarmClockNotification_Type_ISig 600;
BA_REL_ "GenSigFirstTimeoutTime" BU_SG_REL_ CIOM SG_ 1095 AlarmClockNotification_Type_ISig 3000;
BA_REL_ "GenSigTimeoutTime" BU_SG_REL_ CIOM SG_ 1095 AlarmClockNotification_Type_ISig 600;
BA_REL_ "GenSigFirstTimeoutTime" BU_SG_REL_ IC3 SG_ 1095 AlarmClockNotification_ID_ISig_4 3000;
BA_REL_ "GenSigTimeoutTime" BU_SG_REL_ IC3 SG_ 1095 AlarmClockNotification_ID_ISig_4 600;
BA_REL_ "GenSigFirstTimeoutTime" BU_SG_REL_ CIOM SG_ 1095 AlarmClockNotification_ID_ISig_4 3000;
BA_REL_ "GenSigTimeoutTime" BU_SG_REL_ CIOM SG_ 1095 AlarmClockNotification_ID_ISig_4 600;
BA_REL_ "GenSigFirstTimeoutTime" BU_SG_REL_ IC3 SG_ 1316 LoadIndCalWarning_Movement_ISig_ 24000;
BA_REL_ "GenSigTimeoutTime" BU_SG_REL_ IC3 SG_ 1316 LoadIndCalWarning_Movement_ISig_ 6000;
BA_REL_ "GenSigFirstTimeoutTime" BU_SG_REL_ IC3 SG_ 1316 LoadIndCalWarning_LiftedAxle_ISi 24000;
BA_REL_ "GenSigTimeoutTime" BU_SG_REL_ IC3 SG_ 1316 LoadIndCalWarning_LiftedAxle_ISi 6000;
BA_REL_ "GenSigFirstTimeoutTime" BU_SG_REL_ IC3 SG_ 1316 LoadIndCalWarning_LowSupplyPress 24000;
BA_REL_ "GenSigTimeoutTime" BU_SG_REL_ IC3 SG_ 1316 LoadIndCalWarning_LowSupplyPress 6000;
BA_REL_ "GenSigFirstTimeoutTime" BU_SG_REL_ IC3 SG_ 1316 LoadIndCalWarning_PBrakeApplied_ 24000;
BA_REL_ "GenSigTimeoutTime" BU_SG_REL_ IC3 SG_ 1316 LoadIndCalWarning_PBrakeApplied_ 6000;
BA_REL_ "GenSigFirstTimeoutTime" BU_SG_REL_ IC3 SG_ 1316 LoadIndCalWarning_SBrakesApplied 24000;
BA_REL_ "GenSigTimeoutTime" BU_SG_REL_ IC3 SG_ 1316 LoadIndCalWarning_SBrakesApplied 6000;
BA_REL_ "GenSigFirstTimeoutTime" BU_SG_REL_ IC3 SG_ 1316 LoadIndCalWarning_HighInclin_ISi 24000;
BA_REL_ "GenSigTimeoutTime" BU_SG_REL_ IC3 SG_ 1316 LoadIndCalWarning_HighInclin_ISi 6000;
BA_REL_ "GenSigFirstTimeoutTime" BU_SG_REL_ IC3 SG_ 1316 LoadTrailer3_ISig_4 24000;
BA_REL_ "GenSigTimeoutTime" BU_SG_REL_ IC3 SG_ 1316 LoadTrailer3_ISig_4 6000;
BA_REL_ "GenSigFirstTimeoutTime" BU_SG_REL_ BBM SG_ 1316 LoadTrailer3_ISig_4 24000;
BA_REL_ "GenSigTimeoutTime" BU_SG_REL_ BBM SG_ 1316 LoadTrailer3_ISig_4 6000;
BA_REL_ "GenSigFirstTimeoutTime" BU_SG_REL_ CIOM SG_ 1316 LoadTrailer3_ISig_4 24000;
BA_REL_ "GenSigTimeoutTime" BU_SG_REL_ CIOM SG_ 1316 LoadTrailer3_ISig_4 6000;
BA_REL_ "GenSigFirstTimeoutTime" BU_SG_REL_ IC3 SG_ 1316 LoadIndCalWarning_GearNotNeutral 24000;
BA_REL_ "GenSigTimeoutTime" BU_SG_REL_ IC3 SG_ 1316 LoadIndCalWarning_GearNotNeutral 6000;
BA_REL_ "GenSigFirstTimeoutTime" BU_SG_REL_ IC3 SG_ 1315 LoadTrailer2Back_ISig_4 24000;
BA_REL_ "GenSigTimeoutTime" BU_SG_REL_ IC3 SG_ 1315 LoadTrailer2Back_ISig_4 6000;
BA_REL_ "GenSigFirstTimeoutTime" BU_SG_REL_ IC3 SG_ 1315 LoadTrailer3Front_ISig_4 24000;
BA_REL_ "GenSigTimeoutTime" BU_SG_REL_ IC3 SG_ 1315 LoadTrailer3Front_ISig_4 6000;
BA_REL_ "GenSigFirstTimeoutTime" BU_SG_REL_ IC3 SG_ 1315 LoadTrailer5Back_ISig_4 24000;
BA_REL_ "GenSigTimeoutTime" BU_SG_REL_ IC3 SG_ 1315 LoadTrailer5Back_ISig_4 6000;
BA_REL_ "GenSigFirstTimeoutTime" BU_SG_REL_ IC3 SG_ 1315 LoadTrailer4Front_ISig_4 24000;
BA_REL_ "GenSigTimeoutTime" BU_SG_REL_ IC3 SG_ 1315 LoadTrailer4Front_ISig_4 6000;
BA_REL_ "GenSigFirstTimeoutTime" BU_SG_REL_ IC3 SG_ 1314 LoadTrailer1Front_ISig_4 24000;
BA_REL_ "GenSigTimeoutTime" BU_SG_REL_ IC3 SG_ 1314 LoadTrailer1Front_ISig_4 6000;
BA_REL_ "GenSigFirstTimeoutTime" BU_SG_REL_ IC3 SG_ 1314 LoadTruck_ISig_4 24000;
BA_REL_ "GenSigTimeoutTime" BU_SG_REL_ IC3 SG_ 1314 LoadTruck_ISig_4 6000;
BA_REL_ "GenSigFirstTimeoutTime" BU_SG_REL_ CIOM SG_ 1314 LoadTruck_ISig_4 24000;
BA_REL_ "GenSigTimeoutTime" BU_SG_REL_ CIOM SG_ 1314 LoadTruck_ISig_4 6000;
BA_REL_ "GenSigFirstTimeoutTime" BU_SG_REL_ DACU SG_ 1314 LoadTruck_ISig_4 24000;
BA_REL_ "GenSigTimeoutTime" BU_SG_REL_ DACU SG_ 1314 LoadTruck_ISig_4 6000;
BA_REL_ "GenSigFirstTimeoutTime" BU_SG_REL_ BBM SG_ 1314 LoadTruck_ISig_4 24000;
BA_REL_ "GenSigTimeoutTime" BU_SG_REL_ BBM SG_ 1314 LoadTruck_ISig_4 6000;
BA_REL_ "GenSigFirstTimeoutTime" BU_SG_REL_ BBM SG_ 1314 LoadTrailer1_ISig_4 24000;
BA_REL_ "GenSigTimeoutTime" BU_SG_REL_ BBM SG_ 1314 LoadTrailer1_ISig_4 6000;
BA_REL_ "GenSigFirstTimeoutTime" BU_SG_REL_ IC3 SG_ 1314 LoadTrailer1_ISig_4 24000;
BA_REL_ "GenSigTimeoutTime" BU_SG_REL_ IC3 SG_ 1314 LoadTrailer1_ISig_4 6000;
BA_REL_ "GenSigFirstTimeoutTime" BU_SG_REL_ CIOM SG_ 1314 LoadTrailer1_ISig_4 24000;
BA_REL_ "GenSigTimeoutTime" BU_SG_REL_ CIOM SG_ 1314 LoadTrailer1_ISig_4 6000;
BA_REL_ "GenSigFirstTimeoutTime" BU_SG_REL_ IC3 SG_ 1314 LoadTrailer5Front_ISig_4 24000;
BA_REL_ "GenSigTimeoutTime" BU_SG_REL_ IC3 SG_ 1314 LoadTrailer5Front_ISig_4 6000;
BA_REL_ "GenSigFirstTimeoutTime" BU_SG_REL_ IC3 SG_ 1313 LoadTrailer4_ISig_4 24000;
BA_REL_ "GenSigTimeoutTime" BU_SG_REL_ IC3 SG_ 1313 LoadTrailer4_ISig_4 6000;
BA_REL_ "GenSigFirstTimeoutTime" BU_SG_REL_ BBM SG_ 1313 LoadTrailer4_ISig_4 24000;
BA_REL_ "GenSigTimeoutTime" BU_SG_REL_ BBM SG_ 1313 LoadTrailer4_ISig_4 6000;
BA_REL_ "GenSigFirstTimeoutTime" BU_SG_REL_ CIOM SG_ 1313 LoadTrailer4_ISig_4 24000;
BA_REL_ "GenSigTimeoutTime" BU_SG_REL_ CIOM SG_ 1313 LoadTrailer4_ISig_4 6000;
BA_REL_ "GenSigFirstTimeoutTime" BU_SG_REL_ IC3 SG_ 1313 LoadTrailer3Back_ISig_4 24000;
BA_REL_ "GenSigTimeoutTime" BU_SG_REL_ IC3 SG_ 1313 LoadTrailer3Back_ISig_4 6000;
BA_REL_ "GenSigFirstTimeoutTime" BU_SG_REL_ IC3 SG_ 1313 LoadTruckRear 24000;
BA_REL_ "GenSigTimeoutTime" BU_SG_REL_ IC3 SG_ 1313 LoadTruckRear 6000;
BA_REL_ "GenSigFirstTimeoutTime" BU_SG_REL_ BBM SG_ 1313 LoadTrailer2_ISig_4 24000;
BA_REL_ "GenSigTimeoutTime" BU_SG_REL_ BBM SG_ 1313 LoadTrailer2_ISig_4 6000;
BA_REL_ "GenSigFirstTimeoutTime" BU_SG_REL_ CIOM SG_ 1313 LoadTrailer2_ISig_4 24000;
BA_REL_ "GenSigTimeoutTime" BU_SG_REL_ CIOM SG_ 1313 LoadTrailer2_ISig_4 6000;
BA_REL_ "GenSigFirstTimeoutTime" BU_SG_REL_ IC3 SG_ 1313 LoadTrailer2_ISig_4 24000;
BA_REL_ "GenSigTimeoutTime" BU_SG_REL_ IC3 SG_ 1313 LoadTrailer2_ISig_4 6000;
BA_REL_ "GenSigFirstTimeoutTime" BU_SG_REL_ IC3 SG_ 1312 CalLoadTrailer2Axle3_ISig_4 24000;
BA_REL_ "GenSigTimeoutTime" BU_SG_REL_ IC3 SG_ 1312 CalLoadTrailer2Axle3_ISig_4 6000;
BA_REL_ "GenSigFirstTimeoutTime" BU_SG_REL_ CIOM SG_ 1312 CalLoadTrailer2Axle3_ISig_4 24000;
BA_REL_ "GenSigTimeoutTime" BU_SG_REL_ CIOM SG_ 1312 CalLoadTrailer2Axle3_ISig_4 6000;
BA_REL_ "GenSigFirstTimeoutTime" BU_SG_REL_ BBM SG_ 1312 CalLoadTrailer2Axle3_ISig_4 24000;
BA_REL_ "GenSigTimeoutTime" BU_SG_REL_ BBM SG_ 1312 CalLoadTrailer2Axle3_ISig_4 6000;
BA_REL_ "GenSigFirstTimeoutTime" BU_SG_REL_ IC3 SG_ 1312 CalLoadTrailer3Axle2_ISig_4 24000;
BA_REL_ "GenSigTimeoutTime" BU_SG_REL_ IC3 SG_ 1312 CalLoadTrailer3Axle2_ISig_4 6000;
BA_REL_ "GenSigFirstTimeoutTime" BU_SG_REL_ CIOM SG_ 1312 CalLoadTrailer3Axle2_ISig_4 24000;
BA_REL_ "GenSigTimeoutTime" BU_SG_REL_ CIOM SG_ 1312 CalLoadTrailer3Axle2_ISig_4 6000;
BA_REL_ "GenSigFirstTimeoutTime" BU_SG_REL_ IC3 SG_ 1312 CalLoadTrailer3Axle6_ISig_4 24000;
BA_REL_ "GenSigTimeoutTime" BU_SG_REL_ IC3 SG_ 1312 CalLoadTrailer3Axle6_ISig_4 6000;
BA_REL_ "GenSigFirstTimeoutTime" BU_SG_REL_ CIOM SG_ 1312 CalLoadTrailer3Axle6_ISig_4 24000;
BA_REL_ "GenSigTimeoutTime" BU_SG_REL_ CIOM SG_ 1312 CalLoadTrailer3Axle6_ISig_4 6000;
BA_REL_ "GenSigFirstTimeoutTime" BU_SG_REL_ BBM SG_ 1305 LoadVehCombination_ISig_4 24000;
BA_REL_ "GenSigTimeoutTime" BU_SG_REL_ BBM SG_ 1305 LoadVehCombination_ISig_4 6000;
BA_REL_ "GenSigFirstTimeoutTime" BU_SG_REL_ IC3 SG_ 1305 LoadVehCombination_ISig_4 24000;
BA_REL_ "GenSigTimeoutTime" BU_SG_REL_ IC3 SG_ 1305 LoadVehCombination_ISig_4 6000;
BA_REL_ "GenSigFirstTimeoutTime" BU_SG_REL_ IC3 SG_ 1305 LoadTruckFront 24000;
BA_REL_ "GenSigTimeoutTime" BU_SG_REL_ IC3 SG_ 1305 LoadTruckFront 6000;
BA_REL_ "GenSigFirstTimeoutTime" BU_SG_REL_ BBM SG_ 1305 LoadVehCombCargoRel_ISig_4 24000;
BA_REL_ "GenSigTimeoutTime" BU_SG_REL_ BBM SG_ 1305 LoadVehCombCargoRel_ISig_4 6000;
BA_REL_ "GenSigFirstTimeoutTime" BU_SG_REL_ IC3 SG_ 1305 LoadVehCombCargoRel_ISig_4 24000;
BA_REL_ "GenSigTimeoutTime" BU_SG_REL_ IC3 SG_ 1305 LoadVehCombCargoRel_ISig_4 6000;
BA_REL_ "GenSigFirstTimeoutTime" BU_SG_REL_ IC3 SG_ 1305 LoadTrailer1Back_ISig_4 24000;
BA_REL_ "GenSigTimeoutTime" BU_SG_REL_ IC3 SG_ 1305 LoadTrailer1Back_ISig_4 6000;
BA_REL_ "GenSigFirstTimeoutTime" BU_SG_REL_ CIOM SG_ 1304 CalLoadTrailer3Axle4_ISig_4 24000;
BA_REL_ "GenSigTimeoutTime" BU_SG_REL_ CIOM SG_ 1304 CalLoadTrailer3Axle4_ISig_4 6000;
BA_REL_ "GenSigFirstTimeoutTime" BU_SG_REL_ IC3 SG_ 1304 CalLoadTrailer3Axle4_ISig_4 24000;
BA_REL_ "GenSigTimeoutTime" BU_SG_REL_ IC3 SG_ 1304 CalLoadTrailer3Axle4_ISig_4 6000;
BA_REL_ "GenSigFirstTimeoutTime" BU_SG_REL_ CIOM SG_ 1304 CalLoadTrailer2Axle2_ISig_4 24000;
BA_REL_ "GenSigTimeoutTime" BU_SG_REL_ CIOM SG_ 1304 CalLoadTrailer2Axle2_ISig_4 6000;
BA_REL_ "GenSigFirstTimeoutTime" BU_SG_REL_ IC3 SG_ 1304 CalLoadTrailer2Axle2_ISig_4 24000;
BA_REL_ "GenSigTimeoutTime" BU_SG_REL_ IC3 SG_ 1304 CalLoadTrailer2Axle2_ISig_4 6000;
BA_REL_ "GenSigFirstTimeoutTime" BU_SG_REL_ BBM SG_ 1304 CalLoadTrailer2Axle2_ISig_4 24000;
BA_REL_ "GenSigTimeoutTime" BU_SG_REL_ BBM SG_ 1304 CalLoadTrailer2Axle2_ISig_4 6000;
BA_REL_ "GenSigFirstTimeoutTime" BU_SG_REL_ CIOM SG_ 1304 CalLoadTrailer1Axle6_ISig_4 24000;
BA_REL_ "GenSigTimeoutTime" BU_SG_REL_ CIOM SG_ 1304 CalLoadTrailer1Axle6_ISig_4 6000;
BA_REL_ "GenSigFirstTimeoutTime" BU_SG_REL_ IC3 SG_ 1304 CalLoadTrailer1Axle6_ISig_4 24000;
BA_REL_ "GenSigTimeoutTime" BU_SG_REL_ IC3 SG_ 1304 CalLoadTrailer1Axle6_ISig_4 6000;
BA_REL_ "GenSigFirstTimeoutTime" BU_SG_REL_ CIOM SG_ 1304 CalLoadTrailer5Axle6_ISig_4 24000;
BA_REL_ "GenSigTimeoutTime" BU_SG_REL_ CIOM SG_ 1304 CalLoadTrailer5Axle6_ISig_4 6000;
BA_REL_ "GenSigFirstTimeoutTime" BU_SG_REL_ IC3 SG_ 1304 CalLoadTrailer5Axle6_ISig_4 24000;
BA_REL_ "GenSigTimeoutTime" BU_SG_REL_ IC3 SG_ 1304 CalLoadTrailer5Axle6_ISig_4 6000;
VAL_ 826 StartupProhibitStatus_ISig_4 3 "InactiveActive_NotAvailable" 2 "InactiveActive_Error" 1 "InactiveActive_Active" 0 "InactiveActive_Inactive" ;
VAL_ 826 RampLevelStatus_ISig_4 15 "RampLevelStatus_NotAvaiable" 14 "RampLevelStatus_ErrorIndicator" 13 "RampLevelStatus_NotDefined_05" 12 "RampLevelStatus_NotDefined_04" 11 "RampLevelStatus_NotDefined_03" 10 "RampLevelStatus_NotDefined_02" 9 "RampLevelStatus_NotDefined_01" 8 "RampLevelStatus_NotDefined" 7 "RampLevelStatus_RampLevelM7" 6 "RampLevelStatus_RampLevelM6" 5 "RampLevelStatus_RampLevelM5" 4 "RampLevelStatus_RampLevelM4" 3 "RampLevelStatus_RampLevelM3" 2 "RampLevelStatus_RampLevelM2" 1 "RampLevelStatus_RampLevelM1" 0 "RampLevelStatus_Inactive" ;
VAL_ 826 KneelingInformation_ISig_4 15 "KneelingInformation_NotAvailable" 14 "KneelingInformation_ErrorIndicator" 13 "KneelingInformation_NotDefined_08" 12 "KneelingInformation_NotDefined_07" 11 "KneelingInformation_NotDefined_06" 10 "KneelingInformation_NotDefined_05" 9 "KneelingInformation_NotDefined_04" 8 "KneelingInformation_NotDefined_03" 7 "KneelingInformation_NotDefined_02" 6 "KneelingInformation_NotDefined_01" 5 "KneelingInformation_NotDefined" 4 "KneelingInformation_KneelingAborted" 3 "KneelingInformation_LiftingActiveVehicleIsLiftedDueToRcvrReq" 2 "KneelingInformation_KneelLevelReachedVehicleIsAtFixeKneelLvl" 1 "KneelingInformation_LoweringActiveTheVehIsLoweredDueToKneelReq" 0 "KneelingInformation_NotActiveTheKneelingFunctionIsNotActive" ;
VAL_ 826 FrontAxleInBumperRange_ISig_4 3 "AxleInBumperRange_NotAvailable" 2 "AxleInBumperRange_ErrorIndicator" 1 "AxleInBumperRange_ActualLevelWithinBumperRange" 0 "AxleInBumperRange_ActualLevelOutOfBumperRange" ;
VAL_ 826 FerryFunctionStatus_ISig_4 7 "FerryFunctionStatus_NotAvailable" 6 "FerryFunctionStatus_Error" 5 "FerryFunctionStatus_Spare_03" 4 "FerryFunctionStatus_Spare_02" 3 "FerryFunctionStatus_Spare_01" 2 "FerryFunctionStatus_FerryFunctionActiveLeveNotlReached" 1 "FerryFunctionStatus_FerryFunctionActiveLevelReached" 0 "FerryFunctionStatus_FerryFunctionNotActive" ;
VAL_ 826 EngPtoConsumesTorque 3 "PtoTorqueRequest_NotAvailable" 2 "PtoTorqueRequest_Error" 1 "PtoTorqueRequest_PtoIsRequestingHighTorque" 0 "PtoTorqueRequest_PtoIsNotRequestingHighTorque" ;
VAL_ 826 LiftingControlModeRearAxle_ISig_ 3 "InactiveActive_NotAvailable" 2 "InactiveActive_Error" 1 "InactiveActive_Active" 0 "InactiveActive_Inactive" ;
VAL_ 826 KneelingStatusHMI_ISig_4 3 "KneelingStatusHMI_NotAvailable" 2 "KneelingStatusHMI_Error" 1 "KneelingStatusHMI_Active" 0 "KneelingStatusHMI_Inactive" ;
VAL_ 826 SWEngineStop_rqst_ISig_4 7 "SWEngineStop_rqst_NotAvailable" 6 "SWEngineStop_rqst_Error" 5 "SWEngineStop_rqst_Spare_04" 4 "SWEngineStop_rqst_Spare_03" 3 "SWEngineStop_rqst_Spare_02" 2 "SWEngineStop_rqst_Spare_01" 1 "SWEngineStop_rqst_EngineStopRequested" 0 "SWEngineStop_rqst_EngineStopNotRequested" ;
VAL_ 826 FrontEndPositionStatus_ISig_4 7 "EndPositionStatus_NotAvailable" 6 "EndPositionStatus_Error" 5 "EndPositionStatus_Reserved_01" 4 "EndPositionStatus_Reserved" 3 "EndPositionStatus_LiftingAndLoweringNotAllowed" 2 "EndPositionStatus_MinEndLevelReached" 1 "EndPositionStatus_MaxEndLevelReached" 0 "EndPositionStatus_NoEndLevelReached" ;
VAL_ 826 LiftingControlModeFrontAxle_ISig 3 "InactiveActive_NotAvailable" 2 "InactiveActive_Error" 1 "InactiveActive_Active" 0 "InactiveActive_Inactive" ;
VAL_ 826 UnevenLoadWarning_ISig_4 3 "Warning_NotAvailable" 2 "Warning_Error" 1 "Warning_Warning" 0 "Warning_NoWarning" ;
VAL_ 826 RampHeightOutsideTargetRange_ISi 7 "HeightOutsideTargetRange_NotAvailable" 6 "HeightOutsideTargetRange_Error" 5 "HeightOutsideTargetRange_NotDefined_02" 4 "HeightOutsideTargetRange_NotDefined_01" 3 "HeightOutsideTargetRange_NotDefined" 2 "HeightOutsideTargetRange_ToHigh" 1 "HeightOutsideTargetRange_ToLow" 0 "HeightOutsideTargetRange_Inactive" ;
VAL_ 826 DriveLevelPosUserInteraction_ISi 7 "DriveLevelPosUserInteraction_NotAvailable" 6 "DriveLevelPosUserInteraction_Error" 5 "DriveLevelPosUserInteraction_Spare3" 4 "DriveLevelPosUserInteraction_Spare2" 3 "DriveLevelPosUserInteraction_Spare1" 2 "DriveLevelPosUserInteraction_WarningDriveLevelPosNotSelected" 1 "DriveLevelPosUserInteraction_DriveLevelPositionNotSelected" 0 "DriveLevelPosUserInteraction_DriveLevelPositionSelected" ;
VAL_ 826 RearEndPositionStatus_ISig_4 7 "EndPositionStatus_NotAvailable" 6 "EndPositionStatus_Error" 5 "EndPositionStatus_Reserved_01" 4 "EndPositionStatus_Reserved" 3 "EndPositionStatus_LiftingAndLoweringNotAllowed" 2 "EndPositionStatus_MinEndLevelReached" 1 "EndPositionStatus_MaxEndLevelReached" 0 "EndPositionStatus_NoEndLevelReached" ;
VAL_ 826 ProhibitControlStatus_ISig_4 3 "InactiveActive_NotAvailable" 2 "InactiveActive_Error" 1 "InactiveActive_Active" 0 "InactiveActive_Inactive" ;
VAL_ 826 ChangeKneelACK_ISig_4 3 "ChangeKneelACK_NotAvailable" 2 "ChangeKneelACK_Error" 1 "ChangeKneelACK_ChangeAcknowledged" 0 "ChangeKneelACK_NoAction" ;
VAL_ 826 ParkBrakeApplicationMode2 15 "ParkBrakeApplicationMode2_NotAvailable" 14 "ParkBrakeApplicationMode2_Error" 13 "ParkBrakeApplicationMode2_Reserved5" 12 "ParkBrakeApplicationMode2_Reserved4" 11 "ParkBrakeApplicationMode2_Reserved3" 10 "ParkBrakeApplicationMode2_Reserved2" 9 "ParkBrakeApplicationMode2_Reserved1" 8 "ParkBrakeApplicationMode2_AutomaticcallyDoorOpen" 7 "ParkBrakeApplicationMode2_ParkBrakeBlending" 6 "ParkBrakeApplicationMode2_AutomaticallyHillHolder" 5 "ParkBrakeApplicationMode2_AutomaticInBackup" 4 "ParkBrakeApplicationMode2_ExternalDemand" 3 "ParkBrakeApplicationMode2_AutomaticallyKeyOff" 2 "ParkBrakeApplicationMode2_ManuallyAtStandstill" 1 "ParkBrakeApplicationMode2_ManuallyInDriving" 0 "ParkBrakeApplicationMode2_Idle" ;
VAL_ 826 RollEndPositionStatus_ISig_4 7 "RollEndPositionStatus_NotAvailable" 6 "RollEndPositionStatus_Error" 5 "RollEndPositionStatus_Reserved_01" 4 "RollEndPositionStatus_Reserved" 3 "RollEndPositionStatus_NoRollingAllowed" 2 "RollEndPositionStatus_CounterClockwiseEndLevelReached" 1 "RollEndPositionStatus_ClockwiseEndLevelReached" 0 "RollEndPositionStatus_NoEndLevelReached" ;
VAL_ 826 ParkBrakeReleaseMode2_ISig_4 15 "ParkBrakeReleaseMode2_NotAvailable" 14 "ParkBrakeReleaseMode2_Error" 13 "ParkBrakeReleaseMode2_Reserved7" 12 "ParkBrakeReleaseMode2_Reserved6" 11 "ParkBrakeReleaseMode2_Reserved5" 10 "ParkBrakeReleaseMode2_Reserved4" 9 "ParkBrakeReleaseMode2_Reserved3" 8 "ParkBrakeReleaseMode2_Reserved2" 7 "ParkBrakeReleaseMode2_Reserved1" 6 "ParkBrakeReleaseMode2_AutomaticallyinHillHolder" 5 "ParkBrakeReleaseMode2_AutomaticInBackup" 4 "ParkBrakeReleaseMode2_ExternalDemand" 3 "ParkBrakeReleaseMode2_AutomaticallyAccelPedal" 2 "ParkBrakeReleaseMode2_ManuallyAtStandstill" 1 "ParkBrakeReleaseMode2_ManuallyInDriving" 0 "ParkBrakeReleaseMode2_Idle" ;
VAL_ 826 ECSStandbyAllowed_ISig_4 3 "FalseTrue_NotAvaiable" 2 "FalseTrue_Error" 1 "FalseTrue_True" 0 "FalseTrue_False" ;
VAL_ 826 RearAxleInBumperRange_ISig_4 3 "AxleInBumperRange_NotAvailable" 2 "AxleInBumperRange_ErrorIndicator" 1 "AxleInBumperRange_ActualLevelWithinBumperRange" 0 "AxleInBumperRange_ActualLevelOutOfBumperRange" ;
VAL_ 1273 OBDDtcVMCU_EvalResult2 3 "IncompleteComplete_NotAvailable" 2 "IncompleteComplete_Error" 1 "IncompleteComplete_Complete" 0 "IncompleteComplete_Incomplete" ;
VAL_ 1273 OBDDtcVMCU_EvalStatus1 3 "IncompleteComplete_NotAvailable" 2 "IncompleteComplete_Error" 1 "IncompleteComplete_Complete" 0 "IncompleteComplete_Incomplete" ;
VAL_ 1273 OBDDtcVMCU_DrivingCycle2 3 "DrivingCycle_NotAvailable" 2 "DrivingCycle_Error" 1 "DrivingCycle_Value1" 0 "DrivingCycle_Value0" ;
VAL_ 1273 OBDDtcVMCU_DrivingCycle1 3 "DrivingCycle_NotAvailable" 2 "DrivingCycle_Error" 1 "DrivingCycle_Value1" 0 "DrivingCycle_Value0" ;
VAL_ 1273 OBDDtcVMCU_EvalStatus2 3 "IncompleteComplete_NotAvailable" 2 "IncompleteComplete_Error" 1 "IncompleteComplete_Complete" 0 "IncompleteComplete_Incomplete" ;
VAL_ 1273 OBDDtcVMCU_EvalResult1 3 "IncompleteComplete_NotAvailable" 2 "IncompleteComplete_Error" 1 "IncompleteComplete_Complete" 0 "IncompleteComplete_Incomplete" ;
VAL_ 567 DriveModeSwitchStat_Rqst 3 "OffOn_NotAvailable" 2 "OffOn_Error" 1 "OffOn_On" 0 "OffOn_Off" ;
VAL_ 567 GearLeverPosition2_Rqst 15 "GearLeverPosition_NotAvailable" 14 "GearLeverPosition_Error" 13 "GearLeverPosition_SpareValue_06" 12 "GearLeverPosition_SpareValue_05" 11 "GearLeverPosition_SpareValue_04" 10 "GearLeverPosition_SpareValue_03" 9 "GearLeverPosition_SpareValue_02" 8 "GearLeverPosition_SpareValue_01" 7 "GearLeverPosition_SpareValue" 6 "GearLeverPosition_SEG6" 5 "GearLeverPosition_LowGear" 4 "GearLeverPosition_Manual" 3 "GearLeverPosition_Automatic" 2 "GearLeverPosition_Neutral" 1 "GearLeverPosition_Reverse" 0 "GearLeverPosition_GearFoldedAway" ;
VAL_ 567 UpDownShiftRqst_Rqst 15 "UpDownShiftRequest_NotAvailable" 14 "UpDownShiftRequest_Error" 13 "UpDownShiftRequest_Spare7" 12 "UpDownShiftRequest_Spare6" 11 "UpDownShiftRequest_Spare5" 10 "UpDownShiftRequest_Spare4" 9 "UpDownShiftRequest_Spare3" 8 "UpDownShiftRequest_Spare2" 7 "UpDownShiftRequest_Spare1" 6 "UpDownShiftRequest_DownShiftThreeSteps" 5 "UpDownShiftRequest_DownShiftTwoSteps" 4 "UpDownShiftRequest_DownShiftOneStep" 3 "UpDownShiftRequest_UpShiftThreeSteps" 2 "UpDownShiftRequest_UpShiftTwoSteps" 1 "UpDownShiftRequest_UpShiftOneStep" 0 "UpDownShiftRequest_NoRequest" ;
VAL_ 1482 CalDataLoadTrlAxSumP2_VehicleID 7 "TrailerIDEnum_NotAvailable" 6 "TrailerIDEnum_Error" 5 "TrailerIDEnum_Spare" 4 "TrailerIDEnum_Trailer5" 3 "TrailerIDEnum_Trailer4" 2 "TrailerIDEnum_Trailer3" 1 "TrailerIDEnum_Trailer2" 0 "TrailerIDEnum_Trailer1" ;
VAL_ 1406 CalDataLoadTrlAxSumP1_VehicleID 7 "TrailerIDEnum_NotAvailable" 6 "TrailerIDEnum_Error" 5 "TrailerIDEnum_Spare" 4 "TrailerIDEnum_Trailer5" 3 "TrailerIDEnum_Trailer4" 2 "TrailerIDEnum_Trailer3" 1 "TrailerIDEnum_Trailer2" 0 "TrailerIDEnum_Trailer1" ;
VAL_ 1169 ConnectedTrailer1_Calibrated 7 "CalibratedStatus_NotAvailable" 6 "CalibratedStatus_Error" 5 "CalibratedStatus_Spare3" 4 "CalibratedStatus_Spare2" 3 "CalibratedStatus_Spare1" 2 "CalibratedStatus_FullyCalibrated" 1 "CalibratedStatus_PartiallyCalibrated" 0 "CalibratedStatus_Uncalibrated" ;
VAL_ 1169 ConnectedTrailer3_Calibrated 7 "CalibratedStatus_NotAvailable" 6 "CalibratedStatus_Error" 5 "CalibratedStatus_Spare3" 4 "CalibratedStatus_Spare2" 3 "CalibratedStatus_Spare1" 2 "CalibratedStatus_FullyCalibrated" 1 "CalibratedStatus_PartiallyCalibrated" 0 "CalibratedStatus_Uncalibrated" ;
VAL_ 1169 ConnectedTrailer4_Calibrated 7 "CalibratedStatus_NotAvailable" 6 "CalibratedStatus_Error" 5 "CalibratedStatus_Spare3" 4 "CalibratedStatus_Spare2" 3 "CalibratedStatus_Spare1" 2 "CalibratedStatus_FullyCalibrated" 1 "CalibratedStatus_PartiallyCalibrated" 0 "CalibratedStatus_Uncalibrated" ;
VAL_ 1169 ConnectedTrailer5_Calibrated 7 "CalibratedStatus_NotAvailable" 6 "CalibratedStatus_Error" 5 "CalibratedStatus_Spare3" 4 "CalibratedStatus_Spare2" 3 "CalibratedStatus_Spare1" 2 "CalibratedStatus_FullyCalibrated" 1 "CalibratedStatus_PartiallyCalibrated" 0 "CalibratedStatus_Uncalibrated" ;
VAL_ 1169 ConnectedTrailer2_Calibrated 7 "CalibratedStatus_NotAvailable" 6 "CalibratedStatus_Error" 5 "CalibratedStatus_Spare3" 4 "CalibratedStatus_Spare2" 3 "CalibratedStatus_Spare1" 2 "CalibratedStatus_FullyCalibrated" 1 "CalibratedStatus_PartiallyCalibrated" 0 "CalibratedStatus_Uncalibrated" ;
VAL_ 1596 SavedUnit20_TrailerPosition 7 "TrailerPosition_NotAvailable" 6 "TrailerPosition_Error" 5 "TrailerPosition_Trailer5" 4 "TrailerPosition_Trailer4" 3 "TrailerPosition_Trailer3" 2 "TrailerPosition_Trailer2" 1 "TrailerPosition_Trailer1" 0 "TrailerPosition_NotConnected" ;
VAL_ 1594 SavedUnit19_TrailerPosition 7 "TrailerPosition_NotAvailable" 6 "TrailerPosition_Error" 5 "TrailerPosition_Trailer5" 4 "TrailerPosition_Trailer4" 3 "TrailerPosition_Trailer3" 2 "TrailerPosition_Trailer2" 1 "TrailerPosition_Trailer1" 0 "TrailerPosition_NotConnected" ;
VAL_ 1592 SavedUnit18_TrailerPosition 7 "TrailerPosition_NotAvailable" 6 "TrailerPosition_Error" 5 "TrailerPosition_Trailer5" 4 "TrailerPosition_Trailer4" 3 "TrailerPosition_Trailer3" 2 "TrailerPosition_Trailer2" 1 "TrailerPosition_Trailer1" 0 "TrailerPosition_NotConnected" ;
VAL_ 1590 SavedUnit17_TrailerPosition 7 "TrailerPosition_NotAvailable" 6 "TrailerPosition_Error" 5 "TrailerPosition_Trailer5" 4 "TrailerPosition_Trailer4" 3 "TrailerPosition_Trailer3" 2 "TrailerPosition_Trailer2" 1 "TrailerPosition_Trailer1" 0 "TrailerPosition_NotConnected" ;
VAL_ 1588 SavedUnit16_TrailerPosition 7 "TrailerPosition_NotAvailable" 6 "TrailerPosition_Error" 5 "TrailerPosition_Trailer5" 4 "TrailerPosition_Trailer4" 3 "TrailerPosition_Trailer3" 2 "TrailerPosition_Trailer2" 1 "TrailerPosition_Trailer1" 0 "TrailerPosition_NotConnected" ;
VAL_ 1586 SavedUnit15_TrailerPosition 7 "TrailerPosition_NotAvailable" 6 "TrailerPosition_Error" 5 "TrailerPosition_Trailer5" 4 "TrailerPosition_Trailer4" 3 "TrailerPosition_Trailer3" 2 "TrailerPosition_Trailer2" 1 "TrailerPosition_Trailer1" 0 "TrailerPosition_NotConnected" ;
VAL_ 1584 SavedUnit14_TrailerPosition 7 "TrailerPosition_NotAvailable" 6 "TrailerPosition_Error" 5 "TrailerPosition_Trailer5" 4 "TrailerPosition_Trailer4" 3 "TrailerPosition_Trailer3" 2 "TrailerPosition_Trailer2" 1 "TrailerPosition_Trailer1" 0 "TrailerPosition_NotConnected" ;
VAL_ 1576 SavedUnit13_TrailerPosition 7 "TrailerPosition_NotAvailable" 6 "TrailerPosition_Error" 5 "TrailerPosition_Trailer5" 4 "TrailerPosition_Trailer4" 3 "TrailerPosition_Trailer3" 2 "TrailerPosition_Trailer2" 1 "TrailerPosition_Trailer1" 0 "TrailerPosition_NotConnected" ;
VAL_ 1574 SavedUnit12_TrailerPosition 7 "TrailerPosition_NotAvailable" 6 "TrailerPosition_Error" 5 "TrailerPosition_Trailer5" 4 "TrailerPosition_Trailer4" 3 "TrailerPosition_Trailer3" 2 "TrailerPosition_Trailer2" 1 "TrailerPosition_Trailer1" 0 "TrailerPosition_NotConnected" ;
VAL_ 1572 SavedUnit11_TrailerPosition 7 "TrailerPosition_NotAvailable" 6 "TrailerPosition_Error" 5 "TrailerPosition_Trailer5" 4 "TrailerPosition_Trailer4" 3 "TrailerPosition_Trailer3" 2 "TrailerPosition_Trailer2" 1 "TrailerPosition_Trailer1" 0 "TrailerPosition_NotConnected" ;
VAL_ 1570 SavedUnit10_TrailerPosition 7 "TrailerPosition_NotAvailable" 6 "TrailerPosition_Error" 5 "TrailerPosition_Trailer5" 4 "TrailerPosition_Trailer4" 3 "TrailerPosition_Trailer3" 2 "TrailerPosition_Trailer2" 1 "TrailerPosition_Trailer1" 0 "TrailerPosition_NotConnected" ;
VAL_ 1568 SavedUnit9_TrailerPosition 7 "TrailerPosition_NotAvailable" 6 "TrailerPosition_Error" 5 "TrailerPosition_Trailer5" 4 "TrailerPosition_Trailer4" 3 "TrailerPosition_Trailer3" 2 "TrailerPosition_Trailer2" 1 "TrailerPosition_Trailer1" 0 "TrailerPosition_NotConnected" ;
VAL_ 1566 SavedUnit8_TrailerPosition 7 "TrailerPosition_NotAvailable" 6 "TrailerPosition_Error" 5 "TrailerPosition_Trailer5" 4 "TrailerPosition_Trailer4" 3 "TrailerPosition_Trailer3" 2 "TrailerPosition_Trailer2" 1 "TrailerPosition_Trailer1" 0 "TrailerPosition_NotConnected" ;
VAL_ 1564 SavedUnit7_TrailerPosition 7 "TrailerPosition_NotAvailable" 6 "TrailerPosition_Error" 5 "TrailerPosition_Trailer5" 4 "TrailerPosition_Trailer4" 3 "TrailerPosition_Trailer3" 2 "TrailerPosition_Trailer2" 1 "TrailerPosition_Trailer1" 0 "TrailerPosition_NotConnected" ;
VAL_ 1562 SavedUnit6_TrailerPosition 7 "TrailerPosition_NotAvailable" 6 "TrailerPosition_Error" 5 "TrailerPosition_Trailer5" 4 "TrailerPosition_Trailer4" 3 "TrailerPosition_Trailer3" 2 "TrailerPosition_Trailer2" 1 "TrailerPosition_Trailer1" 0 "TrailerPosition_NotConnected" ;
VAL_ 1560 SavedUnit5_TrailerPosition 7 "TrailerPosition_NotAvailable" 6 "TrailerPosition_Error" 5 "TrailerPosition_Trailer5" 4 "TrailerPosition_Trailer4" 3 "TrailerPosition_Trailer3" 2 "TrailerPosition_Trailer2" 1 "TrailerPosition_Trailer1" 0 "TrailerPosition_NotConnected" ;
VAL_ 1558 SavedUnit4_TrailerPosition 7 "TrailerPosition_NotAvailable" 6 "TrailerPosition_Error" 5 "TrailerPosition_Trailer5" 4 "TrailerPosition_Trailer4" 3 "TrailerPosition_Trailer3" 2 "TrailerPosition_Trailer2" 1 "TrailerPosition_Trailer1" 0 "TrailerPosition_NotConnected" ;
VAL_ 1556 SavedUnit3_TrailerPosition 7 "TrailerPosition_NotAvailable" 6 "TrailerPosition_Error" 5 "TrailerPosition_Trailer5" 4 "TrailerPosition_Trailer4" 3 "TrailerPosition_Trailer3" 2 "TrailerPosition_Trailer2" 1 "TrailerPosition_Trailer1" 0 "TrailerPosition_NotConnected" ;
VAL_ 1554 SavedUnit2_TrailerPosition 7 "TrailerPosition_NotAvailable" 6 "TrailerPosition_Error" 5 "TrailerPosition_Trailer5" 4 "TrailerPosition_Trailer4" 3 "TrailerPosition_Trailer3" 2 "TrailerPosition_Trailer2" 1 "TrailerPosition_Trailer1" 0 "TrailerPosition_NotConnected" ;
VAL_ 1552 SavedUnit1_TrailerPosition 7 "TrailerPosition_NotAvailable" 6 "TrailerPosition_Error" 5 "TrailerPosition_Trailer5" 4 "TrailerPosition_Trailer4" 3 "TrailerPosition_Trailer3" 2 "TrailerPosition_Trailer2" 1 "TrailerPosition_Trailer1" 0 "TrailerPosition_NotConnected" ;
VAL_ 1293 EventTimerAck_Oper 7 "TimerOper_NotAvailable" 6 "TimerOper_Error" 5 "TimerOper_Spare3" 4 "TimerOper_Spare2" 3 "TimerOper_Spare1" 2 "TimerOper_ResetTimer" 1 "TimerOper_StartTimer" 0 "TimerOper_NoAction" ;
VAL_ 1293 LoadDistributionSelected2_ISig_4 15 "LoadDistributionSelected2_NotAvailable" 14 "LoadDistributionSelected2_Error" 13 "LoadDistributionSelected2_Reserved_01" 12 "LoadDistributionSelected2_TractionHelp2InterDiff" 11 "LoadDistributionSelected2_StartingHelp2InterDiff" 10 "LoadDistributionSelected2_TractionHelp2" 9 "LoadDistributionSelected2_StartingHelp2" 8 "LoadDistributionSelected2_VariableAxleLoad" 7 "LoadDistributionSelected2_NoLoadDistribution" 6 "LoadDistributionSelected2_TractionHelpInterDiff" 5 "LoadDistributionSelected2_StartingHelpInterDiff" 4 "LoadDistributionSelected2_AlternativeLoad" 3 "LoadDistributionSelected2_TractionHelp" 2 "LoadDistributionSelected2_StartingHelp" 1 "LoadDistributionSelected2_OptimisedTraction" 0 "LoadDistributionSelected2_NormalLoad" ;
VAL_ 1293 RSLAssistStatus 7 "RSLAssistStatus_NotAvailable" 6 "RSLAssistStatus_Error" 5 "RSLAssistStatus_Spare2" 4 "RSLAssistStatus_Spare1" 3 "RSLAssistStatus_PreActive" 2 "RSLAssistStatus_Active" 1 "RSLAssistStatus_Enable" 0 "RSLAssistStatus_Disable" ;
VAL_ 1271 DayOfWeek_stat_ISig_4 15 "DayOfWeek_NotAvailable" 14 "DayOfWeek_Error" 13 "DayOfWeek_Spare_7" 12 "DayOfWeek_Spare_6" 11 "DayOfWeek_Spare_5" 10 "DayOfWeek_Spare_4" 9 "DayOfWeek_Spare_3" 8 "DayOfWeek_Spare_2" 7 "DayOfWeek_Spare_1" 6 "DayOfWeek_Sunday" 5 "DayOfWeek_Saturday" 4 "DayOfWeek_Friday" 3 "DayOfWeek_Thursday" 2 "DayOfWeek_Wednesday" 1 "DayOfWeek_Tuesday" 0 "DayOfWeek_Monday" ;
VAL_ 1271 SelectedDaylightSaving_stat 3 "DaylightSaving_NotAvailable" 2 "DaylightSaving_Error" 1 "DaylightSaving_DaylightSaving" 0 "DaylightSaving_Standard" ;
VAL_ 1271 SavedHeightControlMode_ISig_4 3 "SavedHeightControlMode_NotAvailable" 2 "SavedHeightControlMode_Error" 1 "SavedHeightControlMode_Drive" 0 "SavedHeightControlMode_Manual" ;
VAL_ 391 RequestedUpshiftDownshiftSteps 7 "RequestedUpshiftDownshiftSteps_NotAvailable" 6 "RequestedUpshiftDownshiftSteps_Error" 5 "RequestedUpshiftDownshiftSteps_NotDefined_01" 4 "RequestedUpshiftDownshiftSteps_NotDefined" 3 "RequestedUpshiftDownshiftSteps_ThreeSteps" 2 "RequestedUpshiftDownshiftSteps_TwoSteps" 1 "RequestedUpshiftDownshiftSteps_OneStep" 0 "RequestedUpshiftDownshiftSteps_NoRequest" ;
VAL_ 391 GearLeverPosition_ISig_4 15 "GearLeverPosition_NotAvailable" 14 "GearLeverPosition_Error" 13 "GearLeverPosition_SpareValue_06" 12 "GearLeverPosition_SpareValue_05" 11 "GearLeverPosition_SpareValue_04" 10 "GearLeverPosition_SpareValue_03" 9 "GearLeverPosition_SpareValue_02" 8 "GearLeverPosition_SpareValue_01" 7 "GearLeverPosition_SpareValue" 6 "GearLeverPosition_SEG6" 5 "GearLeverPosition_LowGear" 4 "GearLeverPosition_Manual" 3 "GearLeverPosition_Automatic" 2 "GearLeverPosition_Neutral" 1 "GearLeverPosition_Reverse" 0 "GearLeverPosition_GearFoldedAway" ;
VAL_ 391 DownShiftRequest 3 "DownShiftRequest_NotAvailable" 2 "DownShiftRequest_Error" 1 "DownShiftRequest_RequestToDownshiftOneGear" 0 "DownShiftRequest_NoRequest" ;
VAL_ 391 UpShiftRequest 3 "UpShiftRequest_NotAvailable" 2 "UpShiftRequest_Error" 1 "UpShiftRequest_RequestToDoUpshiftOneStep" 0 "UpShiftRequest_NoRequest" ;
VAL_ 391 LimpHomeSwitch_stat 3 "OffOn_NotAvailable" 2 "OffOn_Error" 1 "OffOn_On" 0 "OffOn_Off" ;
VAL_ 391 RequestForHighestGearRatio 3 "Request_NotAvailable" 2 "Request_Error" 1 "Request_RequestActive" 0 "Request_NotRequested" ;
VAL_ 391 EconomyPowerSwitch_stat 3 "OffOn_NotAvailable" 2 "OffOn_Error" 1 "OffOn_On" 0 "OffOn_Off" ;
VAL_ 1321 CalDataLoadP5_VehicleID_ISig_4 7 "VehicleID_NotAvailable" 6 "VehicleID_Error" 5 "VehicleID_Trailer5" 4 "VehicleID_Trailer4" 3 "VehicleID_Trailer3" 2 "VehicleID_Trailer2" 1 "VehicleID_Trailer1" 0 "VehicleID_Truck" ;
VAL_ 1321 CalDataLoadP5_AxleID_ISig_4 15 "AxleIdEnum_NotAvailable" 14 "AxleIdEnum_Error" 13 "AxleIdEnum_Reserved8" 12 "AxleIdEnum_Reserved7" 11 "AxleIdEnum_Reserved6" 10 "AxleIdEnum_Reserved5" 9 "AxleIdEnum_Reserved4" 8 "AxleIdEnum_Reserved3" 7 "AxleIdEnum_Reserved2" 6 "AxleIdEnum_Reserved1" 5 "AxleIdEnum_AxleID6" 4 "AxleIdEnum_AxleID5" 3 "AxleIdEnum_AxleID4" 2 "AxleIdEnum_AxleID3" 1 "AxleIdEnum_AxleID2" 0 "AxleIdEnum_AxleID1" ;
VAL_ 1320 CalDataLoadP4_AxleID_ISig_4 15 "AxleIdEnum_NotAvailable" 14 "AxleIdEnum_Error" 13 "AxleIdEnum_Reserved8" 12 "AxleIdEnum_Reserved7" 11 "AxleIdEnum_Reserved6" 10 "AxleIdEnum_Reserved5" 9 "AxleIdEnum_Reserved4" 8 "AxleIdEnum_Reserved3" 7 "AxleIdEnum_Reserved2" 6 "AxleIdEnum_Reserved1" 5 "AxleIdEnum_AxleID6" 4 "AxleIdEnum_AxleID5" 3 "AxleIdEnum_AxleID4" 2 "AxleIdEnum_AxleID3" 1 "AxleIdEnum_AxleID2" 0 "AxleIdEnum_AxleID1" ;
VAL_ 1320 CalDataLoadP4_VehicleID_ISig_4 7 "VehicleID_NotAvailable" 6 "VehicleID_Error" 5 "VehicleID_Trailer5" 4 "VehicleID_Trailer4" 3 "VehicleID_Trailer3" 2 "VehicleID_Trailer2" 1 "VehicleID_Trailer1" 0 "VehicleID_Truck" ;
VAL_ 1319 CalDataLoadP3_VehicleID_ISig_4 7 "VehicleID_NotAvailable" 6 "VehicleID_Error" 5 "VehicleID_Trailer5" 4 "VehicleID_Trailer4" 3 "VehicleID_Trailer3" 2 "VehicleID_Trailer2" 1 "VehicleID_Trailer1" 0 "VehicleID_Truck" ;
VAL_ 1319 CalDataLoadP3_AxleID_ISig_4 15 "AxleIdEnum_NotAvailable" 14 "AxleIdEnum_Error" 13 "AxleIdEnum_Reserved8" 12 "AxleIdEnum_Reserved7" 11 "AxleIdEnum_Reserved6" 10 "AxleIdEnum_Reserved5" 9 "AxleIdEnum_Reserved4" 8 "AxleIdEnum_Reserved3" 7 "AxleIdEnum_Reserved2" 6 "AxleIdEnum_Reserved1" 5 "AxleIdEnum_AxleID6" 4 "AxleIdEnum_AxleID5" 3 "AxleIdEnum_AxleID4" 2 "AxleIdEnum_AxleID3" 1 "AxleIdEnum_AxleID2" 0 "AxleIdEnum_AxleID1" ;
VAL_ 1318 CalDataLoadP2_AxleID_ISig_4 15 "AxleIdEnum_NotAvailable" 14 "AxleIdEnum_Error" 13 "AxleIdEnum_Reserved8" 12 "AxleIdEnum_Reserved7" 11 "AxleIdEnum_Reserved6" 10 "AxleIdEnum_Reserved5" 9 "AxleIdEnum_Reserved4" 8 "AxleIdEnum_Reserved3" 7 "AxleIdEnum_Reserved2" 6 "AxleIdEnum_Reserved1" 5 "AxleIdEnum_AxleID6" 4 "AxleIdEnum_AxleID5" 3 "AxleIdEnum_AxleID4" 2 "AxleIdEnum_AxleID3" 1 "AxleIdEnum_AxleID2" 0 "AxleIdEnum_AxleID1" ;
VAL_ 1318 CalDataLoadP2_VehicleID_ISig_4 7 "VehicleID_NotAvailable" 6 "VehicleID_Error" 5 "VehicleID_Trailer5" 4 "VehicleID_Trailer4" 3 "VehicleID_Trailer3" 2 "VehicleID_Trailer2" 1 "VehicleID_Trailer1" 0 "VehicleID_Truck" ;
VAL_ 1317 CalDataLoadP1_AxleID_ISig_4 15 "AxleIdEnum_NotAvailable" 14 "AxleIdEnum_Error" 13 "AxleIdEnum_Reserved8" 12 "AxleIdEnum_Reserved7" 11 "AxleIdEnum_Reserved6" 10 "AxleIdEnum_Reserved5" 9 "AxleIdEnum_Reserved4" 8 "AxleIdEnum_Reserved3" 7 "AxleIdEnum_Reserved2" 6 "AxleIdEnum_Reserved1" 5 "AxleIdEnum_AxleID6" 4 "AxleIdEnum_AxleID5" 3 "AxleIdEnum_AxleID4" 2 "AxleIdEnum_AxleID3" 1 "AxleIdEnum_AxleID2" 0 "AxleIdEnum_AxleID1" ;
VAL_ 1317 CalDataLoadP1_VehicleID_ISig_4 7 "VehicleID_NotAvailable" 6 "VehicleID_Error" 5 "VehicleID_Trailer5" 4 "VehicleID_Trailer4" 3 "VehicleID_Trailer3" 2 "VehicleID_Trailer2" 1 "VehicleID_Trailer1" 0 "VehicleID_Truck" ;
VAL_ 1053 AlarmClockAlarms_stat_Mode 3 "AlarmClkMode_Spare" 2 "AlarmClkMode_Timer" 1 "AlarmClkMode_Recurrent" 0 "AlarmClkMode_OneTime" ;
VAL_ 1053 AlarmClockAlarms_stat_Type 7 "AlarmClkType_NotAvailable" 6 "AlarmClkType_Error" 5 "AlarmClkType_Reserved_02" 4 "AlarmClkType_Reserved_01" 3 "AlarmClkType_Reserved" 2 "AlarmClkType_Radio" 1 "AlarmClkType_Buzzer" 0 "AlarmClkType_NoAudibleNotification" ;
VAL_ 1053 AlarmClockAlarms_stat_ID 127 "AlarmClkID_NotAvailable" 126 "AlarmClkID_Error" 10 "AlarmClkID_Alarm10" 9 "AlarmClkID_Alarm9" 8 "AlarmClkID_Alarm8" 7 "AlarmClkID_Alarm7" 6 "AlarmClkID_Alarm6" 5 "AlarmClkID_Alarm5" 4 "AlarmClkID_Alarm4" 3 "AlarmClkID_Alarm3" 2 "AlarmClkID_Alarm2" 1 "AlarmClkID_Alarm1" 0 "AlarmClkID_NotUsed" ;
VAL_ 1053 AlarmClockAlarms_stat_Stat 3 "AlarmClkStat2_Snoozed" 2 "AlarmClkStat2_Ringing" 1 "AlarmClkStat2_Active" 0 "AlarmClkStat2_Inactive" ;
VAL_ 1053 AlmClkCurAlarm_stat_Stat 3 "AlarmClkStat_Spare" 2 "AlarmClkStat_NoUsed" 1 "AlarmClkStat_Active" 0 "AlarmClkStat_Inactive" ;
VAL_ 1053 AlmClkCurAlarm_stat_ID 127 "AlarmClkID_NotAvailable" 126 "AlarmClkID_Error" 10 "AlarmClkID_Alarm10" 9 "AlarmClkID_Alarm9" 8 "AlarmClkID_Alarm8" 7 "AlarmClkID_Alarm7" 6 "AlarmClkID_Alarm6" 5 "AlarmClkID_Alarm5" 4 "AlarmClkID_Alarm4" 3 "AlarmClkID_Alarm3" 2 "AlarmClkID_Alarm2" 1 "AlarmClkID_Alarm1" 0 "AlarmClkID_NotUsed" ;
VAL_ 1053 AlmClkCurAlarm_stat_Type 7 "AlarmClkType_NotAvailable" 6 "AlarmClkType_Error" 5 "AlarmClkType_Reserved_02" 4 "AlarmClkType_Reserved_01" 3 "AlarmClkType_Reserved" 2 "AlarmClkType_Radio" 1 "AlarmClkType_Buzzer" 0 "AlarmClkType_NoAudibleNotification" ;
VAL_ 1095 HVChrgnAlld 3 "NotAllowedAllowed_NotAvailable" 2 "NotAllowedAllowed_Error" 1 "NotAllowedAllowed_Allowed" 0 "NotAllowedAllowed_NotAllowed" ;
VAL_ 1095 ParkHeaterTimerReleased_stat_ISi 3 "DisableEnable_NotAvailable" 2 "DisableEnable_Error" 1 "DisableEnable_Enable" 0 "DisableEnable_Disable" ;
VAL_ 1095 PHTimerRqstAck_CurrentOp_ISig_4 3 "CurrentOp_NotAvailable" 2 "CurrentOp_Disabled" 1 "CurrentOp_TemporaryStopped" 0 "CurrentOp_Running" ;
VAL_ 1095 PHTimerRqstAck_DayOfWeekRq_ISig_ 15 "DayOfWeekRq_NotAvailable" 14 "DayOfWeekRq_Error" 13 "DayOfWeekRq_Spare_7" 12 "DayOfWeekRq_Spare_6" 11 "DayOfWeekRq_Spare_5" 10 "DayOfWeekRq_Spare_4" 9 "DayOfWeekRq_Spare_3" 8 "DayOfWeekRq_Spare_2" 7 "DayOfWeekRq_NoDay" 6 "DayOfWeekRq_Sunday" 5 "DayOfWeekRq_Saturday" 4 "DayOfWeekRq_Friday" 3 "DayOfWeekRq_Thursday" 2 "DayOfWeekRq_Wednesday" 1 "DayOfWeekRq_Tuesday" 0 "DayOfWeekRq_Monday" ;
VAL_ 1095 AlarmClockNotification_Stat_ISig 3 "AlarmClkStat_Spare" 2 "AlarmClkStat_NoUsed" 1 "AlarmClkStat_Active" 0 "AlarmClkStat_Inactive" ;
VAL_ 1095 AlarmClockNotification_Type_ISig 7 "AlarmClkType_NotAvailable" 6 "AlarmClkType_Error" 5 "AlarmClkType_Reserved_02" 4 "AlarmClkType_Reserved_01" 3 "AlarmClkType_Reserved" 2 "AlarmClkType_Radio" 1 "AlarmClkType_Buzzer" 0 "AlarmClkType_NoAudibleNotification" ;
VAL_ 1095 AlarmClockNotification_ID_ISig_4 127 "AlarmClkID_NotAvailable" 126 "AlarmClkID_Error" 10 "AlarmClkID_Alarm10" 9 "AlarmClkID_Alarm9" 8 "AlarmClkID_Alarm8" 7 "AlarmClkID_Alarm7" 6 "AlarmClkID_Alarm6" 5 "AlarmClkID_Alarm5" 4 "AlarmClkID_Alarm4" 3 "AlarmClkID_Alarm3" 2 "AlarmClkID_Alarm2" 1 "AlarmClkID_Alarm1" 0 "AlarmClkID_NotUsed" ;
VAL_ 1316 LoadIndCalWarning_Movement_ISig_ 3 "InactiveActive_NotAvailable" 2 "InactiveActive_Error" 1 "InactiveActive_Active" 0 "InactiveActive_Inactive" ;
VAL_ 1316 LoadIndCalWarning_LiftedAxle_ISi 3 "InactiveActive_NotAvailable" 2 "InactiveActive_Error" 1 "InactiveActive_Active" 0 "InactiveActive_Inactive" ;
VAL_ 1316 LoadIndCalWarning_LowSupplyPress 3 "InactiveActive_NotAvailable" 2 "InactiveActive_Error" 1 "InactiveActive_Active" 0 "InactiveActive_Inactive" ;
VAL_ 1316 LoadIndCalWarning_PBrakeApplied_ 3 "InactiveActive_NotAvailable" 2 "InactiveActive_Error" 1 "InactiveActive_Active" 0 "InactiveActive_Inactive" ;
VAL_ 1316 LoadIndCalWarning_SBrakesApplied 3 "InactiveActive_NotAvailable" 2 "InactiveActive_Error" 1 "InactiveActive_Active" 0 "InactiveActive_Inactive" ;
VAL_ 1316 LoadIndCalWarning_HighInclin_ISi 3 "InactiveActive_NotAvailable" 2 "InactiveActive_Error" 1 "InactiveActive_Active" 0 "InactiveActive_Inactive" ;
VAL_ 1316 LoadIndCalWarning_GearNotNeutral 3 "InactiveActive_NotAvailable" 2 "InactiveActive_Error" 1 "InactiveActive_Active" 0 "InactiveActive_Inactive" ;
SIG_GROUP_ 1273 OBDDtcVMCU_sg 1 : OBDDtcVMCU_SPN2_B2 OBDDtcVMCU_SPN1_3msb OBDDtcVMCU_SPN2_3msb OBDDtcVMCU_EvalResult2 OBDDtcVMCU_SPN1_B1 OBDDtcVMCU_EvalStatus1 OBDDtcVMCU_DrivingCycle2 OBDDtcVMCU_SPN2_B1 OBDDtcVMCU_DrivingCycle1 OBDDtcVMCU_SPN1_B2 OBDDtcVMCU_FMI1 OBDDtcVMCU_EvalStatus2 OBDDtcVMCU_FMI2 OBDDtcVMCU_EvalResult1;
SIG_GROUP_ 567 UpDownShiftRqst_sg 1 : UpDownShiftRqst_CRC UpDownShiftRqst_SqC UpDownShiftRqst_Rqst;
SIG_GROUP_ 567 DriveModeSwitchStat_sg 1 : DriveModeSwitchStat_Rqst DriveModeSwitchStat_CRC DriveModeSwitchStat_SqC;
SIG_GROUP_ 567 GearLeverPosition2_sg 1 : GearLeverPosition2_SqC GearLeverPosition2_Rqst GearLeverPosition2_CRC;
SIG_GROUP_ 1482 CalDataLoadTrlAxSumP2_sg 1 : CalDataLoadTrlAxSumP2_YearUTC CalDataLoadTrlAxSumP2_ScaleLoad CalDataLoadTrlAxSumP2_DayUTC CalDataLoadTrlAxSumP2_VehicleID CalDataLoadTrlAxSumP2_QF CalDataLoadTrlAxSumP2_MonthUTC CalDataLoadTrlAxSumP2_UncalLoad;
SIG_GROUP_ 1406 CalDataLoadTrlAxSumP1_sg 1 : CalDataLoadTrlAxSumP1_DayUTC CalDataLoadTrlAxSumP1_YearUTC CalDataLoadTrlAxSumP1_VehicleID CalDataLoadTrlAxSumP1_ScaleLoad CalDataLoadTrlAxSumP1_MonthUTC CalDataLoadTrlAxSumP1_UncalLoad CalDataLoadTrlAxSumP1_QF;
SIG_GROUP_ 1169 ConnectedTrailer2_sg 1 : ConnectedTrailer2_MemPosition ConnectedTrailer2_Calibrated;
SIG_GROUP_ 1169 ConnectedTrailer5_sg 1 : ConnectedTrailer5_Calibrated ConnectedTrailer5_MemPosition;
SIG_GROUP_ 1169 ConnectedTrailer3_sg 1 : ConnectedTrailer3_Calibrated ConnectedTrailer3_MemPosition;
SIG_GROUP_ 1169 ConnectedTrailer1_sg 1 : ConnectedTrailer1_Calibrated ConnectedTrailer1_MemPosition;
SIG_GROUP_ 1169 ConnectedTrailer4_sg 1 : ConnectedTrailer4_Calibrated ConnectedTrailer4_MemPosition;
SIG_GROUP_ 1596 SavedUnit20_sg 1 : SavedUnit20_TrailerName SavedUnit20_TrailerPosition;
SIG_GROUP_ 1594 SavedUnit19_sg 1 : SavedUnit19_TrailerName SavedUnit19_TrailerPosition;
SIG_GROUP_ 1592 SavedUnit18_sg 1 : SavedUnit18_TrailerPosition SavedUnit18_TrailerName;
SIG_GROUP_ 1590 SavedUnit17_sg 1 : SavedUnit17_TrailerPosition SavedUnit17_TrailerName;
SIG_GROUP_ 1588 SavedUnit16_sg 1 : SavedUnit16_TrailerName SavedUnit16_TrailerPosition;
SIG_GROUP_ 1586 SavedUnit15_sg 1 : SavedUnit15_TrailerName SavedUnit15_TrailerPosition;
SIG_GROUP_ 1584 SavedUnit14_sg 1 : SavedUnit14_TrailerPosition SavedUnit14_TrailerName;
SIG_GROUP_ 1576 SavedUnit13_sg 1 : SavedUnit13_TrailerPosition SavedUnit13_TrailerName;
SIG_GROUP_ 1574 SavedUnit12_sg 1 : SavedUnit12_TrailerName SavedUnit12_TrailerPosition;
SIG_GROUP_ 1572 SavedUnit11_sg 1 : SavedUnit11_TrailerPosition SavedUnit11_TrailerName;
SIG_GROUP_ 1570 SavedUnit10_sg 1 : SavedUnit10_TrailerName SavedUnit10_TrailerPosition;
SIG_GROUP_ 1568 SavedUnit9_sg 1 : SavedUnit9_TrailerName SavedUnit9_TrailerPosition;
SIG_GROUP_ 1566 SavedUnit8_sg 1 : SavedUnit8_TrailerName SavedUnit8_TrailerPosition;
SIG_GROUP_ 1564 SavedUnit7_sg 1 : SavedUnit7_TrailerPosition SavedUnit7_TrailerName;
SIG_GROUP_ 1562 SavedUnit6_sg 1 : SavedUnit6_TrailerPosition SavedUnit6_TrailerName;
SIG_GROUP_ 1560 SavedUnit5_sg 1 : SavedUnit5_TrailerName SavedUnit5_TrailerPosition;
SIG_GROUP_ 1558 SavedUnit4_sg 1 : SavedUnit4_TrailerPosition SavedUnit4_TrailerName;
SIG_GROUP_ 1556 SavedUnit3_sg 1 : SavedUnit3_TrailerPosition SavedUnit3_TrailerName;
SIG_GROUP_ 1554 SavedUnit2_sg 1 : SavedUnit2_TrailerName SavedUnit2_TrailerPosition;
SIG_GROUP_ 1552 SavedUnit1_sg 1 : SavedUnit1_TrailerPosition SavedUnit1_TrailerName;
SIG_GROUP_ 1293 EventTimerTrig_sg 1 : EventTimerTrig_Id;
SIG_GROUP_ 1293 EventTimerAck_sg 1 : EventTimerAck_Oper EventTimerAck_Time EventTimerAck_Id;
SIG_GROUP_ 1321 CalDataLoadP5_sg_ISig_4 1 : CalDataLoadP5_ScaleLoad_ISig_4 CalDataLoadP5_UncalLoad_ISig_4 CalDataLoadP5_YearUTC_ISig_4 CalDataLoadP5_VehicleID_ISig_4 CalDataLoadP5_AxleID_ISig_4 CalDataLoadP5_DayUTC_ISig_4 CalDataLoadP5_HoursUTC_ISig_4 CalDataLoadP5_MinutesUTC_ISig_4 CalDataLoadP5_QF_ISig_4 CalDataLoadP5_MonthUTC_ISig_4;
SIG_GROUP_ 1320 CalDataLoadP4_sg_ISig_4 1 : CalDataLoadP4_DayUTC_ISig_4 CalDataLoadP4_ScaleLoad_ISig_4 CalDataLoadP4_YearUTC_ISig_4 CalDataLoadP4_AxleID_ISig_4 CalDataLoadP4_UncalLoad_ISig_4 CalDataLoadP4_VehicleID_ISig_4 CalDataLoadP4_MinutesUTC_ISig_4 CalDataLoadP4_HoursUTC_ISig_4 CalDataLoadP4_MonthUTC_ISig_4 CalDataLoadP4_QF_ISig_4;
SIG_GROUP_ 1319 CalDataLoadP3_sg_ISig_4 1 : CalDataLoadP3_HoursUTC_ISig_4 CalDataLoadP3_YearUTC_ISig_4 CalDataLoadP3_MonthUTC_ISig_4 CalDataLoadP3_DayUTC_ISig_4 CalDataLoadP3_MinutesUTC_ISig_4 CalDataLoadP3_QF_ISig_4 CalDataLoadP3_VehicleID_ISig_4 CalDataLoadP3_UncalLoad_ISig_4 CalDataLoadP3_AxleID_ISig_4 CalDataLoadP3_ScaleLoad_ISig_4;
SIG_GROUP_ 1318 CalDataLoadP2_sg_ISig_4 1 : CalDataLoadP2_MinutesUTC_ISig_4 CalDataLoadP2_AxleID_ISig_4 CalDataLoadP2_YearUTC_ISig_4 CalDataLoadP2_UncalLoad_ISig_4 CalDataLoadP2_DayUTC_ISig_4 CalDataLoadP2_MonthUTC_ISig_4 CalDataLoadP2_VehicleID_ISig_4 CalDataLoadP2_QF_ISig_4 CalDataLoadP2_HoursUTC_ISig_4 CalDataLoadP2_ScaleLoad_ISig_4;
SIG_GROUP_ 1317 CalDataLoadP1_sg_ISig_4 1 : CalDataLoadP1_ScaleLoad_ISig_4 CalDataLoadP1_YearUTC_ISig_4 CalDataLoadP1_AxleID_ISig_4 CalDataLoadP1_MonthUTC_ISig_4 CalDataLoadP1_HoursUTC_ISig_4 CalDataLoadP1_VehicleID_ISig_4 CalDataLoadP1_UncalLoad_ISig_4 CalDataLoadP1_QF_ISig_4 CalDataLoadP1_DayUTC_ISig_4 CalDataLoadP1_MinutesUTC_ISig_4;
SIG_GROUP_ 1053 AlmClkCurAlarm_stat_sg 1 : AlmClkCurAlarm_stat_SetMin AlmClkCurAlarm_stat_Stat AlmClkCurAlarm_stat_ID AlmClkCurAlarm_stat_Type AlmClkCurAlarm_stat_SetHr;
SIG_GROUP_ 1053 AlarmClockAlarms_stat_sg 1 : AlarmClockAlarms_stat_Mode AlarmClockAlarms_stat_Type AlarmClockAlarms_stat_DaySet AlarmClockAlarms_stat_ID AlarmClockAlarms_stat_Stat AlarmClockAlarms_stat_SetMin AlarmClockAlarms_stat_SetHr;
SIG_GROUP_ 1095 AlarmClockNotification_sg_ISig_4 1 : AlarmClockNotification_Stat_ISig AlarmClockNotification_Type_ISig AlarmClockNotification_ID_ISig_4;
SIG_GROUP_ 1095 PHTimerRqstAck_sg_ISig_4 1 : PHTimerRqstAck_Hours_ISig_4 PHTimerRqstAck_CurrentOp_ISig_4 PHTimerRqstAck_DayOfWeekRq_ISig_ PHTimerRqstAck_Minutes_ISig_4;
SIG_GROUP_ 1316 LoadIndCalWarning_sg_ISig_4 1 : LoadIndCalWarning_Movement_ISig_ LoadIndCalWarning_LiftedAxle_ISi LoadIndCalWarning_LowSupplyPress LoadIndCalWarning_PBrakeApplied_ LoadIndCalWarning_SBrakesApplied LoadIndCalWarning_HighInclin_ISi LoadIndCalWarning_GearNotNeutral;
